VERSION ""

NS_ :

BS_:

BU_: Instrumentation Vehicle ESR
VAL_TABLE_ VOLVO_SHORT_TRACK_PLANT 1 "Gent" 0 "Torslanda" ;
VAL_TABLE_ Grating_Lobe 1 "Detected" 0 "Not_Detected" ;
VAL_TABLE_ GroupingChanged 1 "GroupingChanged" 0 "GroupingUnchanged" ;
VAL_TABLE_ Oncoming 1 "Oncoming" 0 "NotOncoming" ;
VAL_TABLE_ UPDATED 1 "Updated" 0 "Not_Updated" ;
VAL_TABLE_ FOUND_TARGET 1 "Found" 0 "Not_Found" ;
VAL_TABLE_ FACTORY_ALIGN_STATUS 5 "FAIL_VAR_TOO_LARGE" 4 "FAIL_DEV_TOO_LARGE" 3 "FAIL_NO_TARGET" 2 "SUCCESS" 1 "BUSY" 0 "OFF" ;
VAL_TABLE_ RECOMMEND 1 "Recommend" 0 "Not_Recommend" ;
VAL_TABLE_ SA_TYPE 1 "VOLVO_SHORT_TRACK" 0 "AUTO_OR_DEALER" ;
VAL_TABLE_ ENABLE 1 "Enabled" 0 "Disabled" ;
VAL_TABLE_ CONVERGED 1 "Converged" 0 "Not_Converged" ;
VAL_TABLE_ WHEEL_SLIP 3 "Invalid_3" 2 "Traction_Slip_Control" 1 "Brake_Slip_Control" 0 "No_Control" ;
VAL_TABLE_ TURN_SIGNAL_STATUS 3 "Invalid_3" 2 "Right" 1 "Left" 0 "Off" ;
VAL_TABLE_ DISABLE 1 "Disabled" 0 "Enabled" ;
VAL_TABLE_ SYSTEM_POWER_MODE 7 "7invalid" 6 "TEST" 5 "HOST_SHUTDOWN" 4 "DSP_OFF" 3 "DSP_SHUTDOWN" 2 "RADIATE_ON" 1 "RADIATE_OFF" 0 "DSP_INIT" ;
VAL_TABLE_ Water_Spray_Detected 1 "Spray" 0 "No_Spray" ;
VAL_TABLE_ Bridge 1 "Bridge" 0 "Not_Bridge" ;
VAL_TABLE_ MED_RANGE_MODE 3 "Both_MR_LR_Update" 2 "LR_Update_Only" 1 "MR_Update_Only" 0 "No_MR_LR_Update" ;
VAL_TABLE_ Interface_Version 15 "zInvalid0F" 14 "zInvalid0E" 13 "zInvalid0D" 12 "zInvalid0C" 11 "zInvalid0B" 10 "zInvalid0A" 9 "zInvalid09" 8 "zInvalid08" 7 "zInvalid07" 6 "zInvalid06" 5 "zInvalid05" 4 "zInvalid04" 3 "zInvalid03" 2 "zInvalid02" 1 "ADP_DV1" 0 "TDP" ;
VAL_TABLE_ SIM_STATUS 3 "Coasted" 2 "Updated" 1 "New" 0 "Invalid" ;
VAL_TABLE_ SIM_TRACK_ID 2 "Target_2" 1 "Target_1" 0 "No_Target" ;
VAL_TABLE_ SIM_FUNCTION 7 "All_Stat_RI_FCW_CMbB" 6 "All_Moving_ACC_FCW_CMbB" 5 "CMbB_Stat" 4 "CMbB_Move" 3 "FCW_Stat" 2 "FCW_Move" 1 "RI" 0 "ACC" ;
VAL_TABLE_ UPSIDE_DOWN 1 "Upside_Down" 0 "Right_Side_Up" ;
VAL_TABLE_ MR_LR_MODE 3 "Output MR and LR tracks" 2 "Output only LR-range tracks" 1 "Output only MR-range tracks" 0 "Reserved" ;
VAL_TABLE_ GROUP 3 "Group4" 2 "Group3" 1 "Group2" 0 "Group1" ;
VAL_TABLE_ NODETECT_DETECT 1 "Detect" 0 "No_Detect" ;
VAL_TABLE_ TRACK_STATUS 7 "New_Coasted_Target" 6 "Invalid_Coasted_Target" 5 "Merged_Target" 4 "Coasted_Target" 3 "Updated_Target" 2 "New_Updated_Target" 1 "New_Target" 0 "No_Target" ;
VAL_TABLE_ NOTCROSSING_CROSSING 1 "Crossing" 0 "Not_Crossing" ;
VAL_TABLE_ NOTMOVABLE_MOVABLE 1 "Movable" 0 "Not_Movable" ;
VAL_TABLE_ STATIONARY_MOVING 1 "Moving" 0 "Stationary" ;
VAL_TABLE_ NOTOVERTEMP_OVERTEMP 1 "OverTemp" 0 "Not OverTemp" ;
VAL_TABLE_ NOTBLOCKED_BLOCKED 1 "Blocked" 0 "Not Blocked" ;
VAL_TABLE_ NOTFAIL_FAIL 1 "Failed" 0 "Not Failed" ;
VAL_TABLE_ UNGROUPED_GROUPED 3 "Group_Moving_Stationary" 2 "Group_Stationary_Only" 1 "Group_Moving_Only" 0 "No_Grouping" ;
VAL_TABLE_ FILTERED_RAW 1 "Raw" 0 "Filtered" ;
VAL_TABLE_ OFF_ON 1 "On" 0 "Off" ;
VAL_TABLE_ SW_SIGN 1 "Clockwise" 0 "Counterclockwise" ;
VAL_TABLE_ VALIDITY 1 "Valid" 0 "Invalid" ;
VAL_TABLE_ VEHICLE_SPEED_DIRECTION 1 "Reverse" 0 "Forward" ;

BO_ 3221225472 VECTOR__INDEPENDENT_SIG_MSG: 0 Vector__XXX
 SG_ ITS_DAQ1_data : 0|64@0+ (1,0) [0|0] "" Vector__XXX
 SG_ CAN_RX_MR_LR_MODE : 0|2@0+ (1,0) [0|3] "" Vector__XXX
 SG_ CAN_TX_DELTA_TIME_STAMP : 0|7@0- (1,0) [-64|63] "ms" Vector__XXX
 SG_ CAN_RX_MASTER_CLOCK : 0|16@0+ (1,0) [0|65535] "ms" Vector__XXX
 SG_ CAN_TX_TRACK_LAT_RATE : 0|6@0- (0.25,0) [-8|7.75] "" Vector__XXX
 SG_ CAN_TX_TRACK_BRIDGE_OBJECT : 0|1@0+ (1,0) [0|0] "" Vector__XXX
 SG_ CAN_TX_TRACK_WIDTH : 0|4@0+ (0.5,0) [0|7.5] "m" Vector__XXX
 SG_ CAN_TX_TRACK_STATUS : 0|3@0+ (1,0) [0|7] "" Vector__XXX
 SG_ CAN_TX_TRACK_ROLLING_COUNT : 0|1@0+ (1,0) [0|1] "" Vector__XXX
 SG_ CAN_TX_TRACK_RANGE_RATE : 0|14@0- (0.01,0) [-81.92|81.91] "m/s" Vector__XXX
 SG_ CAN_TX_TRACK_RANGE_ACCEL : 0|10@0- (0.05,0) [-25.6|25.55] "m/s/s" Vector__XXX
 SG_ CAN_TX_TRACK_RANGE : 0|11@0+ (0.1,0) [0|204.7] "m" Vector__XXX
 SG_ CAN_TX_TRACK_MED_RANGE_MODE : 0|2@0+ (1,0) [0|3] "" Vector__XXX
 SG_ CAN_TX_TRACK_ANGLE : 0|10@0- (0.1,0) [-51.2|51.1] "deg" Vector__XXX
 SG_ CAN_TX_TRACK_LAT_RATE : 0|6@0- (0.25,0) [-8|7.75] "" Vector__XXX
 SG_ CAN_TX_TRACK_BRIDGE_OBJECT : 0|1@0+ (1,0) [0|0] "" Vector__XXX
 SG_ CAN_TX_TRACK_WIDTH : 0|4@0+ (0.5,0) [0|7.5] "m" Vector__XXX
 SG_ CAN_TX_TRACK_STATUS : 0|3@0+ (1,0) [0|7] "" Vector__XXX
 SG_ CAN_TX_TRACK_ROLLING_COUNT : 0|1@0+ (1,0) [0|1] "" Vector__XXX
 SG_ CAN_TX_TRACK_RANGE_RATE : 0|14@0- (0.01,0) [-81.92|81.91] "m/s" Vector__XXX
 SG_ CAN_TX_TRACK_RANGE_ACCEL : 0|10@0- (0.05,0) [-25.6|25.55] "m/s/s" Vector__XXX
 SG_ CAN_TX_TRACK_RANGE : 0|11@0+ (0.1,0) [0|204.7] "m" Vector__XXX
 SG_ CAN_TX_TRACK_MED_RANGE_MODE : 0|2@0+ (1,0) [0|3] "" Vector__XXX
 SG_ CAN_TX_TRACK_ANGLE : 0|10@0- (0.1,0) [-51.2|51.1] "deg" Vector__XXX
 SG_ CAN_TX_TRACK_LAT_RATE : 0|6@0- (0.25,0) [-8|7.75] "" Vector__XXX
 SG_ CAN_TX_TRACK_BRIDGE_OBJECT : 0|1@0+ (1,0) [0|0] "" Vector__XXX
 SG_ CAN_TX_TRACK_WIDTH : 0|4@0+ (0.5,0) [0|7.5] "m" Vector__XXX
 SG_ CAN_TX_TRACK_STATUS : 0|3@0+ (1,0) [0|7] "" Vector__XXX
 SG_ CAN_TX_TRACK_ROLLING_COUNT : 0|1@0+ (1,0) [0|1] "" Vector__XXX
 SG_ CAN_TX_TRACK_RANGE_RATE : 0|14@0- (0.01,0) [-81.92|81.91] "m/s" Vector__XXX
 SG_ CAN_TX_TRACK_RANGE_ACCEL : 0|10@0- (0.05,0) [-25.6|25.55] "m/s/s" Vector__XXX
 SG_ CAN_TX_TRACK_RANGE : 0|11@0+ (0.1,0) [0|204.7] "m" Vector__XXX
 SG_ CAN_TX_TRACK_MED_RANGE_MODE : 0|2@0+ (1,0) [0|3] "" Vector__XXX
 SG_ CAN_TX_TRACK_ANGLE : 0|10@0- (0.1,0) [-51.2|51.1] "deg" Vector__XXX
 SG_ CAN_TX_TRACK_LAT_RATE : 0|6@0- (0.25,0) [-8|7.75] "" Vector__XXX
 SG_ CAN_TX_TRACK_BRIDGE_OBJECT : 0|1@0+ (1,0) [0|0] "" Vector__XXX
 SG_ CAN_TX_TRACK_WIDTH : 0|4@0+ (0.5,0) [0|7.5] "m" Vector__XXX
 SG_ CAN_TX_TRACK_STATUS : 0|3@0+ (1,0) [0|7] "" Vector__XXX
 SG_ CAN_TX_TRACK_ROLLING_COUNT : 0|1@0+ (1,0) [0|1] "" Vector__XXX
 SG_ CAN_TX_TRACK_RANGE_RATE : 0|14@0- (0.01,0) [-81.92|81.91] "m/s" Vector__XXX
 SG_ CAN_TX_TRACK_RANGE_ACCEL : 0|10@0- (0.05,0) [-25.6|25.55] "m/s/s" Vector__XXX
 SG_ CAN_TX_TRACK_RANGE : 0|11@0+ (0.1,0) [0|204.7] "m" Vector__XXX
 SG_ CAN_TX_TRACK_MED_RANGE_MODE : 0|2@0+ (1,0) [0|3] "" Vector__XXX
 SG_ CAN_TX_TRACK_ANGLE : 0|10@0- (0.1,0) [-51.2|51.1] "deg" Vector__XXX
 SG_ CAN_TX_TRACK_LAT_RATE : 0|6@0- (0.25,0) [-8|7.75] "" Vector__XXX
 SG_ CAN_TX_TRACK_BRIDGE_OBJECT : 0|1@0+ (1,0) [0|0] "" Vector__XXX
 SG_ CAN_TX_TRACK_WIDTH : 0|4@0+ (0.5,0) [0|7.5] "m" Vector__XXX
 SG_ CAN_TX_TRACK_STATUS : 0|3@0+ (1,0) [0|7] "" Vector__XXX
 SG_ CAN_TX_TRACK_ROLLING_COUNT : 0|1@0+ (1,0) [0|1] "" Vector__XXX
 SG_ CAN_TX_TRACK_RANGE_RATE : 0|14@0- (0.01,0) [-81.92|81.91] "m/s" Vector__XXX
 SG_ CAN_TX_TRACK_RANGE_ACCEL : 0|10@0- (0.05,0) [-25.6|25.55] "m/s/s" Vector__XXX
 SG_ CAN_TX_TRACK_RANGE : 0|11@0+ (0.1,0) [0|204.7] "m" Vector__XXX
 SG_ CAN_TX_TRACK_MED_RANGE_MODE : 0|2@0+ (1,0) [0|3] "" Vector__XXX
 SG_ CAN_TX_TRACK_ANGLE : 0|10@0- (0.1,0) [-51.2|51.1] "deg" Vector__XXX
 SG_ CAN_TX_TRACK_LAT_RATE : 0|6@0- (0.25,0) [-8|7.75] "" Vector__XXX
 SG_ CAN_TX_TRACK_BRIDGE_OBJECT : 0|1@0+ (1,0) [0|0] "" Vector__XXX
 SG_ CAN_TX_TRACK_WIDTH : 0|4@0+ (0.5,0) [0|7.5] "m" Vector__XXX
 SG_ CAN_TX_TRACK_STATUS : 0|3@0+ (1,0) [0|7] "" Vector__XXX
 SG_ CAN_TX_TRACK_ROLLING_COUNT : 0|1@0+ (1,0) [0|1] "" Vector__XXX
 SG_ CAN_TX_TRACK_RANGE_RATE : 0|14@0- (0.01,0) [-81.92|81.91] "m/s" Vector__XXX
 SG_ CAN_TX_TRACK_RANGE_ACCEL : 0|10@0- (0.05,0) [-25.6|25.55] "m/s/s" Vector__XXX
 SG_ CAN_TX_TRACK_RANGE : 0|11@0+ (0.1,0) [0|204.7] "m" Vector__XXX
 SG_ CAN_TX_TRACK_MED_RANGE_MODE : 0|2@0+ (1,0) [0|3] "" Vector__XXX
 SG_ CAN_TX_TRACK_ANGLE : 0|10@0- (0.1,0) [-51.2|51.1] "deg" Vector__XXX
 SG_ CAN_TX_TRACK_LAT_RATE : 0|6@0- (0.25,0) [-8|7.75] "" Vector__XXX
 SG_ CAN_TX_TRACK_BRIDGE_OBJECT : 0|1@0+ (1,0) [0|0] "" Vector__XXX
 SG_ CAN_TX_TRACK_WIDTH : 0|4@0+ (0.5,0) [0|7.5] "m" Vector__XXX
 SG_ CAN_TX_TRACK_STATUS : 0|3@0+ (1,0) [0|7] "" Vector__XXX
 SG_ CAN_TX_TRACK_ROLLING_COUNT : 0|1@0+ (1,0) [0|1] "" Vector__XXX
 SG_ CAN_TX_TRACK_RANGE_RATE : 0|14@0- (0.01,0) [-81.92|81.91] "m/s" Vector__XXX
 SG_ CAN_TX_TRACK_RANGE_ACCEL : 0|10@0- (0.05,0) [-25.6|25.55] "m/s/s" Vector__XXX
 SG_ CAN_TX_TRACK_RANGE : 0|11@0+ (0.1,0) [0|204.7] "m" Vector__XXX
 SG_ CAN_TX_TRACK_MED_RANGE_MODE : 0|2@0+ (1,0) [0|3] "" Vector__XXX
 SG_ CAN_TX_TRACK_ANGLE : 0|10@0- (0.1,0) [-51.2|51.1] "deg" Vector__XXX
 SG_ CAN_TX_TRACK_LAT_RATE : 0|6@0- (0.25,0) [-8|7.75] "" Vector__XXX
 SG_ CAN_TX_TRACK_BRIDGE_OBJECT : 0|1@0+ (1,0) [0|0] "" Vector__XXX
 SG_ CAN_TX_TRACK_WIDTH : 0|4@0+ (0.5,0) [0|7.5] "m" Vector__XXX
 SG_ CAN_TX_TRACK_STATUS : 0|3@0+ (1,0) [0|7] "" Vector__XXX
 SG_ CAN_TX_TRACK_ROLLING_COUNT : 0|1@0+ (1,0) [0|1] "" Vector__XXX
 SG_ CAN_TX_TRACK_RANGE_RATE : 0|14@0- (0.01,0) [-81.92|81.91] "m/s" Vector__XXX
 SG_ CAN_TX_TRACK_RANGE_ACCEL : 0|10@0- (0.05,0) [-25.6|25.55] "m/s/s" Vector__XXX
 SG_ CAN_TX_TRACK_RANGE : 0|11@0+ (0.1,0) [0|204.7] "m" Vector__XXX
 SG_ CAN_TX_TRACK_MED_RANGE_MODE : 0|2@0+ (1,0) [0|3] "" Vector__XXX
 SG_ CAN_TX_TRACK_ANGLE : 0|10@0- (0.1,0) [-51.2|51.1] "deg" Vector__XXX
 SG_ CAN_TX_TRACK_LAT_RATE : 0|6@0- (0.25,0) [-8|7.75] "" Vector__XXX
 SG_ CAN_TX_TRACK_BRIDGE_OBJECT : 0|1@0+ (1,0) [0|0] "" Vector__XXX
 SG_ CAN_TX_TRACK_WIDTH : 0|4@0+ (0.5,0) [0|7.5] "m" Vector__XXX
 SG_ CAN_TX_TRACK_STATUS : 0|3@0+ (1,0) [0|7] "" Vector__XXX
 SG_ CAN_TX_TRACK_ROLLING_COUNT : 0|1@0+ (1,0) [0|1] "" Vector__XXX
 SG_ CAN_TX_TRACK_RANGE_RATE : 0|14@0- (0.01,0) [-81.92|81.91] "m/s" Vector__XXX
 SG_ CAN_TX_TRACK_RANGE_ACCEL : 0|10@0- (0.05,0) [-25.6|25.55] "m/s/s" Vector__XXX
 SG_ CAN_TX_TRACK_RANGE : 0|11@0+ (0.1,0) [0|204.7] "m" Vector__XXX
 SG_ CAN_TX_TRACK_MED_RANGE_MODE : 0|2@0+ (1,0) [0|3] "" Vector__XXX
 SG_ CAN_TX_TRACK_ANGLE : 0|10@0- (0.1,0) [-51.2|51.1] "deg" Vector__XXX
 SG_ CAN_TX_TRACK_LAT_RATE : 0|6@0- (0.25,0) [-8|7.75] "" Vector__XXX
 SG_ CAN_TX_TRACK_BRIDGE_OBJECT : 0|1@0+ (1,0) [0|0] "" Vector__XXX
 SG_ CAN_TX_TRACK_WIDTH : 0|4@0+ (0.5,0) [0|7.5] "m" Vector__XXX
 SG_ CAN_TX_TRACK_STATUS : 0|3@0+ (1,0) [0|7] "" Vector__XXX
 SG_ CAN_TX_TRACK_ROLLING_COUNT : 0|1@0+ (1,0) [0|1] "" Vector__XXX
 SG_ CAN_TX_TRACK_RANGE_RATE : 0|14@0- (0.01,0) [-81.92|81.91] "m/s" Vector__XXX
 SG_ CAN_TX_TRACK_RANGE_ACCEL : 0|10@0- (0.05,0) [-25.6|25.55] "m/s/s" Vector__XXX
 SG_ CAN_TX_TRACK_RANGE : 0|11@0+ (0.1,0) [0|204.7] "m" Vector__XXX
 SG_ CAN_TX_TRACK_MED_RANGE_MODE : 0|2@0+ (1,0) [0|3] "" Vector__XXX
 SG_ CAN_TX_TRACK_ANGLE : 0|10@0- (0.1,0) [-51.2|51.1] "deg" Vector__XXX
 SG_ CAN_TX_TRACK_LAT_RATE : 0|6@0- (0.25,0) [-8|7.75] "" Vector__XXX
 SG_ CAN_TX_TRACK_BRIDGE_OBJECT : 0|1@0+ (1,0) [0|0] "" Vector__XXX
 SG_ CAN_TX_TRACK_WIDTH : 0|4@0+ (0.5,0) [0|7.5] "m" Vector__XXX
 SG_ CAN_TX_TRACK_STATUS : 0|3@0+ (1,0) [0|7] "" Vector__XXX
 SG_ CAN_TX_TRACK_ROLLING_COUNT : 0|1@0+ (1,0) [0|1] "" Vector__XXX
 SG_ CAN_TX_TRACK_RANGE_RATE : 0|14@0- (0.01,0) [-81.92|81.91] "m/s" Vector__XXX
 SG_ CAN_TX_TRACK_RANGE_ACCEL : 0|10@0- (0.05,0) [-25.6|25.55] "m/s/s" Vector__XXX
 SG_ CAN_TX_TRACK_RANGE : 0|11@0+ (0.1,0) [0|204.7] "m" Vector__XXX
 SG_ CAN_TX_TRACK_MED_RANGE_MODE : 0|2@0+ (1,0) [0|3] "" Vector__XXX
 SG_ CAN_TX_TRACK_ANGLE : 0|10@0- (0.1,0) [-51.2|51.1] "deg" Vector__XXX
 SG_ CAN_TX_TRACK_LAT_RATE : 0|6@0- (0.25,0) [-8|7.75] "" Vector__XXX
 SG_ CAN_TX_TRACK_BRIDGE_OBJECT : 0|1@0+ (1,0) [0|0] "" Vector__XXX
 SG_ CAN_TX_TRACK_WIDTH : 0|4@0+ (0.5,0) [0|7.5] "m" Vector__XXX
 SG_ CAN_TX_TRACK_STATUS : 0|3@0+ (1,0) [0|7] "" Vector__XXX
 SG_ CAN_TX_TRACK_ROLLING_COUNT : 0|1@0+ (1,0) [0|1] "" Vector__XXX
 SG_ CAN_TX_TRACK_RANGE_RATE : 0|14@0- (0.01,0) [-81.92|81.91] "m/s" Vector__XXX
 SG_ CAN_TX_TRACK_RANGE_ACCEL : 0|10@0- (0.05,0) [-25.6|25.55] "m/s/s" Vector__XXX
 SG_ CAN_TX_TRACK_RANGE : 0|11@0+ (0.1,0) [0|204.7] "m" Vector__XXX
 SG_ CAN_TX_TRACK_MED_RANGE_MODE : 0|2@0+ (1,0) [0|3] "" Vector__XXX
 SG_ CAN_TX_TRACK_ANGLE : 0|10@0- (0.1,0) [-51.2|51.1] "deg" Vector__XXX
 SG_ CAN_TX_TRACK_LAT_RATE : 0|6@0- (0.25,0) [-8|7.75] "" Vector__XXX
 SG_ CAN_TX_TRACK_BRIDGE_OBJECT : 0|1@0+ (1,0) [0|0] "" Vector__XXX
 SG_ CAN_TX_TRACK_WIDTH : 0|4@0+ (0.5,0) [0|7.5] "m" Vector__XXX
 SG_ CAN_TX_TRACK_STATUS : 0|3@0+ (1,0) [0|7] "" Vector__XXX
 SG_ CAN_TX_TRACK_ROLLING_COUNT : 0|1@0+ (1,0) [0|1] "" Vector__XXX
 SG_ CAN_TX_TRACK_RANGE_RATE : 0|14@0- (0.01,0) [-81.92|81.91] "m/s" Vector__XXX
 SG_ CAN_TX_TRACK_RANGE_ACCEL : 0|10@0- (0.05,0) [-25.6|25.55] "m/s/s" Vector__XXX
 SG_ CAN_TX_TRACK_RANGE : 0|11@0+ (0.1,0) [0|204.7] "m" Vector__XXX
 SG_ CAN_TX_TRACK_MED_RANGE_MODE : 0|2@0+ (1,0) [0|3] "" Vector__XXX
 SG_ CAN_TX_TRACK_ANGLE : 0|10@0- (0.1,0) [-51.2|51.1] "deg" Vector__XXX
 SG_ CAN_TX_TRACK_LAT_RATE : 0|6@0- (0.25,0) [-8|7.75] "" Vector__XXX
 SG_ CAN_TX_TRACK_BRIDGE_OBJECT : 0|1@0+ (1,0) [0|0] "" Vector__XXX
 SG_ CAN_TX_TRACK_WIDTH : 0|4@0+ (0.5,0) [0|7.5] "m" Vector__XXX
 SG_ CAN_TX_TRACK_STATUS : 0|3@0+ (1,0) [0|7] "" Vector__XXX
 SG_ CAN_TX_TRACK_ROLLING_COUNT : 0|1@0+ (1,0) [0|1] "" Vector__XXX
 SG_ CAN_TX_TRACK_RANGE_RATE : 0|14@0- (0.01,0) [-81.92|81.91] "m/s" Vector__XXX
 SG_ CAN_TX_TRACK_RANGE_ACCEL : 0|10@0- (0.05,0) [-25.6|25.55] "m/s/s" Vector__XXX
 SG_ CAN_TX_TRACK_RANGE : 0|11@0+ (0.1,0) [0|204.7] "m" Vector__XXX
 SG_ CAN_TX_TRACK_MED_RANGE_MODE : 0|2@0+ (1,0) [0|3] "" Vector__XXX
 SG_ CAN_TX_TRACK_ANGLE : 0|10@0- (0.1,0) [-51.2|51.1] "deg" Vector__XXX
 SG_ CAN_TX_TRACK_LAT_RATE : 0|6@0- (0.25,0) [-8|7.75] "" Vector__XXX
 SG_ CAN_TX_TRACK_BRIDGE_OBJECT : 0|1@0+ (1,0) [0|0] "" Vector__XXX
 SG_ CAN_TX_TRACK_WIDTH : 0|4@0+ (0.5,0) [0|7.5] "m" Vector__XXX
 SG_ CAN_TX_TRACK_STATUS : 0|3@0+ (1,0) [0|7] "" Vector__XXX
 SG_ CAN_TX_TRACK_ROLLING_COUNT : 0|1@0+ (1,0) [0|1] "" Vector__XXX
 SG_ CAN_TX_TRACK_RANGE_RATE : 0|14@0- (0.01,0) [-81.92|81.91] "m/s" Vector__XXX
 SG_ CAN_TX_TRACK_RANGE_ACCEL : 0|10@0- (0.05,0) [-25.6|25.55] "m/s/s" Vector__XXX
 SG_ CAN_TX_TRACK_RANGE : 0|11@0+ (0.1,0) [0|204.7] "m" Vector__XXX
 SG_ CAN_TX_TRACK_MED_RANGE_MODE : 0|2@0+ (1,0) [0|3] "" Vector__XXX
 SG_ CAN_TX_TRACK_ANGLE : 0|10@0- (0.1,0) [-51.2|51.1] "deg" Vector__XXX
 SG_ CAN_TX_TRACK_LAT_RATE : 0|6@0- (0.25,0) [-8|7.75] "" Vector__XXX
 SG_ CAN_TX_TRACK_BRIDGE_OBJECT : 0|1@0+ (1,0) [0|0] "" Vector__XXX
 SG_ CAN_TX_TRACK_WIDTH : 0|4@0+ (0.5,0) [0|7.5] "m" Vector__XXX
 SG_ CAN_TX_TRACK_STATUS : 0|3@0+ (1,0) [0|7] "" Vector__XXX
 SG_ CAN_TX_TRACK_ROLLING_COUNT : 0|1@0+ (1,0) [0|1] "" Vector__XXX
 SG_ CAN_TX_TRACK_RANGE_RATE : 0|14@0- (0.01,0) [-81.92|81.91] "m/s" Vector__XXX
 SG_ CAN_TX_TRACK_RANGE_ACCEL : 0|10@0- (0.05,0) [-25.6|25.55] "m/s/s" Vector__XXX
 SG_ CAN_TX_TRACK_RANGE : 0|11@0+ (0.1,0) [0|204.7] "m" Vector__XXX
 SG_ CAN_TX_TRACK_MED_RANGE_MODE : 0|2@0+ (1,0) [0|3] "" Vector__XXX
 SG_ CAN_TX_TRACK_ANGLE : 0|10@0- (0.1,0) [-51.2|51.1] "deg" Vector__XXX
 SG_ CAN_TX_TRACK_LAT_RATE : 0|6@0- (0.25,0) [-8|7.75] "" Vector__XXX
 SG_ CAN_TX_TRACK_BRIDGE_OBJECT : 0|1@0+ (1,0) [0|0] "" Vector__XXX
 SG_ CAN_TX_TRACK_WIDTH : 0|4@0+ (0.5,0) [0|7.5] "m" Vector__XXX
 SG_ CAN_TX_TRACK_STATUS : 0|3@0+ (1,0) [0|7] "" Vector__XXX
 SG_ CAN_TX_TRACK_ROLLING_COUNT : 0|1@0+ (1,0) [0|1] "" Vector__XXX
 SG_ CAN_TX_TRACK_RANGE_RATE : 0|14@0- (0.01,0) [-81.92|81.91] "m/s" Vector__XXX
 SG_ CAN_TX_TRACK_RANGE_ACCEL : 0|10@0- (0.05,0) [-25.6|25.55] "m/s/s" Vector__XXX
 SG_ CAN_TX_TRACK_RANGE : 0|11@0+ (0.1,0) [0|204.7] "m" Vector__XXX
 SG_ CAN_TX_TRACK_MED_RANGE_MODE : 0|2@0+ (1,0) [0|3] "" Vector__XXX
 SG_ CAN_TX_TRACK_ANGLE : 0|10@0- (0.1,0) [-51.2|51.1] "deg" Vector__XXX
 SG_ CAN_TX_TRACK_LAT_RATE : 0|6@0- (0.25,0) [-8|7.75] "" Vector__XXX
 SG_ CAN_TX_TRACK_BRIDGE_OBJECT : 0|1@0+ (1,0) [0|0] "" Vector__XXX
 SG_ CAN_TX_TRACK_WIDTH : 0|4@0+ (0.5,0) [0|7.5] "m" Vector__XXX
 SG_ CAN_TX_TRACK_STATUS : 0|3@0+ (1,0) [0|7] "" Vector__XXX
 SG_ CAN_TX_TRACK_ROLLING_COUNT : 0|1@0+ (1,0) [0|1] "" Vector__XXX
 SG_ CAN_TX_TRACK_RANGE_RATE : 0|14@0- (0.01,0) [-81.92|81.91] "m/s" Vector__XXX
 SG_ CAN_TX_TRACK_RANGE_ACCEL : 0|10@0- (0.05,0) [-25.6|25.55] "m/s/s" Vector__XXX
 SG_ CAN_TX_TRACK_RANGE : 0|11@0+ (0.1,0) [0|204.7] "m" Vector__XXX
 SG_ CAN_TX_TRACK_MED_RANGE_MODE : 0|2@0+ (1,0) [0|3] "" Vector__XXX
 SG_ CAN_TX_TRACK_ANGLE : 0|10@0- (0.1,0) [-51.2|51.1] "deg" Vector__XXX
 SG_ CAN_TX_TRACK_LAT_RATE : 0|6@0- (0.25,0) [-8|7.75] "" Vector__XXX
 SG_ CAN_TX_TRACK_BRIDGE_OBJECT : 0|1@0+ (1,0) [0|0] "" Vector__XXX
 SG_ CAN_TX_TRACK_WIDTH : 0|4@0+ (0.5,0) [0|7.5] "m" Vector__XXX
 SG_ CAN_TX_TRACK_STATUS : 0|3@0+ (1,0) [0|7] "" Vector__XXX
 SG_ CAN_TX_TRACK_ROLLING_COUNT : 0|1@0+ (1,0) [0|1] "" Vector__XXX
 SG_ CAN_TX_TRACK_RANGE_RATE : 0|14@0- (0.01,0) [-81.92|81.91] "m/s" Vector__XXX
 SG_ CAN_TX_TRACK_RANGE_ACCEL : 0|10@0- (0.05,0) [-25.6|25.55] "m/s/s" Vector__XXX
 SG_ CAN_TX_TRACK_RANGE : 0|11@0+ (0.1,0) [0|204.7] "m" Vector__XXX
 SG_ CAN_TX_TRACK_MED_RANGE_MODE : 0|2@0+ (1,0) [0|3] "" Vector__XXX
 SG_ CAN_TX_TRACK_ANGLE : 0|10@0- (0.1,0) [-51.2|51.1] "deg" Vector__XXX
 SG_ CAN_TX_TRACK_LAT_RATE : 0|6@0- (0.25,0) [-8|7.75] "" Vector__XXX
 SG_ CAN_TX_TRACK_BRIDGE_OBJECT : 0|1@0+ (1,0) [0|0] "" Vector__XXX
 SG_ CAN_TX_TRACK_WIDTH : 0|4@0+ (0.5,0) [0|7.5] "m" Vector__XXX
 SG_ CAN_TX_TRACK_STATUS : 0|3@0+ (1,0) [0|7] "" Vector__XXX
 SG_ CAN_TX_TRACK_ROLLING_COUNT : 0|1@0+ (1,0) [0|1] "" Vector__XXX
 SG_ CAN_TX_TRACK_RANGE_RATE : 0|14@0- (0.01,0) [-81.92|81.91] "m/s" Vector__XXX
 SG_ CAN_TX_TRACK_RANGE_ACCEL : 0|10@0- (0.05,0) [-25.6|25.55] "m/s/s" Vector__XXX
 SG_ CAN_TX_TRACK_RANGE : 0|11@0+ (0.1,0) [0|204.7] "m" Vector__XXX
 SG_ CAN_TX_TRACK_MED_RANGE_MODE : 0|2@0+ (1,0) [0|3] "" Vector__XXX
 SG_ CAN_TX_TRACK_ANGLE : 0|10@0- (0.1,0) [-51.2|51.1] "deg" Vector__XXX
 SG_ CAN_TX_TRACK_LAT_RATE : 0|6@0- (0.25,0) [-8|7.75] "" Vector__XXX
 SG_ CAN_TX_TRACK_BRIDGE_OBJECT : 0|1@0+ (1,0) [0|0] "" Vector__XXX
 SG_ CAN_TX_TRACK_WIDTH : 0|4@0+ (0.5,0) [0|7.5] "m" Vector__XXX
 SG_ CAN_TX_TRACK_STATUS : 0|3@0+ (1,0) [0|7] "" Vector__XXX
 SG_ CAN_TX_TRACK_ROLLING_COUNT : 0|1@0+ (1,0) [0|1] "" Vector__XXX
 SG_ CAN_TX_TRACK_RANGE_RATE : 0|14@0- (0.01,0) [-81.92|81.91] "m/s" Vector__XXX
 SG_ CAN_TX_TRACK_RANGE_ACCEL : 0|10@0- (0.05,0) [-25.6|25.55] "m/s/s" Vector__XXX
 SG_ CAN_TX_TRACK_RANGE : 0|11@0+ (0.1,0) [0|204.7] "m" Vector__XXX
 SG_ CAN_TX_TRACK_MED_RANGE_MODE : 0|2@0+ (1,0) [0|3] "" Vector__XXX
 SG_ CAN_TX_TRACK_ANGLE : 0|10@0- (0.1,0) [-51.2|51.1] "deg" Vector__XXX
 SG_ CAN_TX_TRACK_LAT_RATE : 0|6@0- (0.25,0) [-8|7.75] "" Vector__XXX
 SG_ CAN_TX_TRACK_BRIDGE_OBJECT : 0|1@0+ (1,0) [0|0] "" Vector__XXX
 SG_ CAN_TX_TRACK_WIDTH : 0|4@0+ (0.5,0) [0|7.5] "m" Vector__XXX
 SG_ CAN_TX_TRACK_STATUS : 0|3@0+ (1,0) [0|7] "" Vector__XXX
 SG_ CAN_TX_TRACK_ROLLING_COUNT : 0|1@0+ (1,0) [0|1] "" Vector__XXX
 SG_ CAN_TX_TRACK_RANGE_RATE : 0|14@0- (0.01,0) [-81.92|81.91] "m/s" Vector__XXX
 SG_ CAN_TX_TRACK_RANGE_ACCEL : 0|10@0- (0.05,0) [-25.6|25.55] "m/s/s" Vector__XXX
 SG_ CAN_TX_TRACK_RANGE : 0|11@0+ (0.1,0) [0|204.7] "m" Vector__XXX
 SG_ CAN_TX_TRACK_MED_RANGE_MODE : 0|2@0+ (1,0) [0|3] "" Vector__XXX
 SG_ CAN_TX_TRACK_ANGLE : 0|10@0- (0.1,0) [-51.2|51.1] "deg" Vector__XXX
 SG_ CAN_TX_TRACK_LAT_RATE : 0|6@0- (0.25,0) [-8|7.75] "" Vector__XXX
 SG_ CAN_TX_TRACK_BRIDGE_OBJECT : 0|1@0+ (1,0) [0|0] "" Vector__XXX
 SG_ CAN_TX_TRACK_WIDTH : 0|4@0+ (0.5,0) [0|7.5] "m" Vector__XXX
 SG_ CAN_TX_TRACK_STATUS : 0|3@0+ (1,0) [0|7] "" Vector__XXX
 SG_ CAN_TX_TRACK_ROLLING_COUNT : 0|1@0+ (1,0) [0|1] "" Vector__XXX
 SG_ CAN_TX_TRACK_RANGE_RATE : 0|14@0- (0.01,0) [-81.92|81.91] "m/s" Vector__XXX
 SG_ CAN_TX_TRACK_RANGE_ACCEL : 0|10@0- (0.05,0) [-25.6|25.55] "m/s/s" Vector__XXX
 SG_ CAN_TX_TRACK_RANGE : 0|11@0+ (0.1,0) [0|204.7] "m" Vector__XXX
 SG_ CAN_TX_TRACK_MED_RANGE_MODE : 0|2@0+ (1,0) [0|3] "" Vector__XXX
 SG_ CAN_TX_TRACK_ANGLE : 0|10@0- (0.1,0) [-51.2|51.1] "deg" Vector__XXX
 SG_ CAN_TX_TRACK_LAT_RATE : 0|6@0- (0.25,0) [-8|7.75] "" Vector__XXX
 SG_ CAN_TX_TRACK_BRIDGE_OBJECT : 0|1@0+ (1,0) [0|0] "" Vector__XXX
 SG_ CAN_TX_TRACK_WIDTH : 0|4@0+ (0.5,0) [0|7.5] "m" Vector__XXX
 SG_ CAN_TX_TRACK_STATUS : 0|3@0+ (1,0) [0|7] "" Vector__XXX
 SG_ CAN_TX_TRACK_ROLLING_COUNT : 0|1@0+ (1,0) [0|1] "" Vector__XXX
 SG_ CAN_TX_TRACK_RANGE_RATE : 0|14@0- (0.01,0) [-81.92|81.91] "m/s" Vector__XXX
 SG_ CAN_TX_TRACK_RANGE_ACCEL : 0|10@0- (0.05,0) [-25.6|25.55] "m/s/s" Vector__XXX
 SG_ CAN_TX_TRACK_RANGE : 0|11@0+ (0.1,0) [0|204.7] "m" Vector__XXX
 SG_ CAN_TX_TRACK_MED_RANGE_MODE : 0|2@0+ (1,0) [0|3] "" Vector__XXX
 SG_ CAN_TX_TRACK_ANGLE : 0|10@0- (0.1,0) [-51.2|51.1] "deg" Vector__XXX
 SG_ CAN_TX_TRACK_LAT_RATE : 0|6@0- (0.25,0) [-8|7.75] "" Vector__XXX
 SG_ CAN_TX_TRACK_BRIDGE_OBJECT : 0|1@0+ (1,0) [0|0] "" Vector__XXX
 SG_ CAN_TX_TRACK_WIDTH : 0|4@0+ (0.5,0) [0|7.5] "m" Vector__XXX
 SG_ CAN_TX_TRACK_STATUS : 0|3@0+ (1,0) [0|7] "" Vector__XXX
 SG_ CAN_TX_TRACK_ROLLING_COUNT : 0|1@0+ (1,0) [0|1] "" Vector__XXX
 SG_ CAN_TX_TRACK_RANGE_RATE : 0|14@0- (0.01,0) [-81.92|81.91] "m/s" Vector__XXX
 SG_ CAN_TX_TRACK_RANGE_ACCEL : 0|10@0- (0.05,0) [-25.6|25.55] "m/s/s" Vector__XXX
 SG_ CAN_TX_TRACK_RANGE : 0|11@0+ (0.1,0) [0|204.7] "m" Vector__XXX
 SG_ CAN_TX_TRACK_MED_RANGE_MODE : 0|2@0+ (1,0) [0|3] "" Vector__XXX
 SG_ CAN_TX_TRACK_ANGLE : 0|10@0- (0.1,0) [-51.2|51.1] "deg" Vector__XXX
 SG_ CAN_TX_TRACK_LAT_RATE : 0|6@0- (0.25,0) [-8|7.75] "" Vector__XXX
 SG_ CAN_TX_TRACK_BRIDGE_OBJECT : 0|1@0+ (1,0) [0|0] "" Vector__XXX
 SG_ CAN_TX_TRACK_WIDTH : 0|4@0+ (0.5,0) [0|7.5] "m" Vector__XXX
 SG_ CAN_TX_TRACK_STATUS : 0|3@0+ (1,0) [0|7] "" Vector__XXX
 SG_ CAN_TX_TRACK_ROLLING_COUNT : 0|1@0+ (1,0) [0|1] "" Vector__XXX
 SG_ CAN_TX_TRACK_RANGE_RATE : 0|14@0- (0.01,0) [-81.92|81.91] "m/s" Vector__XXX
 SG_ CAN_TX_TRACK_RANGE_ACCEL : 0|10@0- (0.05,0) [-25.6|25.55] "m/s/s" Vector__XXX
 SG_ CAN_TX_TRACK_RANGE : 0|11@0+ (0.1,0) [0|204.7] "m" Vector__XXX
 SG_ CAN_TX_TRACK_MED_RANGE_MODE : 0|2@0+ (1,0) [0|3] "" Vector__XXX
 SG_ CAN_TX_TRACK_ANGLE : 0|10@0- (0.1,0) [-51.2|51.1] "deg" Vector__XXX
 SG_ CAN_TX_TRACK_LAT_RATE : 0|6@0- (0.25,0) [-8|7.75] "" Vector__XXX
 SG_ CAN_TX_TRACK_BRIDGE_OBJECT : 0|1@0+ (1,0) [0|0] "" Vector__XXX
 SG_ CAN_TX_TRACK_WIDTH : 0|4@0+ (0.5,0) [0|7.5] "m" Vector__XXX
 SG_ CAN_TX_TRACK_STATUS : 0|3@0+ (1,0) [0|7] "" Vector__XXX
 SG_ CAN_TX_TRACK_ROLLING_COUNT : 0|1@0+ (1,0) [0|1] "" Vector__XXX
 SG_ CAN_TX_TRACK_RANGE_RATE : 0|14@0- (0.01,0) [-81.92|81.91] "m/s" Vector__XXX
 SG_ CAN_TX_TRACK_RANGE_ACCEL : 0|10@0- (0.05,0) [-25.6|25.55] "m/s/s" Vector__XXX
 SG_ CAN_TX_TRACK_RANGE : 0|11@0+ (0.1,0) [0|204.7] "m" Vector__XXX
 SG_ CAN_TX_TRACK_MED_RANGE_MODE : 0|2@0+ (1,0) [0|3] "" Vector__XXX
 SG_ CAN_TX_TRACK_ANGLE : 0|10@0- (0.1,0) [-51.2|51.1] "deg" Vector__XXX
 SG_ CAN_TX_TRACK_LAT_RATE : 0|6@0- (0.25,0) [-8|7.75] "" Vector__XXX
 SG_ CAN_TX_TRACK_BRIDGE_OBJECT : 0|1@0+ (1,0) [0|0] "" Vector__XXX
 SG_ CAN_TX_TRACK_WIDTH : 0|4@0+ (0.5,0) [0|7.5] "m" Vector__XXX
 SG_ CAN_TX_TRACK_STATUS : 0|3@0+ (1,0) [0|7] "" Vector__XXX
 SG_ CAN_TX_TRACK_ROLLING_COUNT : 0|1@0+ (1,0) [0|1] "" Vector__XXX
 SG_ CAN_TX_TRACK_RANGE_RATE : 0|14@0- (0.01,0) [-81.92|81.91] "m/s" Vector__XXX
 SG_ CAN_TX_TRACK_RANGE_ACCEL : 0|10@0- (0.05,0) [-25.6|25.55] "m/s/s" Vector__XXX
 SG_ CAN_TX_TRACK_RANGE : 0|11@0+ (0.1,0) [0|204.7] "m" Vector__XXX
 SG_ CAN_TX_TRACK_MED_RANGE_MODE : 0|2@0+ (1,0) [0|3] "" Vector__XXX
 SG_ CAN_TX_TRACK_ANGLE : 0|10@0- (0.1,0) [-51.2|51.1] "deg" Vector__XXX
 SG_ CAN_TX_TRACK_LAT_RATE : 0|6@0- (0.25,0) [-8|7.75] "" Vector__XXX
 SG_ CAN_TX_TRACK_BRIDGE_OBJECT : 0|1@0+ (1,0) [0|0] "" Vector__XXX
 SG_ CAN_TX_TRACK_WIDTH : 0|4@0+ (0.5,0) [0|7.5] "m" Vector__XXX
 SG_ CAN_TX_TRACK_STATUS : 0|3@0+ (1,0) [0|7] "" Vector__XXX
 SG_ CAN_TX_TRACK_ROLLING_COUNT : 0|1@0+ (1,0) [0|1] "" Vector__XXX
 SG_ CAN_TX_TRACK_RANGE_RATE : 0|14@0- (0.01,0) [-81.92|81.91] "m/s" Vector__XXX
 SG_ CAN_TX_TRACK_RANGE_ACCEL : 0|10@0- (0.05,0) [-25.6|25.55] "m/s/s" Vector__XXX
 SG_ CAN_TX_TRACK_RANGE : 0|11@0+ (0.1,0) [0|204.7] "m" Vector__XXX
 SG_ CAN_TX_TRACK_MED_RANGE_MODE : 0|2@0+ (1,0) [0|3] "" Vector__XXX
 SG_ CAN_TX_TRACK_ANGLE : 0|10@0- (0.1,0) [-51.2|51.1] "deg" Vector__XXX
 SG_ CAN_TX_TRACK_LAT_RATE : 0|6@0- (0.25,0) [-8|7.75] "" Vector__XXX
 SG_ CAN_TX_TRACK_BRIDGE_OBJECT : 0|1@0+ (1,0) [0|0] "" Vector__XXX
 SG_ CAN_TX_TRACK_WIDTH : 0|4@0+ (0.5,0) [0|7.5] "m" Vector__XXX
 SG_ CAN_TX_TRACK_STATUS : 0|3@0+ (1,0) [0|7] "" Vector__XXX
 SG_ CAN_TX_TRACK_ROLLING_COUNT : 0|1@0+ (1,0) [0|1] "" Vector__XXX
 SG_ CAN_TX_TRACK_RANGE_RATE : 0|14@0- (0.01,0) [-81.92|81.91] "m/s" Vector__XXX
 SG_ CAN_TX_TRACK_RANGE_ACCEL : 0|10@0- (0.05,0) [-25.6|25.55] "m/s/s" Vector__XXX
 SG_ CAN_TX_TRACK_RANGE : 0|11@0+ (0.1,0) [0|204.7] "m" Vector__XXX
 SG_ CAN_TX_TRACK_MED_RANGE_MODE : 0|2@0+ (1,0) [0|3] "" Vector__XXX
 SG_ CAN_TX_TRACK_ANGLE : 0|10@0- (0.1,0) [-51.2|51.1] "deg" Vector__XXX
 SG_ CAN_TX_TRACK_LAT_RATE : 0|6@0- (0.25,0) [-8|7.75] "" Vector__XXX
 SG_ CAN_TX_TRACK_BRIDGE_OBJECT : 0|1@0+ (1,0) [0|0] "" Vector__XXX
 SG_ CAN_TX_TRACK_WIDTH : 0|4@0+ (0.5,0) [0|7.5] "m" Vector__XXX
 SG_ CAN_TX_TRACK_STATUS : 0|3@0+ (1,0) [0|7] "" Vector__XXX
 SG_ CAN_TX_TRACK_ROLLING_COUNT : 0|1@0+ (1,0) [0|1] "" Vector__XXX
 SG_ CAN_TX_TRACK_RANGE_RATE : 0|14@0- (0.01,0) [-81.92|81.91] "m/s" Vector__XXX
 SG_ CAN_TX_TRACK_RANGE_ACCEL : 0|10@0- (0.05,0) [-25.6|25.55] "m/s/s" Vector__XXX
 SG_ CAN_TX_TRACK_RANGE : 0|11@0+ (0.1,0) [0|204.7] "m" Vector__XXX
 SG_ CAN_TX_TRACK_MED_RANGE_MODE : 0|2@0+ (1,0) [0|3] "" Vector__XXX
 SG_ CAN_TX_TRACK_ANGLE : 0|10@0- (0.1,0) [-51.2|51.1] "deg" Vector__XXX
 SG_ CAN_TX_TRACK_LAT_RATE : 0|6@0- (0.25,0) [-8|7.75] "" Vector__XXX
 SG_ CAN_TX_TRACK_BRIDGE_OBJECT : 0|1@0+ (1,0) [0|0] "" Vector__XXX
 SG_ CAN_TX_TRACK_WIDTH : 0|4@0+ (0.5,0) [0|7.5] "m" Vector__XXX
 SG_ CAN_TX_TRACK_STATUS : 0|3@0+ (1,0) [0|7] "" Vector__XXX
 SG_ CAN_TX_TRACK_ROLLING_COUNT : 0|1@0+ (1,0) [0|1] "" Vector__XXX
 SG_ CAN_TX_TRACK_RANGE_RATE : 0|14@0- (0.01,0) [-81.92|81.91] "m/s" Vector__XXX
 SG_ CAN_TX_TRACK_RANGE_ACCEL : 0|10@0- (0.05,0) [-25.6|25.55] "m/s/s" Vector__XXX
 SG_ CAN_TX_TRACK_RANGE : 0|11@0+ (0.1,0) [0|204.7] "m" Vector__XXX
 SG_ CAN_TX_TRACK_MED_RANGE_MODE : 0|2@0+ (1,0) [0|3] "" Vector__XXX
 SG_ CAN_TX_TRACK_ANGLE : 0|10@0- (0.1,0) [-51.2|51.1] "deg" Vector__XXX
 SG_ CAN_TX_TRACK_LAT_RATE : 0|6@0- (0.25,0) [-8|7.75] "" Vector__XXX
 SG_ CAN_TX_TRACK_BRIDGE_OBJECT : 0|1@0+ (1,0) [0|0] "" Vector__XXX
 SG_ CAN_TX_TRACK_WIDTH : 0|4@0+ (0.5,0) [0|7.5] "m" Vector__XXX
 SG_ CAN_TX_TRACK_STATUS : 0|3@0+ (1,0) [0|7] "" Vector__XXX
 SG_ CAN_TX_TRACK_ROLLING_COUNT : 0|1@0+ (1,0) [0|1] "" Vector__XXX
 SG_ CAN_TX_TRACK_RANGE_RATE : 0|14@0- (0.01,0) [-81.92|81.91] "m/s" Vector__XXX
 SG_ CAN_TX_TRACK_RANGE_ACCEL : 0|10@0- (0.05,0) [-25.6|25.55] "m/s/s" Vector__XXX
 SG_ CAN_TX_TRACK_RANGE : 0|11@0+ (0.1,0) [0|204.7] "m" Vector__XXX
 SG_ CAN_TX_TRACK_MED_RANGE_MODE : 0|2@0+ (1,0) [0|3] "" Vector__XXX
 SG_ CAN_TX_TRACK_ANGLE : 0|10@0- (0.1,0) [-51.2|51.1] "deg" Vector__XXX
 SG_ CAN_TX_TRACK_LAT_RATE : 0|6@0- (0.25,0) [-8|7.75] "" Vector__XXX
 SG_ CAN_TX_TRACK_BRIDGE_OBJECT : 0|1@0+ (1,0) [0|0] "" Vector__XXX
 SG_ CAN_TX_TRACK_WIDTH : 0|4@0+ (0.5,0) [0|7.5] "m" Vector__XXX
 SG_ CAN_TX_TRACK_STATUS : 0|3@0+ (1,0) [0|7] "" Vector__XXX
 SG_ CAN_TX_TRACK_ROLLING_COUNT : 0|1@0+ (1,0) [0|1] "" Vector__XXX
 SG_ CAN_TX_TRACK_RANGE_RATE : 0|14@0- (0.01,0) [-81.92|81.91] "m/s" Vector__XXX
 SG_ CAN_TX_TRACK_RANGE_ACCEL : 0|10@0- (0.05,0) [-25.6|25.55] "m/s/s" Vector__XXX
 SG_ CAN_TX_TRACK_RANGE : 0|11@0+ (0.1,0) [0|204.7] "m" Vector__XXX
 SG_ CAN_TX_TRACK_MED_RANGE_MODE : 0|2@0+ (1,0) [0|3] "" Vector__XXX
 SG_ CAN_TX_TRACK_ANGLE : 0|10@0- (0.1,0) [-51.2|51.1] "deg" Vector__XXX
 SG_ CAN_TX_TRACK_LAT_RATE : 0|6@0- (0.25,0) [-8|7.75] "" Vector__XXX
 SG_ CAN_TX_TRACK_BRIDGE_OBJECT : 0|1@0+ (1,0) [0|0] "" Vector__XXX
 SG_ CAN_TX_TRACK_WIDTH : 0|4@0+ (0.5,0) [0|7.5] "m" Vector__XXX
 SG_ CAN_TX_TRACK_STATUS : 0|3@0+ (1,0) [0|7] "" Vector__XXX
 SG_ CAN_TX_TRACK_ROLLING_COUNT : 0|1@0+ (1,0) [0|1] "" Vector__XXX
 SG_ CAN_TX_TRACK_RANGE_RATE : 0|14@0- (0.01,0) [-81.92|81.91] "m/s" Vector__XXX
 SG_ CAN_TX_TRACK_RANGE_ACCEL : 0|10@0- (0.05,0) [-25.6|25.55] "m/s/s" Vector__XXX
 SG_ CAN_TX_TRACK_RANGE : 0|11@0+ (0.1,0) [0|204.7] "m" Vector__XXX
 SG_ CAN_TX_TRACK_MED_RANGE_MODE : 0|2@0+ (1,0) [0|3] "" Vector__XXX
 SG_ CAN_TX_TRACK_ANGLE : 0|10@0- (0.1,0) [-51.2|51.1] "deg" Vector__XXX
 SG_ CAN_TX_TRACK_LAT_RATE : 0|6@0- (0.25,0) [-8|7.75] "" Vector__XXX
 SG_ CAN_TX_TRACK_BRIDGE_OBJECT : 0|1@0+ (1,0) [0|0] "" Vector__XXX
 SG_ CAN_TX_TRACK_WIDTH : 0|4@0+ (0.5,0) [0|7.5] "m" Vector__XXX
 SG_ CAN_TX_TRACK_STATUS : 0|3@0+ (1,0) [0|7] "" Vector__XXX
 SG_ CAN_TX_TRACK_ROLLING_COUNT : 0|1@0+ (1,0) [0|1] "" Vector__XXX
 SG_ CAN_TX_TRACK_RANGE_RATE : 0|14@0- (0.01,0) [-81.92|81.91] "m/s" Vector__XXX
 SG_ CAN_TX_TRACK_RANGE_ACCEL : 0|10@0- (0.05,0) [-25.6|25.55] "m/s/s" Vector__XXX
 SG_ CAN_TX_TRACK_RANGE : 0|11@0+ (0.1,0) [0|204.7] "m" Vector__XXX
 SG_ CAN_TX_TRACK_MED_RANGE_MODE : 0|2@0+ (1,0) [0|3] "" Vector__XXX
 SG_ CAN_TX_TRACK_ANGLE : 0|10@0- (0.1,0) [-51.2|51.1] "deg" Vector__XXX
 SG_ CAN_TX_TRACK_LAT_RATE : 0|6@0- (0.25,0) [-8|7.75] "" Vector__XXX
 SG_ CAN_TX_TRACK_BRIDGE_OBJECT : 0|1@0+ (1,0) [0|0] "" Vector__XXX
 SG_ CAN_TX_TRACK_WIDTH : 0|4@0+ (0.5,0) [0|7.5] "m" Vector__XXX
 SG_ CAN_TX_TRACK_STATUS : 0|3@0+ (1,0) [0|7] "" Vector__XXX
 SG_ CAN_TX_TRACK_ROLLING_COUNT : 0|1@0+ (1,0) [0|1] "" Vector__XXX
 SG_ CAN_TX_TRACK_RANGE_RATE : 0|14@0- (0.01,0) [-81.92|81.91] "m/s" Vector__XXX
 SG_ CAN_TX_TRACK_RANGE_ACCEL : 0|10@0- (0.05,0) [-25.6|25.55] "m/s/s" Vector__XXX
 SG_ CAN_TX_TRACK_RANGE : 0|11@0+ (0.1,0) [0|204.7] "m" Vector__XXX
 SG_ CAN_TX_TRACK_MED_RANGE_MODE : 0|2@0+ (1,0) [0|3] "" Vector__XXX
 SG_ CAN_TX_TRACK_ANGLE : 0|10@0- (0.1,0) [-51.2|51.1] "deg" Vector__XXX
 SG_ CAN_TX_TRACK_LAT_RATE : 0|6@0- (0.25,0) [-8|7.75] "" Vector__XXX
 SG_ CAN_TX_TRACK_BRIDGE_OBJECT : 0|1@0+ (1,0) [0|0] "" Vector__XXX
 SG_ CAN_TX_TRACK_WIDTH : 0|4@0+ (0.5,0) [0|7.5] "m" Vector__XXX
 SG_ CAN_TX_TRACK_STATUS : 0|3@0+ (1,0) [0|7] "" Vector__XXX
 SG_ CAN_TX_TRACK_ROLLING_COUNT : 0|1@0+ (1,0) [0|1] "" Vector__XXX
 SG_ CAN_TX_TRACK_RANGE_RATE : 0|14@0- (0.01,0) [-81.92|81.91] "m/s" Vector__XXX
 SG_ CAN_TX_TRACK_RANGE_ACCEL : 0|10@0- (0.05,0) [-25.6|25.55] "m/s/s" Vector__XXX
 SG_ CAN_TX_TRACK_RANGE : 0|11@0+ (0.1,0) [0|204.7] "m" Vector__XXX
 SG_ CAN_TX_TRACK_MED_RANGE_MODE : 0|2@0+ (1,0) [0|3] "" Vector__XXX
 SG_ CAN_TX_TRACK_ANGLE : 0|10@0- (0.1,0) [-51.2|51.1] "deg" Vector__XXX
 SG_ CAN_TX_TRACK_LAT_RATE : 0|6@0- (0.25,0) [-8|7.75] "" Vector__XXX
 SG_ CAN_TX_TRACK_BRIDGE_OBJECT : 0|1@0+ (1,0) [0|0] "" Vector__XXX
 SG_ CAN_TX_TRACK_WIDTH : 0|4@0+ (0.5,0) [0|7.5] "m" Vector__XXX
 SG_ CAN_TX_TRACK_STATUS : 0|3@0+ (1,0) [0|7] "" Vector__XXX
 SG_ CAN_TX_TRACK_ROLLING_COUNT : 0|1@0+ (1,0) [0|1] "" Vector__XXX
 SG_ CAN_TX_TRACK_RANGE_RATE : 0|14@0- (0.01,0) [-81.92|81.91] "m/s" Vector__XXX
 SG_ CAN_TX_TRACK_RANGE_ACCEL : 0|10@0- (0.05,0) [-25.6|25.55] "m/s/s" Vector__XXX
 SG_ CAN_TX_TRACK_RANGE : 0|11@0+ (0.1,0) [0|204.7] "m" Vector__XXX
 SG_ CAN_TX_TRACK_MED_RANGE_MODE : 0|2@0+ (1,0) [0|3] "" Vector__XXX
 SG_ CAN_TX_TRACK_ANGLE : 0|10@0- (0.1,0) [-51.2|51.1] "deg" Vector__XXX
 SG_ CAN_TX_TRACK_LAT_RATE : 0|6@0- (0.25,0) [-8|7.75] "" Vector__XXX
 SG_ CAN_TX_TRACK_BRIDGE_OBJECT : 0|1@0+ (1,0) [0|0] "" Vector__XXX
 SG_ CAN_TX_TRACK_WIDTH : 0|4@0+ (0.5,0) [0|7.5] "m" Vector__XXX
 SG_ CAN_TX_TRACK_STATUS : 0|3@0+ (1,0) [0|7] "" Vector__XXX
 SG_ CAN_TX_TRACK_ROLLING_COUNT : 0|1@0+ (1,0) [0|1] "" Vector__XXX
 SG_ CAN_TX_TRACK_RANGE_RATE : 0|14@0- (0.01,0) [-81.92|81.91] "m/s" Vector__XXX
 SG_ CAN_TX_TRACK_RANGE_ACCEL : 0|10@0- (0.05,0) [-25.6|25.55] "m/s/s" Vector__XXX
 SG_ CAN_TX_TRACK_RANGE : 0|11@0+ (0.1,0) [0|204.7] "m" Vector__XXX
 SG_ CAN_TX_TRACK_MED_RANGE_MODE : 0|2@0+ (1,0) [0|3] "" Vector__XXX
 SG_ CAN_TX_TRACK_ANGLE : 0|10@0- (0.1,0) [-51.2|51.1] "deg" Vector__XXX
 SG_ CAN_TX_TRACK_LAT_RATE : 0|6@0- (0.25,0) [-8|7.75] "" Vector__XXX
 SG_ CAN_TX_TRACK_BRIDGE_OBJECT : 0|1@0+ (1,0) [0|0] "" Vector__XXX
 SG_ CAN_TX_TRACK_WIDTH : 0|4@0+ (0.5,0) [0|7.5] "m" Vector__XXX
 SG_ CAN_TX_TRACK_STATUS : 0|3@0+ (1,0) [0|7] "" Vector__XXX
 SG_ CAN_TX_TRACK_ROLLING_COUNT : 0|1@0+ (1,0) [0|1] "" Vector__XXX
 SG_ CAN_TX_TRACK_RANGE_RATE : 0|14@0- (0.01,0) [-81.92|81.91] "m/s" Vector__XXX
 SG_ CAN_TX_TRACK_RANGE_ACCEL : 0|10@0- (0.05,0) [-25.6|25.55] "m/s/s" Vector__XXX
 SG_ CAN_TX_TRACK_RANGE : 0|11@0+ (0.1,0) [0|204.7] "m" Vector__XXX
 SG_ CAN_TX_TRACK_MED_RANGE_MODE : 0|2@0+ (1,0) [0|3] "" Vector__XXX
 SG_ CAN_TX_TRACK_ANGLE : 0|10@0- (0.1,0) [-51.2|51.1] "deg" Vector__XXX
 SG_ CAN_TX_TRACK_LAT_RATE : 0|6@0- (0.25,0) [-8|7.75] "" Vector__XXX
 SG_ CAN_TX_TRACK_BRIDGE_OBJECT : 0|1@0+ (1,0) [0|0] "" Vector__XXX
 SG_ CAN_TX_TRACK_WIDTH : 0|4@0+ (0.5,0) [0|7.5] "m" Vector__XXX
 SG_ CAN_TX_TRACK_STATUS : 0|3@0+ (1,0) [0|7] "" Vector__XXX
 SG_ CAN_TX_TRACK_ROLLING_COUNT : 0|1@0+ (1,0) [0|1] "" Vector__XXX
 SG_ CAN_TX_TRACK_RANGE_RATE : 0|14@0- (0.01,0) [-81.92|81.91] "m/s" Vector__XXX
 SG_ CAN_TX_TRACK_RANGE_ACCEL : 0|10@0- (0.05,0) [-25.6|25.55] "m/s/s" Vector__XXX
 SG_ CAN_TX_TRACK_RANGE : 0|11@0+ (0.1,0) [0|204.7] "m" Vector__XXX
 SG_ CAN_TX_TRACK_MED_RANGE_MODE : 0|2@0+ (1,0) [0|3] "" Vector__XXX
 SG_ CAN_TX_TRACK_ANGLE : 0|10@0- (0.1,0) [-51.2|51.1] "deg" Vector__XXX
 SG_ CAN_TX_TRACK_LAT_RATE : 0|6@0- (0.25,0) [-8|7.75] "" Vector__XXX
 SG_ CAN_TX_TRACK_BRIDGE_OBJECT : 0|1@0+ (1,0) [0|0] "" Vector__XXX
 SG_ CAN_TX_TRACK_WIDTH : 0|4@0+ (0.5,0) [0|7.5] "m" Vector__XXX
 SG_ CAN_TX_TRACK_STATUS : 0|3@0+ (1,0) [0|7] "" Vector__XXX
 SG_ CAN_TX_TRACK_ROLLING_COUNT : 0|1@0+ (1,0) [0|1] "" Vector__XXX
 SG_ CAN_TX_TRACK_RANGE_RATE : 0|14@0- (0.01,0) [-81.92|81.91] "m/s" Vector__XXX
 SG_ CAN_TX_TRACK_RANGE_ACCEL : 0|10@0- (0.05,0) [-25.6|25.55] "m/s/s" Vector__XXX
 SG_ CAN_TX_TRACK_RANGE : 0|11@0+ (0.1,0) [0|204.7] "m" Vector__XXX
 SG_ CAN_TX_TRACK_MED_RANGE_MODE : 0|2@0+ (1,0) [0|3] "" Vector__XXX
 SG_ CAN_TX_TRACK_ANGLE : 0|10@0- (0.1,0) [-51.2|51.1] "deg" Vector__XXX
 SG_ CAN_TX_TRACK_LAT_RATE : 0|6@0- (0.25,0) [-8|7.75] "" Vector__XXX
 SG_ CAN_TX_TRACK_BRIDGE_OBJECT : 0|1@0+ (1,0) [0|0] "" Vector__XXX
 SG_ CAN_TX_TRACK_WIDTH : 0|4@0+ (0.5,0) [0|7.5] "m" Vector__XXX
 SG_ CAN_TX_TRACK_STATUS : 0|3@0+ (1,0) [0|7] "" Vector__XXX
 SG_ CAN_TX_TRACK_ROLLING_COUNT : 0|1@0+ (1,0) [0|1] "" Vector__XXX
 SG_ CAN_TX_TRACK_RANGE_RATE : 0|14@0- (0.01,0) [-81.92|81.91] "m/s" Vector__XXX
 SG_ CAN_TX_TRACK_RANGE_ACCEL : 0|10@0- (0.05,0) [-25.6|25.55] "m/s/s" Vector__XXX
 SG_ CAN_TX_TRACK_RANGE : 0|11@0+ (0.1,0) [0|204.7] "m" Vector__XXX
 SG_ CAN_TX_TRACK_MED_RANGE_MODE : 0|2@0+ (1,0) [0|3] "" Vector__XXX
 SG_ CAN_TX_TRACK_ANGLE : 0|10@0- (0.1,0) [-51.2|51.1] "deg" Vector__XXX
 SG_ CAN_TX_TRACK_LAT_RATE : 0|6@0- (0.25,0) [-8|7.75] "" Vector__XXX
 SG_ CAN_TX_TRACK_BRIDGE_OBJECT : 0|1@0+ (1,0) [0|0] "" Vector__XXX
 SG_ CAN_TX_TRACK_WIDTH : 0|4@0+ (0.5,0) [0|7.5] "m" Vector__XXX
 SG_ CAN_TX_TRACK_STATUS : 0|3@0+ (1,0) [0|7] "" Vector__XXX
 SG_ CAN_TX_TRACK_ROLLING_COUNT : 0|1@0+ (1,0) [0|1] "" Vector__XXX
 SG_ CAN_TX_TRACK_RANGE_RATE : 0|14@0- (0.01,0) [-81.92|81.91] "m/s" Vector__XXX
 SG_ CAN_TX_TRACK_RANGE_ACCEL : 0|10@0- (0.05,0) [-25.6|25.55] "m/s/s" Vector__XXX
 SG_ CAN_TX_TRACK_RANGE : 0|11@0+ (0.1,0) [0|204.7] "m" Vector__XXX
 SG_ CAN_TX_TRACK_MED_RANGE_MODE : 0|2@0+ (1,0) [0|3] "" Vector__XXX
 SG_ CAN_TX_TRACK_ANGLE : 0|10@0- (0.1,0) [-51.2|51.1] "deg" Vector__XXX
 SG_ CAN_TX_TRACK_LAT_RATE : 0|6@0- (0.25,0) [-8|7.75] "" Vector__XXX
 SG_ CAN_TX_TRACK_BRIDGE_OBJECT : 0|1@0+ (1,0) [0|0] "" Vector__XXX
 SG_ CAN_TX_TRACK_WIDTH : 0|4@0+ (0.5,0) [0|7.5] "m" Vector__XXX
 SG_ CAN_TX_TRACK_STATUS : 0|3@0+ (1,0) [0|7] "" Vector__XXX
 SG_ CAN_TX_TRACK_ROLLING_COUNT : 0|1@0+ (1,0) [0|1] "" Vector__XXX
 SG_ CAN_TX_TRACK_RANGE_RATE : 0|14@0- (0.01,0) [-81.92|81.91] "m/s" Vector__XXX
 SG_ CAN_TX_TRACK_RANGE_ACCEL : 0|10@0- (0.05,0) [-25.6|25.55] "m/s/s" Vector__XXX
 SG_ CAN_TX_TRACK_RANGE : 0|11@0+ (0.1,0) [0|204.7] "m" Vector__XXX
 SG_ CAN_TX_TRACK_MED_RANGE_MODE : 0|2@0+ (1,0) [0|3] "" Vector__XXX
 SG_ CAN_TX_TRACK_ANGLE : 0|10@0- (0.1,0) [-51.2|51.1] "deg" Vector__XXX
 SG_ CAN_TX_TRACK_LAT_RATE : 0|6@0- (0.25,0) [-8|7.75] "" Vector__XXX
 SG_ CAN_TX_TRACK_BRIDGE_OBJECT : 0|1@0+ (1,0) [0|0] "" Vector__XXX
 SG_ CAN_TX_TRACK_WIDTH : 0|4@0+ (0.5,0) [0|7.5] "m" Vector__XXX
 SG_ CAN_TX_TRACK_STATUS : 0|3@0+ (1,0) [0|7] "" Vector__XXX
 SG_ CAN_TX_TRACK_ROLLING_COUNT : 0|1@0+ (1,0) [0|1] "" Vector__XXX
 SG_ CAN_TX_TRACK_RANGE_RATE : 0|14@0- (0.01,0) [-81.92|81.91] "m/s" Vector__XXX
 SG_ CAN_TX_TRACK_RANGE_ACCEL : 0|10@0- (0.05,0) [-25.6|25.55] "m/s/s" Vector__XXX
 SG_ CAN_TX_TRACK_RANGE : 0|11@0+ (0.1,0) [0|204.7] "m" Vector__XXX
 SG_ CAN_TX_TRACK_MED_RANGE_MODE : 0|2@0+ (1,0) [0|3] "" Vector__XXX
 SG_ CAN_TX_TRACK_ANGLE : 0|10@0- (0.1,0) [-51.2|51.1] "deg" Vector__XXX
 SG_ CAN_TX_TRACK_LAT_RATE : 0|6@0- (0.25,0) [-8|7.75] "" Vector__XXX
 SG_ CAN_TX_TRACK_BRIDGE_OBJECT : 0|1@0+ (1,0) [0|0] "" Vector__XXX
 SG_ CAN_TX_TRACK_WIDTH : 0|4@0+ (0.5,0) [0|7.5] "m" Vector__XXX
 SG_ CAN_TX_TRACK_STATUS : 0|3@0+ (1,0) [0|7] "" Vector__XXX
 SG_ CAN_TX_TRACK_ROLLING_COUNT : 0|1@0+ (1,0) [0|1] "" Vector__XXX
 SG_ CAN_TX_TRACK_RANGE_RATE : 0|14@0- (0.01,0) [-81.92|81.91] "m/s" Vector__XXX
 SG_ CAN_TX_TRACK_RANGE_ACCEL : 0|10@0- (0.05,0) [-25.6|25.55] "m/s/s" Vector__XXX
 SG_ CAN_TX_TRACK_RANGE : 0|11@0+ (0.1,0) [0|204.7] "m" Vector__XXX
 SG_ CAN_TX_TRACK_MED_RANGE_MODE : 0|2@0+ (1,0) [0|3] "" Vector__XXX
 SG_ CAN_TX_TRACK_ANGLE : 0|10@0- (0.1,0) [-51.2|51.1] "deg" Vector__XXX
 SG_ CAN_TX_TRACK_LAT_RATE : 0|6@0- (0.25,0) [-8|7.75] "" Vector__XXX
 SG_ CAN_TX_TRACK_BRIDGE_OBJECT : 0|1@0+ (1,0) [0|0] "" Vector__XXX
 SG_ CAN_TX_TRACK_WIDTH : 0|4@0+ (0.5,0) [0|7.5] "m" Vector__XXX
 SG_ CAN_TX_TRACK_STATUS : 0|3@0+ (1,0) [0|7] "" Vector__XXX
 SG_ CAN_TX_TRACK_ROLLING_COUNT : 0|1@0+ (1,0) [0|1] "" Vector__XXX
 SG_ CAN_TX_TRACK_RANGE_RATE : 0|14@0- (0.01,0) [-81.92|81.91] "m/s" Vector__XXX
 SG_ CAN_TX_TRACK_RANGE_ACCEL : 0|10@0- (0.05,0) [-25.6|25.55] "m/s/s" Vector__XXX
 SG_ CAN_TX_TRACK_RANGE : 0|11@0+ (0.1,0) [0|204.7] "m" Vector__XXX
 SG_ CAN_TX_TRACK_MED_RANGE_MODE : 0|2@0+ (1,0) [0|3] "" Vector__XXX
 SG_ CAN_TX_TRACK_ANGLE : 0|10@0- (0.1,0) [-51.2|51.1] "deg" Vector__XXX
 SG_ CAN_TX_TRACK_LAT_RATE : 0|6@0- (0.25,0) [-8|7.75] "" Vector__XXX
 SG_ CAN_TX_TRACK_BRIDGE_OBJECT : 0|1@0+ (1,0) [0|0] "" Vector__XXX
 SG_ CAN_TX_TRACK_WIDTH : 0|4@0+ (0.5,0) [0|7.5] "m" Vector__XXX
 SG_ CAN_TX_TRACK_STATUS : 0|3@0+ (1,0) [0|7] "" Vector__XXX
 SG_ CAN_TX_TRACK_ROLLING_COUNT : 0|1@0+ (1,0) [0|1] "" Vector__XXX
 SG_ CAN_TX_TRACK_RANGE_RATE : 0|14@0- (0.01,0) [-81.92|81.91] "m/s" Vector__XXX
 SG_ CAN_TX_TRACK_RANGE_ACCEL : 0|10@0- (0.05,0) [-25.6|25.55] "m/s/s" Vector__XXX
 SG_ CAN_TX_TRACK_RANGE : 0|11@0+ (0.1,0) [0|204.7] "m" Vector__XXX
 SG_ CAN_TX_TRACK_MED_RANGE_MODE : 0|2@0+ (1,0) [0|3] "" Vector__XXX
 SG_ CAN_TX_TRACK_ANGLE : 0|10@0- (0.1,0) [-51.2|51.1] "deg" Vector__XXX
 SG_ CAN_TX_TRACK_LAT_RATE : 0|6@0- (0.25,0) [-8|7.75] "" Vector__XXX
 SG_ CAN_TX_TRACK_BRIDGE_OBJECT : 0|1@0+ (1,0) [0|0] "" Vector__XXX
 SG_ CAN_TX_TRACK_WIDTH : 0|4@0+ (0.5,0) [0|7.5] "m" Vector__XXX
 SG_ CAN_TX_TRACK_STATUS : 0|3@0+ (1,0) [0|7] "" Vector__XXX
 SG_ CAN_TX_TRACK_ROLLING_COUNT : 0|1@0+ (1,0) [0|1] "" Vector__XXX
 SG_ CAN_TX_TRACK_RANGE_RATE : 0|14@0- (0.01,0) [-81.92|81.91] "m/s" Vector__XXX
 SG_ CAN_TX_TRACK_RANGE_ACCEL : 0|10@0- (0.05,0) [-25.6|25.55] "m/s/s" Vector__XXX
 SG_ CAN_TX_TRACK_RANGE : 0|11@0+ (0.1,0) [0|204.7] "m" Vector__XXX
 SG_ CAN_TX_TRACK_MED_RANGE_MODE : 0|2@0+ (1,0) [0|3] "" Vector__XXX
 SG_ CAN_TX_TRACK_ANGLE : 0|10@0- (0.1,0) [-51.2|51.1] "deg" Vector__XXX
 SG_ CAN_TX_TRACK_LAT_RATE : 0|6@0- (0.25,0) [-8|7.75] "" Vector__XXX
 SG_ CAN_TX_TRACK_BRIDGE_OBJECT : 0|1@0+ (1,0) [0|0] "" Vector__XXX
 SG_ CAN_TX_TRACK_WIDTH : 0|4@0+ (0.5,0) [0|7.5] "m" Vector__XXX
 SG_ CAN_TX_TRACK_STATUS : 0|3@0+ (1,0) [0|7] "" Vector__XXX
 SG_ CAN_TX_TRACK_ROLLING_COUNT : 0|1@0+ (1,0) [0|1] "" Vector__XXX
 SG_ CAN_TX_TRACK_RANGE_RATE : 0|14@0- (0.01,0) [-81.92|81.91] "m/s" Vector__XXX
 SG_ CAN_TX_TRACK_RANGE_ACCEL : 0|10@0- (0.05,0) [-25.6|25.55] "m/s/s" Vector__XXX
 SG_ CAN_TX_TRACK_RANGE : 0|11@0+ (0.1,0) [0|204.7] "m" Vector__XXX
 SG_ CAN_TX_TRACK_MED_RANGE_MODE : 0|2@0+ (1,0) [0|3] "" Vector__XXX
 SG_ CAN_TX_TRACK_ANGLE : 0|10@0- (0.1,0) [-51.2|51.1] "deg" Vector__XXX
 SG_ CAN_TX_TRACK_LAT_RATE : 0|6@0- (0.25,0) [-8|7.75] "" Vector__XXX
 SG_ CAN_TX_TRACK_BRIDGE_OBJECT : 0|1@0+ (1,0) [0|0] "" Vector__XXX
 SG_ CAN_TX_TRACK_WIDTH : 0|4@0+ (0.5,0) [0|7.5] "m" Vector__XXX
 SG_ CAN_TX_TRACK_STATUS : 0|3@0+ (1,0) [0|7] "" Vector__XXX
 SG_ CAN_TX_TRACK_ROLLING_COUNT : 0|1@0+ (1,0) [0|1] "" Vector__XXX
 SG_ CAN_TX_TRACK_RANGE_RATE : 0|14@0- (0.01,0) [-81.92|81.91] "m/s" Vector__XXX
 SG_ CAN_TX_TRACK_RANGE_ACCEL : 0|10@0- (0.05,0) [-25.6|25.55] "m/s/s" Vector__XXX
 SG_ CAN_TX_TRACK_RANGE : 0|11@0+ (0.1,0) [0|204.7] "m" Vector__XXX
 SG_ CAN_TX_TRACK_MED_RANGE_MODE : 0|2@0+ (1,0) [0|3] "" Vector__XXX
 SG_ CAN_TX_TRACK_ANGLE : 0|10@0- (0.1,0) [-51.2|51.1] "deg" Vector__XXX
 SG_ CAN_TX_TRACK_LAT_RATE : 0|6@0- (0.25,0) [-8|7.75] "" Vector__XXX
 SG_ CAN_TX_TRACK_BRIDGE_OBJECT : 0|1@0+ (1,0) [0|0] "" Vector__XXX
 SG_ CAN_TX_TRACK_WIDTH : 0|4@0+ (0.5,0) [0|7.5] "m" Vector__XXX
 SG_ CAN_TX_TRACK_STATUS : 0|3@0+ (1,0) [0|7] "" Vector__XXX
 SG_ CAN_TX_TRACK_ROLLING_COUNT : 0|1@0+ (1,0) [0|1] "" Vector__XXX
 SG_ CAN_TX_TRACK_RANGE_RATE : 0|14@0- (0.01,0) [-81.92|81.91] "m/s" Vector__XXX
 SG_ CAN_TX_TRACK_RANGE_ACCEL : 0|10@0- (0.05,0) [-25.6|25.55] "m/s/s" Vector__XXX
 SG_ CAN_TX_TRACK_RANGE : 0|11@0+ (0.1,0) [0|204.7] "m" Vector__XXX
 SG_ CAN_TX_TRACK_MED_RANGE_MODE : 0|2@0+ (1,0) [0|3] "" Vector__XXX
 SG_ CAN_TX_TRACK_ANGLE : 0|10@0- (0.1,0) [-51.2|51.1] "deg" Vector__XXX
 SG_ CAN_TX_TRACK_LAT_RATE : 0|6@0- (0.25,0) [-8|7.75] "" Vector__XXX
 SG_ CAN_TX_TRACK_BRIDGE_OBJECT : 0|1@0+ (1,0) [0|0] "" Vector__XXX
 SG_ CAN_TX_TRACK_WIDTH : 0|4@0+ (0.5,0) [0|7.5] "m" Vector__XXX
 SG_ CAN_TX_TRACK_STATUS : 0|3@0+ (1,0) [0|7] "" Vector__XXX
 SG_ CAN_TX_TRACK_ROLLING_COUNT : 0|1@0+ (1,0) [0|1] "" Vector__XXX
 SG_ CAN_TX_TRACK_RANGE_RATE : 0|14@0- (0.01,0) [-81.92|81.91] "m/s" Vector__XXX
 SG_ CAN_TX_TRACK_RANGE_ACCEL : 0|10@0- (0.05,0) [-25.6|25.55] "m/s/s" Vector__XXX
 SG_ CAN_TX_TRACK_RANGE : 0|11@0+ (0.1,0) [0|204.7] "m" Vector__XXX
 SG_ CAN_TX_TRACK_MED_RANGE_MODE : 0|2@0+ (1,0) [0|3] "" Vector__XXX
 SG_ CAN_TX_TRACK_ANGLE : 0|10@0- (0.1,0) [-51.2|51.1] "deg" Vector__XXX
 SG_ CAN_TX_TRACK_LAT_RATE : 0|6@0- (0.25,0) [-8|7.75] "" Vector__XXX
 SG_ CAN_TX_TRACK_BRIDGE_OBJECT : 0|1@0+ (1,0) [0|0] "" Vector__XXX
 SG_ CAN_TX_TRACK_WIDTH : 0|4@0+ (0.5,0) [0|7.5] "m" Vector__XXX
 SG_ CAN_TX_TRACK_STATUS : 0|3@0+ (1,0) [0|7] "" Vector__XXX
 SG_ CAN_TX_TRACK_ROLLING_COUNT : 0|1@0+ (1,0) [0|1] "" Vector__XXX
 SG_ CAN_TX_TRACK_RANGE_RATE : 0|14@0- (0.01,0) [-81.92|81.91] "m/s" Vector__XXX
 SG_ CAN_TX_TRACK_RANGE_ACCEL : 0|10@0- (0.05,0) [-25.6|25.55] "m/s/s" Vector__XXX
 SG_ CAN_TX_TRACK_RANGE : 0|11@0+ (0.1,0) [0|204.7] "m" Vector__XXX
 SG_ CAN_TX_TRACK_MED_RANGE_MODE : 0|2@0+ (1,0) [0|3] "" Vector__XXX
 SG_ CAN_TX_TRACK_ANGLE : 0|10@0- (0.1,0) [-51.2|51.1] "deg" Vector__XXX
 SG_ CAN_TX_TRACK_LAT_RATE : 0|6@0- (0.25,0) [-8|7.75] "" Vector__XXX
 SG_ CAN_TX_TRACK_BRIDGE_OBJECT : 0|1@0+ (1,0) [0|0] "" Vector__XXX
 SG_ CAN_TX_TRACK_WIDTH : 0|4@0+ (0.5,0) [0|7.5] "m" Vector__XXX
 SG_ CAN_TX_TRACK_STATUS : 0|3@0+ (1,0) [0|7] "" Vector__XXX
 SG_ CAN_TX_TRACK_ROLLING_COUNT : 0|1@0+ (1,0) [0|1] "" Vector__XXX
 SG_ CAN_TX_TRACK_RANGE_RATE : 0|14@0- (0.01,0) [-81.92|81.91] "m/s" Vector__XXX
 SG_ CAN_TX_TRACK_RANGE_ACCEL : 0|10@0- (0.05,0) [-25.6|25.55] "m/s/s" Vector__XXX
 SG_ CAN_TX_TRACK_RANGE : 0|11@0+ (0.1,0) [0|204.7] "m" Vector__XXX
 SG_ CAN_TX_TRACK_MED_RANGE_MODE : 0|2@0+ (1,0) [0|3] "" Vector__XXX
 SG_ CAN_TX_TRACK_ANGLE : 0|10@0- (0.1,0) [-51.2|51.1] "deg" Vector__XXX
 SG_ CAN_TX_TRACK_LAT_RATE : 0|6@0- (0.25,0) [-8|7.75] "" Vector__XXX
 SG_ CAN_TX_TRACK_BRIDGE_OBJECT : 0|1@0+ (1,0) [0|0] "" Vector__XXX
 SG_ CAN_TX_TRACK_WIDTH : 0|4@0+ (0.5,0) [0|7.5] "m" Vector__XXX
 SG_ CAN_TX_TRACK_STATUS : 0|3@0+ (1,0) [0|7] "" Vector__XXX
 SG_ CAN_TX_TRACK_ROLLING_COUNT : 0|1@0+ (1,0) [0|1] "" Vector__XXX
 SG_ CAN_TX_TRACK_RANGE_RATE : 0|14@0- (0.01,0) [-81.92|81.91] "m/s" Vector__XXX
 SG_ CAN_TX_TRACK_RANGE_ACCEL : 0|10@0- (0.05,0) [-25.6|25.55] "m/s/s" Vector__XXX
 SG_ CAN_TX_TRACK_RANGE : 0|11@0+ (0.1,0) [0|204.7] "m" Vector__XXX
 SG_ CAN_TX_TRACK_MED_RANGE_MODE : 0|2@0+ (1,0) [0|3] "" Vector__XXX
 SG_ CAN_TX_TRACK_ANGLE : 0|10@0- (0.1,0) [-51.2|51.1] "deg" Vector__XXX
 SG_ CAN_TX_TRACK_LAT_RATE : 0|6@0- (0.25,0) [-8|7.75] "" Vector__XXX
 SG_ CAN_TX_TRACK_BRIDGE_OBJECT : 0|1@0+ (1,0) [0|0] "" Vector__XXX
 SG_ CAN_TX_TRACK_WIDTH : 0|4@0+ (0.5,0) [0|7.5] "m" Vector__XXX
 SG_ CAN_TX_TRACK_STATUS : 0|3@0+ (1,0) [0|7] "" Vector__XXX
 SG_ CAN_TX_TRACK_ROLLING_COUNT : 0|1@0+ (1,0) [0|1] "" Vector__XXX
 SG_ CAN_TX_TRACK_RANGE_RATE : 0|14@0- (0.01,0) [-81.92|81.91] "m/s" Vector__XXX
 SG_ CAN_TX_TRACK_RANGE_ACCEL : 0|10@0- (0.05,0) [-25.6|25.55] "m/s/s" Vector__XXX
 SG_ CAN_TX_TRACK_RANGE : 0|11@0+ (0.1,0) [0|204.7] "m" Vector__XXX
 SG_ CAN_TX_TRACK_MED_RANGE_MODE : 0|2@0+ (1,0) [0|3] "" Vector__XXX
 SG_ CAN_TX_TRACK_ANGLE : 0|10@0- (0.1,0) [-51.2|51.1] "deg" Vector__XXX
 SG_ CAN_TX_TRACK_LAT_RATE : 0|6@0- (0.25,0) [-8|7.75] "" Vector__XXX
 SG_ CAN_TX_TRACK_BRIDGE_OBJECT : 0|1@0+ (1,0) [0|0] "" Vector__XXX
 SG_ CAN_TX_TRACK_WIDTH : 0|4@0+ (0.5,0) [0|7.5] "m" Vector__XXX
 SG_ CAN_TX_TRACK_STATUS : 0|3@0+ (1,0) [0|7] "" Vector__XXX
 SG_ CAN_TX_TRACK_ROLLING_COUNT : 0|1@0+ (1,0) [0|1] "" Vector__XXX
 SG_ CAN_TX_TRACK_RANGE_RATE : 0|14@0- (0.01,0) [-81.92|81.91] "m/s" Vector__XXX
 SG_ CAN_TX_TRACK_RANGE_ACCEL : 0|10@0- (0.05,0) [-25.6|25.55] "m/s/s" Vector__XXX
 SG_ CAN_TX_TRACK_RANGE : 0|11@0+ (0.1,0) [0|204.7] "m" Vector__XXX
 SG_ CAN_TX_TRACK_MED_RANGE_MODE : 0|2@0+ (1,0) [0|3] "" Vector__XXX
 SG_ CAN_TX_TRACK_ANGLE : 0|10@0- (0.1,0) [-51.2|51.1] "deg" Vector__XXX
 SG_ CAN_TX_TRACK_LAT_RATE : 0|6@0- (0.25,0) [-8|7.75] "" Vector__XXX
 SG_ CAN_TX_TRACK_BRIDGE_OBJECT : 0|1@0+ (1,0) [0|0] "" Vector__XXX
 SG_ CAN_TX_TRACK_WIDTH : 0|4@0+ (0.5,0) [0|7.5] "m" Vector__XXX
 SG_ CAN_TX_TRACK_STATUS : 0|3@0+ (1,0) [0|7] "" Vector__XXX
 SG_ CAN_TX_TRACK_ROLLING_COUNT : 0|1@0+ (1,0) [0|1] "" Vector__XXX
 SG_ CAN_TX_TRACK_RANGE_RATE : 0|14@0- (0.01,0) [-81.92|81.91] "m/s" Vector__XXX
 SG_ CAN_TX_TRACK_RANGE_ACCEL : 0|10@0- (0.05,0) [-25.6|25.55] "m/s/s" Vector__XXX
 SG_ CAN_TX_TRACK_RANGE : 0|11@0+ (0.1,0) [0|204.7] "m" Vector__XXX
 SG_ CAN_TX_TRACK_MED_RANGE_MODE : 0|2@0+ (1,0) [0|3] "" Vector__XXX
 SG_ CAN_TX_TRACK_ANGLE : 0|10@0- (0.1,0) [-51.2|51.1] "deg" Vector__XXX
 SG_ CAN_TX_TRACK_LAT_RATE : 0|6@0- (0.25,0) [-8|7.75] "" Vector__XXX
 SG_ CAN_TX_TRACK_BRIDGE_OBJECT : 0|1@0+ (1,0) [0|0] "" Vector__XXX
 SG_ CAN_TX_TRACK_WIDTH : 0|4@0+ (0.5,0) [0|7.5] "m" Vector__XXX
 SG_ CAN_TX_TRACK_STATUS : 0|3@0+ (1,0) [0|7] "" Vector__XXX
 SG_ CAN_TX_TRACK_ROLLING_COUNT : 0|1@0+ (1,0) [0|1] "" Vector__XXX
 SG_ CAN_TX_TRACK_RANGE_RATE : 0|14@0- (0.01,0) [-81.92|81.91] "m/s" Vector__XXX
 SG_ CAN_TX_TRACK_RANGE_ACCEL : 0|10@0- (0.05,0) [-25.6|25.55] "m/s/s" Vector__XXX
 SG_ CAN_TX_TRACK_RANGE : 0|11@0+ (0.1,0) [0|204.7] "m" Vector__XXX
 SG_ CAN_TX_TRACK_MED_RANGE_MODE : 0|2@0+ (1,0) [0|3] "" Vector__XXX
 SG_ CAN_TX_TRACK_ANGLE : 0|10@0- (0.1,0) [-51.2|51.1] "deg" Vector__XXX
 SG_ CAN_TX_TRACK_LAT_RATE : 0|6@0- (0.25,0) [-8|7.75] "" Vector__XXX
 SG_ CAN_TX_TRACK_BRIDGE_OBJECT : 0|1@0+ (1,0) [0|0] "" Vector__XXX
 SG_ CAN_TX_TRACK_WIDTH : 0|4@0+ (0.5,0) [0|7.5] "m" Vector__XXX
 SG_ CAN_TX_TRACK_STATUS : 0|3@0+ (1,0) [0|7] "" Vector__XXX
 SG_ CAN_TX_TRACK_ROLLING_COUNT : 0|1@0+ (1,0) [0|1] "" Vector__XXX
 SG_ CAN_TX_TRACK_RANGE_RATE : 0|14@0- (0.01,0) [-81.92|81.91] "m/s" Vector__XXX
 SG_ CAN_TX_TRACK_RANGE_ACCEL : 0|10@0- (0.05,0) [-25.6|25.55] "m/s/s" Vector__XXX
 SG_ CAN_TX_TRACK_RANGE : 0|11@0+ (0.1,0) [0|204.7] "m" Vector__XXX
 SG_ CAN_TX_TRACK_MED_RANGE_MODE : 0|2@0+ (1,0) [0|3] "" Vector__XXX
 SG_ CAN_TX_TRACK_ANGLE : 0|10@0- (0.1,0) [-51.2|51.1] "deg" Vector__XXX

BO_ 1525 Vehicle6: 8 Vector__XXX
 SG_ CAN_RX_INNER_FUNNEL_OFFSET_RIGHT : 39|8@0- (0.1,0) [-2|10] "m" Vector__XXX
 SG_ CAN_RX_INNER_FUNNEL_OFFSET_LEFT : 31|8@0- (0.1,0) [-2|10] "m" Vector__XXX
 SG_ CAN_VOLVO_FA_RANGE_MAX_SHORT : 23|8@0+ (1,0) [0|255] "m" Vector__XXX
 SG_ CAN_VOLVO_FA_MIN_VSPEED_SHORT : 7|8@0+ (0.125,0) [0|20] "m/s" Vector__XXX
 SG_ CAN_VOLVO_FA_AALIGN_ESTIMATE : 15|8@0+ (0.0625,0) [0|10] "deg" Vector__XXX

BO_ 1512 ESR_Status9: 8 ESR
 SG_ CAN_TX_PATH_ID_ACC_3 : 63|8@0+ (1,0) [0|64] "" Vector__XXX
 SG_ CAN_TX_PATH_ID_ACC_2 : 55|8@0+ (1,0) [0|64] "" Vector__XXX
 SG_ CAN_TX_FILTERED_XOHP_ACC_CIPV : 32|9@0- (0.03125,0) [-8|7.96875] "m" Vector__XXX
 SG_ CAN_TX_WATER_SPRAY_TARGET_ID : 39|7@0+ (1,0) [0|64] "" Vector__XXX
 SG_ CAN_TX_SERIAL_NUM_3RD_BYTE : 31|8@0+ (1,0) [0|0] "" Vector__XXX
 SG_ CAN_TX_SIDESLIP_ANGLE : 9|10@0- (0.125,0) [-64|63.875] "deg" Vector__XXX
 SG_ CAN_TX_AVG_PWR_CWBLKG : 7|12@0+ (1,0) [0|0] "" Vector__XXX

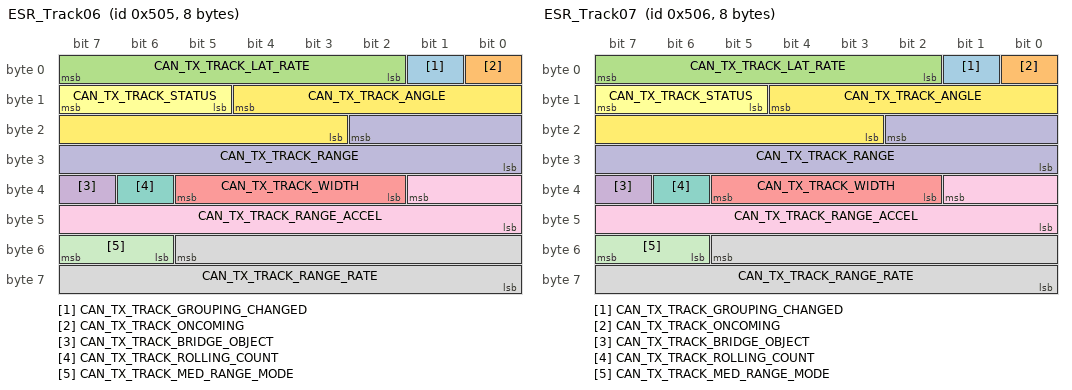
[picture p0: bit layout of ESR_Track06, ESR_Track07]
BO_ 1285 ESR_Track06: 8 ESR
 SG_ CAN_TX_TRACK_GROUPING_CHANGED : 1|1@0+ (1,0) [0|0] "" Vector__XXX
 SG_ CAN_TX_TRACK_ONCOMING : 0|1@0+ (1,0) [0|0] "" Vector__XXX
 SG_ CAN_TX_TRACK_LAT_RATE : 7|6@0- (0.25,0) [-8|7.75] "" Vector__XXX
 SG_ CAN_TX_TRACK_BRIDGE_OBJECT : 39|1@0+ (1,0) [0|0] "" Vector__XXX
 SG_ CAN_TX_TRACK_WIDTH : 37|4@0+ (0.5,0) [0|7.5] "m" Vector__XXX
 SG_ CAN_TX_TRACK_STATUS : 15|3@0+ (1,0) [0|7] "" Vector__XXX
 SG_ CAN_TX_TRACK_ROLLING_COUNT : 38|1@0+ (1,0) [0|1] "" Vector__XXX
 SG_ CAN_TX_TRACK_RANGE_RATE : 53|14@0- (0.01,0) [-81.92|81.91] "m/s" Vector__XXX
 SG_ CAN_TX_TRACK_RANGE_ACCEL : 33|10@0- (0.05,0) [-25.6|25.55] "m/s/s" Vector__XXX
 SG_ CAN_TX_TRACK_RANGE : 18|11@0+ (0.1,0) [0|204.7] "m" Vector__XXX
 SG_ CAN_TX_TRACK_MED_RANGE_MODE : 55|2@0+ (1,0) [0|3] "" Vector__XXX
 SG_ CAN_TX_TRACK_ANGLE : 12|10@0- (0.1,0) [-51.2|51.1] "deg" Vector__XXX

BO_ 1286 ESR_Track07: 8 ESR
 SG_ CAN_TX_TRACK_GROUPING_CHANGED : 1|1@0+ (1,0) [0|0] "" Vector__XXX
 SG_ CAN_TX_TRACK_ONCOMING : 0|1@0+ (1,0) [0|0] "" Vector__XXX
 SG_ CAN_TX_TRACK_LAT_RATE : 7|6@0- (0.25,0) [-8|7.75] "" Vector__XXX
 SG_ CAN_TX_TRACK_BRIDGE_OBJECT : 39|1@0+ (1,0) [0|0] "" Vector__XXX
 SG_ CAN_TX_TRACK_WIDTH : 37|4@0+ (0.5,0) [0|7.5] "m" Vector__XXX
 SG_ CAN_TX_TRACK_STATUS : 15|3@0+ (1,0) [0|7] "" Vector__XXX
 SG_ CAN_TX_TRACK_ROLLING_COUNT : 38|1@0+ (1,0) [0|1] "" Vector__XXX
 SG_ CAN_TX_TRACK_RANGE_RATE : 53|14@0- (0.01,0) [-81.92|81.91] "m/s" Vector__XXX
 SG_ CAN_TX_TRACK_RANGE_ACCEL : 33|10@0- (0.05,0) [-25.6|25.55] "m/s/s" Vector__XXX
 SG_ CAN_TX_TRACK_RANGE : 18|11@0+ (0.1,0) [0|204.7] "m" Vector__XXX
 SG_ CAN_TX_TRACK_MED_RANGE_MODE : 55|2@0+ (1,0) [0|3] "" Vector__XXX
 SG_ CAN_TX_TRACK_ANGLE : 12|10@0- (0.1,0) [-51.2|51.1] "deg" Vector__XXX

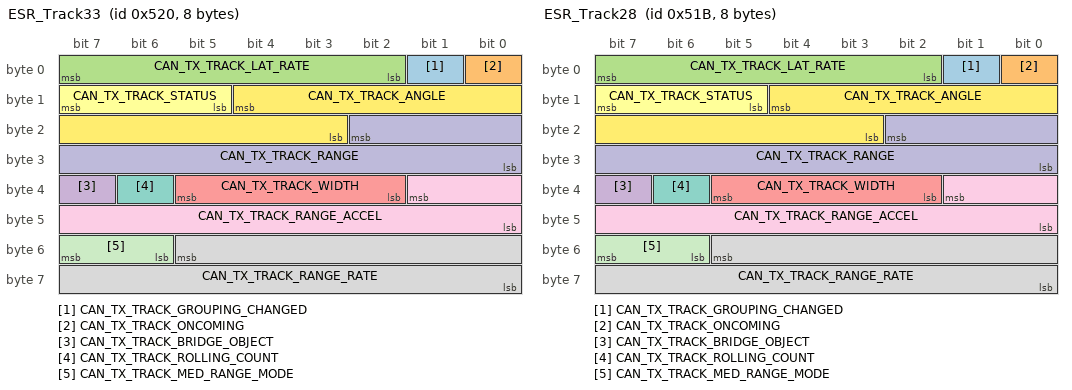
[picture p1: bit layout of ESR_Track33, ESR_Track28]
BO_ 1312 ESR_Track33: 8 ESR
 SG_ CAN_TX_TRACK_GROUPING_CHANGED : 1|1@0+ (1,0) [0|0] "" Vector__XXX
 SG_ CAN_TX_TRACK_ONCOMING : 0|1@0+ (1,0) [0|0] "" Vector__XXX
 SG_ CAN_TX_TRACK_LAT_RATE : 7|6@0- (0.25,0) [-8|7.75] "" Vector__XXX
 SG_ CAN_TX_TRACK_BRIDGE_OBJECT : 39|1@0+ (1,0) [0|0] "" Vector__XXX
 SG_ CAN_TX_TRACK_WIDTH : 37|4@0+ (0.5,0) [0|7.5] "m" Vector__XXX
 SG_ CAN_TX_TRACK_STATUS : 15|3@0+ (1,0) [0|7] "" Vector__XXX
 SG_ CAN_TX_TRACK_ROLLING_COUNT : 38|1@0+ (1,0) [0|1] "" Vector__XXX
 SG_ CAN_TX_TRACK_RANGE_RATE : 53|14@0- (0.01,0) [-81.92|81.91] "m/s" Vector__XXX
 SG_ CAN_TX_TRACK_RANGE_ACCEL : 33|10@0- (0.05,0) [-25.6|25.55] "m/s/s" Vector__XXX
 SG_ CAN_TX_TRACK_RANGE : 18|11@0+ (0.1,0) [0|204.7] "m" Vector__XXX
 SG_ CAN_TX_TRACK_MED_RANGE_MODE : 55|2@0+ (1,0) [0|3] "" Vector__XXX
 SG_ CAN_TX_TRACK_ANGLE : 12|10@0- (0.1,0) [-51.2|51.1] "deg" Vector__XXX

BO_ 1307 ESR_Track28: 8 ESR
 SG_ CAN_TX_TRACK_GROUPING_CHANGED : 1|1@0+ (1,0) [0|0] "" Vector__XXX
 SG_ CAN_TX_TRACK_ONCOMING : 0|1@0+ (1,0) [0|0] "" Vector__XXX
 SG_ CAN_TX_TRACK_LAT_RATE : 7|6@0- (0.25,0) [-8|7.75] "" Vector__XXX
 SG_ CAN_TX_TRACK_BRIDGE_OBJECT : 39|1@0+ (1,0) [0|0] "" Vector__XXX
 SG_ CAN_TX_TRACK_WIDTH : 37|4@0+ (0.5,0) [0|7.5] "m" Vector__XXX
 SG_ CAN_TX_TRACK_STATUS : 15|3@0+ (1,0) [0|7] "" Vector__XXX
 SG_ CAN_TX_TRACK_ROLLING_COUNT : 38|1@0+ (1,0) [0|1] "" Vector__XXX
 SG_ CAN_TX_TRACK_RANGE_RATE : 53|14@0- (0.01,0) [-81.92|81.91] "m/s" Vector__XXX
 SG_ CAN_TX_TRACK_RANGE_ACCEL : 33|10@0- (0.05,0) [-25.6|25.55] "m/s/s" Vector__XXX
 SG_ CAN_TX_TRACK_RANGE : 18|11@0+ (0.1,0) [0|204.7] "m" Vector__XXX
 SG_ CAN_TX_TRACK_MED_RANGE_MODE : 55|2@0+ (1,0) [0|3] "" Vector__XXX
 SG_ CAN_TX_TRACK_ANGLE : 12|10@0- (0.1,0) [-51.2|51.1] "deg" Vector__XXX

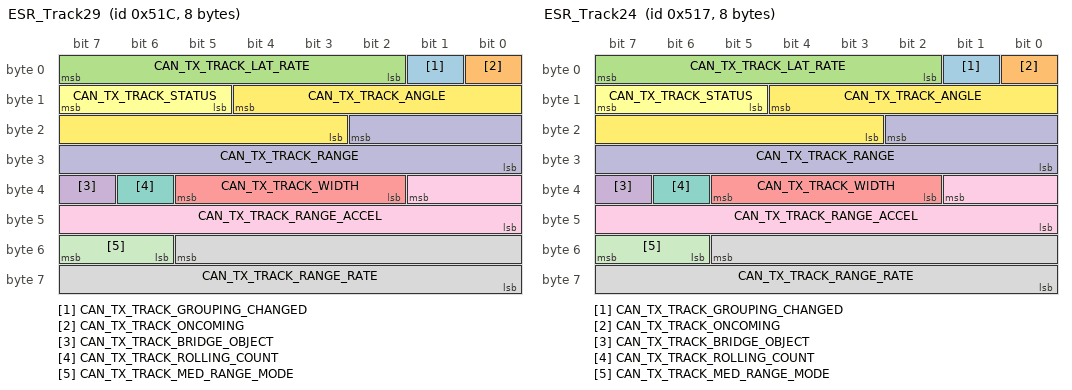
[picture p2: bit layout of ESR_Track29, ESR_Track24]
BO_ 1308 ESR_Track29: 8 ESR
 SG_ CAN_TX_TRACK_GROUPING_CHANGED : 1|1@0+ (1,0) [0|0] "" Vector__XXX
 SG_ CAN_TX_TRACK_ONCOMING : 0|1@0+ (1,0) [0|0] "" Vector__XXX
 SG_ CAN_TX_TRACK_LAT_RATE : 7|6@0- (0.25,0) [-8|7.75] "" Vector__XXX
 SG_ CAN_TX_TRACK_BRIDGE_OBJECT : 39|1@0+ (1,0) [0|0] "" Vector__XXX
 SG_ CAN_TX_TRACK_WIDTH : 37|4@0+ (0.5,0) [0|7.5] "m" Vector__XXX
 SG_ CAN_TX_TRACK_STATUS : 15|3@0+ (1,0) [0|7] "" Vector__XXX
 SG_ CAN_TX_TRACK_ROLLING_COUNT : 38|1@0+ (1,0) [0|1] "" Vector__XXX
 SG_ CAN_TX_TRACK_RANGE_RATE : 53|14@0- (0.01,0) [-81.92|81.91] "m/s" Vector__XXX
 SG_ CAN_TX_TRACK_RANGE_ACCEL : 33|10@0- (0.05,0) [-25.6|25.55] "m/s/s" Vector__XXX
 SG_ CAN_TX_TRACK_RANGE : 18|11@0+ (0.1,0) [0|204.7] "m" Vector__XXX
 SG_ CAN_TX_TRACK_MED_RANGE_MODE : 55|2@0+ (1,0) [0|3] "" Vector__XXX
 SG_ CAN_TX_TRACK_ANGLE : 12|10@0- (0.1,0) [-51.2|51.1] "deg" Vector__XXX

BO_ 1303 ESR_Track24: 8 ESR
 SG_ CAN_TX_TRACK_GROUPING_CHANGED : 1|1@0+ (1,0) [0|0] "" Vector__XXX
 SG_ CAN_TX_TRACK_ONCOMING : 0|1@0+ (1,0) [0|0] "" Vector__XXX
 SG_ CAN_TX_TRACK_LAT_RATE : 7|6@0- (0.25,0) [-8|7.75] "" Vector__XXX
 SG_ CAN_TX_TRACK_BRIDGE_OBJECT : 39|1@0+ (1,0) [0|0] "" Vector__XXX
 SG_ CAN_TX_TRACK_WIDTH : 37|4@0+ (0.5,0) [0|7.5] "m" Vector__XXX
 SG_ CAN_TX_TRACK_STATUS : 15|3@0+ (1,0) [0|7] "" Vector__XXX
 SG_ CAN_TX_TRACK_ROLLING_COUNT : 38|1@0+ (1,0) [0|1] "" Vector__XXX
 SG_ CAN_TX_TRACK_RANGE_RATE : 53|14@0- (0.01,0) [-81.92|81.91] "m/s" Vector__XXX
 SG_ CAN_TX_TRACK_RANGE_ACCEL : 33|10@0- (0.05,0) [-25.6|25.55] "m/s/s" Vector__XXX
 SG_ CAN_TX_TRACK_RANGE : 18|11@0+ (0.1,0) [0|204.7] "m" Vector__XXX
 SG_ CAN_TX_TRACK_MED_RANGE_MODE : 55|2@0+ (1,0) [0|3] "" Vector__XXX
 SG_ CAN_TX_TRACK_ANGLE : 12|10@0- (0.1,0) [-51.2|51.1] "deg" Vector__XXX

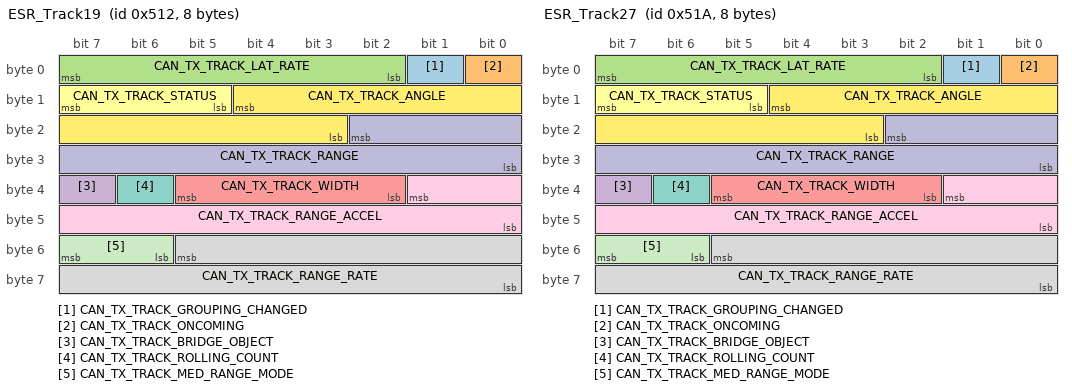
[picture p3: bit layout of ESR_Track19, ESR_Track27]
BO_ 1298 ESR_Track19: 8 ESR
 SG_ CAN_TX_TRACK_GROUPING_CHANGED : 1|1@0+ (1,0) [0|0] "" Vector__XXX
 SG_ CAN_TX_TRACK_ONCOMING : 0|1@0+ (1,0) [0|0] "" Vector__XXX
 SG_ CAN_TX_TRACK_LAT_RATE : 7|6@0- (0.25,0) [-8|7.75] "" Vector__XXX
 SG_ CAN_TX_TRACK_BRIDGE_OBJECT : 39|1@0+ (1,0) [0|0] "" Vector__XXX
 SG_ CAN_TX_TRACK_WIDTH : 37|4@0+ (0.5,0) [0|7.5] "m" Vector__XXX
 SG_ CAN_TX_TRACK_STATUS : 15|3@0+ (1,0) [0|7] "" Vector__XXX
 SG_ CAN_TX_TRACK_ROLLING_COUNT : 38|1@0+ (1,0) [0|1] "" Vector__XXX
 SG_ CAN_TX_TRACK_RANGE_RATE : 53|14@0- (0.01,0) [-81.92|81.91] "m/s" Vector__XXX
 SG_ CAN_TX_TRACK_RANGE_ACCEL : 33|10@0- (0.05,0) [-25.6|25.55] "m/s/s" Vector__XXX
 SG_ CAN_TX_TRACK_RANGE : 18|11@0+ (0.1,0) [0|204.7] "m" Vector__XXX
 SG_ CAN_TX_TRACK_MED_RANGE_MODE : 55|2@0+ (1,0) [0|3] "" Vector__XXX
 SG_ CAN_TX_TRACK_ANGLE : 12|10@0- (0.1,0) [-51.2|51.1] "deg" Vector__XXX

BO_ 1306 ESR_Track27: 8 ESR
 SG_ CAN_TX_TRACK_GROUPING_CHANGED : 1|1@0+ (1,0) [0|0] "" Vector__XXX
 SG_ CAN_TX_TRACK_ONCOMING : 0|1@0+ (1,0) [0|0] "" Vector__XXX
 SG_ CAN_TX_TRACK_LAT_RATE : 7|6@0- (0.25,0) [-8|7.75] "" Vector__XXX
 SG_ CAN_TX_TRACK_BRIDGE_OBJECT : 39|1@0+ (1,0) [0|0] "" Vector__XXX
 SG_ CAN_TX_TRACK_WIDTH : 37|4@0+ (0.5,0) [0|7.5] "m" Vector__XXX
 SG_ CAN_TX_TRACK_STATUS : 15|3@0+ (1,0) [0|7] "" Vector__XXX
 SG_ CAN_TX_TRACK_ROLLING_COUNT : 38|1@0+ (1,0) [0|1] "" Vector__XXX
 SG_ CAN_TX_TRACK_RANGE_RATE : 53|14@0- (0.01,0) [-81.92|81.91] "m/s" Vector__XXX
 SG_ CAN_TX_TRACK_RANGE_ACCEL : 33|10@0- (0.05,0) [-25.6|25.55] "m/s/s" Vector__XXX
 SG_ CAN_TX_TRACK_RANGE : 18|11@0+ (0.1,0) [0|204.7] "m" Vector__XXX
 SG_ CAN_TX_TRACK_MED_RANGE_MODE : 55|2@0+ (1,0) [0|3] "" Vector__XXX
 SG_ CAN_TX_TRACK_ANGLE : 12|10@0- (0.1,0) [-51.2|51.1] "deg" Vector__XXX

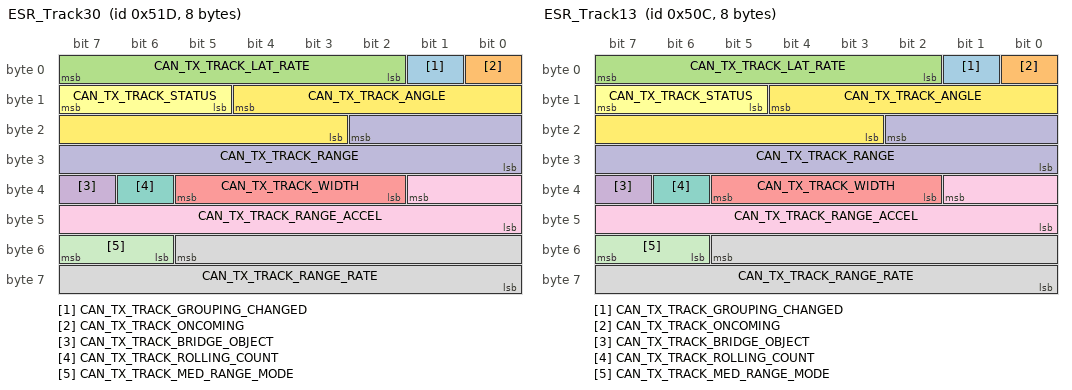
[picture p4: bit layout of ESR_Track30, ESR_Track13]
BO_ 1309 ESR_Track30: 8 ESR
 SG_ CAN_TX_TRACK_GROUPING_CHANGED : 1|1@0+ (1,0) [0|0] "" Vector__XXX
 SG_ CAN_TX_TRACK_ONCOMING : 0|1@0+ (1,0) [0|0] "" Vector__XXX
 SG_ CAN_TX_TRACK_LAT_RATE : 7|6@0- (0.25,0) [-8|7.75] "" Vector__XXX
 SG_ CAN_TX_TRACK_BRIDGE_OBJECT : 39|1@0+ (1,0) [0|0] "" Vector__XXX
 SG_ CAN_TX_TRACK_WIDTH : 37|4@0+ (0.5,0) [0|7.5] "m" Vector__XXX
 SG_ CAN_TX_TRACK_STATUS : 15|3@0+ (1,0) [0|7] "" Vector__XXX
 SG_ CAN_TX_TRACK_ROLLING_COUNT : 38|1@0+ (1,0) [0|1] "" Vector__XXX
 SG_ CAN_TX_TRACK_RANGE_RATE : 53|14@0- (0.01,0) [-81.92|81.91] "m/s" Vector__XXX
 SG_ CAN_TX_TRACK_RANGE_ACCEL : 33|10@0- (0.05,0) [-25.6|25.55] "m/s/s" Vector__XXX
 SG_ CAN_TX_TRACK_RANGE : 18|11@0+ (0.1,0) [0|204.7] "m" Vector__XXX
 SG_ CAN_TX_TRACK_MED_RANGE_MODE : 55|2@0+ (1,0) [0|3] "" Vector__XXX
 SG_ CAN_TX_TRACK_ANGLE : 12|10@0- (0.1,0) [-51.2|51.1] "deg" Vector__XXX

BO_ 1292 ESR_Track13: 8 ESR
 SG_ CAN_TX_TRACK_GROUPING_CHANGED : 1|1@0+ (1,0) [0|0] "" Vector__XXX
 SG_ CAN_TX_TRACK_ONCOMING : 0|1@0+ (1,0) [0|0] "" Vector__XXX
 SG_ CAN_TX_TRACK_LAT_RATE : 7|6@0- (0.25,0) [-8|7.75] "" Vector__XXX
 SG_ CAN_TX_TRACK_BRIDGE_OBJECT : 39|1@0+ (1,0) [0|0] "" Vector__XXX
 SG_ CAN_TX_TRACK_WIDTH : 37|4@0+ (0.5,0) [0|7.5] "m" Vector__XXX
 SG_ CAN_TX_TRACK_STATUS : 15|3@0+ (1,0) [0|7] "" Vector__XXX
 SG_ CAN_TX_TRACK_ROLLING_COUNT : 38|1@0+ (1,0) [0|1] "" Vector__XXX
 SG_ CAN_TX_TRACK_RANGE_RATE : 53|14@0- (0.01,0) [-81.92|81.91] "m/s" Vector__XXX
 SG_ CAN_TX_TRACK_RANGE_ACCEL : 33|10@0- (0.05,0) [-25.6|25.55] "m/s/s" Vector__XXX
 SG_ CAN_TX_TRACK_RANGE : 18|11@0+ (0.1,0) [0|204.7] "m" Vector__XXX
 SG_ CAN_TX_TRACK_MED_RANGE_MODE : 55|2@0+ (1,0) [0|3] "" Vector__XXX
 SG_ CAN_TX_TRACK_ANGLE : 12|10@0- (0.1,0) [-51.2|51.1] "deg" Vector__XXX

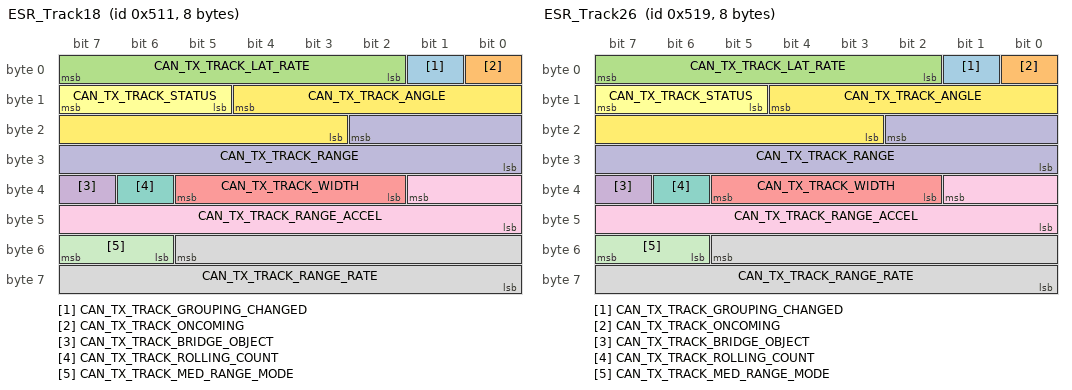
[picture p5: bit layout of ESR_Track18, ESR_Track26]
BO_ 1297 ESR_Track18: 8 ESR
 SG_ CAN_TX_TRACK_GROUPING_CHANGED : 1|1@0+ (1,0) [0|0] "" Vector__XXX
 SG_ CAN_TX_TRACK_ONCOMING : 0|1@0+ (1,0) [0|0] "" Vector__XXX
 SG_ CAN_TX_TRACK_LAT_RATE : 7|6@0- (0.25,0) [-8|7.75] "" Vector__XXX
 SG_ CAN_TX_TRACK_BRIDGE_OBJECT : 39|1@0+ (1,0) [0|0] "" Vector__XXX
 SG_ CAN_TX_TRACK_WIDTH : 37|4@0+ (0.5,0) [0|7.5] "m" Vector__XXX
 SG_ CAN_TX_TRACK_STATUS : 15|3@0+ (1,0) [0|7] "" Vector__XXX
 SG_ CAN_TX_TRACK_ROLLING_COUNT : 38|1@0+ (1,0) [0|1] "" Vector__XXX
 SG_ CAN_TX_TRACK_RANGE_RATE : 53|14@0- (0.01,0) [-81.92|81.91] "m/s" Vector__XXX
 SG_ CAN_TX_TRACK_RANGE_ACCEL : 33|10@0- (0.05,0) [-25.6|25.55] "m/s/s" Vector__XXX
 SG_ CAN_TX_TRACK_RANGE : 18|11@0+ (0.1,0) [0|204.7] "m" Vector__XXX
 SG_ CAN_TX_TRACK_MED_RANGE_MODE : 55|2@0+ (1,0) [0|3] "" Vector__XXX
 SG_ CAN_TX_TRACK_ANGLE : 12|10@0- (0.1,0) [-51.2|51.1] "deg" Vector__XXX

BO_ 1305 ESR_Track26: 8 ESR
 SG_ CAN_TX_TRACK_GROUPING_CHANGED : 1|1@0+ (1,0) [0|0] "" Vector__XXX
 SG_ CAN_TX_TRACK_ONCOMING : 0|1@0+ (1,0) [0|0] "" Vector__XXX
 SG_ CAN_TX_TRACK_LAT_RATE : 7|6@0- (0.25,0) [-8|7.75] "" Vector__XXX
 SG_ CAN_TX_TRACK_BRIDGE_OBJECT : 39|1@0+ (1,0) [0|0] "" Vector__XXX
 SG_ CAN_TX_TRACK_WIDTH : 37|4@0+ (0.5,0) [0|7.5] "m" Vector__XXX
 SG_ CAN_TX_TRACK_STATUS : 15|3@0+ (1,0) [0|7] "" Vector__XXX
 SG_ CAN_TX_TRACK_ROLLING_COUNT : 38|1@0+ (1,0) [0|1] "" Vector__XXX
 SG_ CAN_TX_TRACK_RANGE_RATE : 53|14@0- (0.01,0) [-81.92|81.91] "m/s" Vector__XXX
 SG_ CAN_TX_TRACK_RANGE_ACCEL : 33|10@0- (0.05,0) [-25.6|25.55] "m/s/s" Vector__XXX
 SG_ CAN_TX_TRACK_RANGE : 18|11@0+ (0.1,0) [0|204.7] "m" Vector__XXX
 SG_ CAN_TX_TRACK_MED_RANGE_MODE : 55|2@0+ (1,0) [0|3] "" Vector__XXX
 SG_ CAN_TX_TRACK_ANGLE : 12|10@0- (0.1,0) [-51.2|51.1] "deg" Vector__XXX

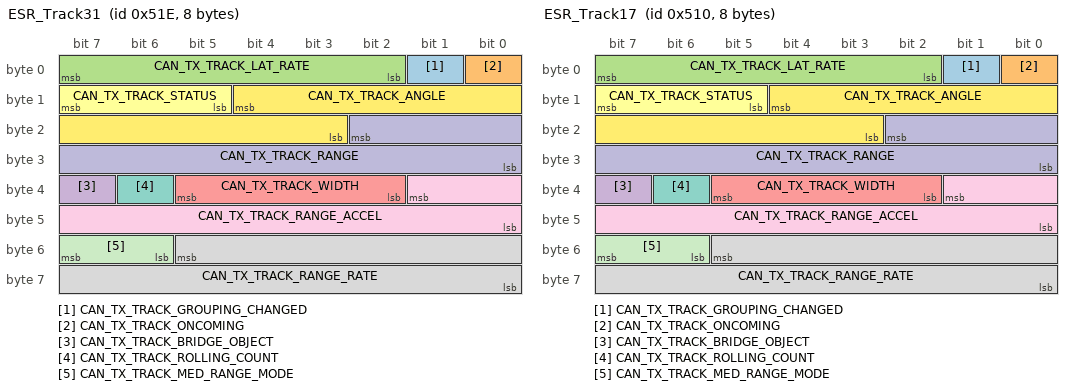
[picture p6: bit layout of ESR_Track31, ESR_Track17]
BO_ 1310 ESR_Track31: 8 ESR
 SG_ CAN_TX_TRACK_GROUPING_CHANGED : 1|1@0+ (1,0) [0|0] "" Vector__XXX
 SG_ CAN_TX_TRACK_ONCOMING : 0|1@0+ (1,0) [0|0] "" Vector__XXX
 SG_ CAN_TX_TRACK_LAT_RATE : 7|6@0- (0.25,0) [-8|7.75] "" Vector__XXX
 SG_ CAN_TX_TRACK_BRIDGE_OBJECT : 39|1@0+ (1,0) [0|0] "" Vector__XXX
 SG_ CAN_TX_TRACK_WIDTH : 37|4@0+ (0.5,0) [0|7.5] "m" Vector__XXX
 SG_ CAN_TX_TRACK_STATUS : 15|3@0+ (1,0) [0|7] "" Vector__XXX
 SG_ CAN_TX_TRACK_ROLLING_COUNT : 38|1@0+ (1,0) [0|1] "" Vector__XXX
 SG_ CAN_TX_TRACK_RANGE_RATE : 53|14@0- (0.01,0) [-81.92|81.91] "m/s" Vector__XXX
 SG_ CAN_TX_TRACK_RANGE_ACCEL : 33|10@0- (0.05,0) [-25.6|25.55] "m/s/s" Vector__XXX
 SG_ CAN_TX_TRACK_RANGE : 18|11@0+ (0.1,0) [0|204.7] "m" Vector__XXX
 SG_ CAN_TX_TRACK_MED_RANGE_MODE : 55|2@0+ (1,0) [0|3] "" Vector__XXX
 SG_ CAN_TX_TRACK_ANGLE : 12|10@0- (0.1,0) [-51.2|51.1] "deg" Vector__XXX

BO_ 1296 ESR_Track17: 8 ESR
 SG_ CAN_TX_TRACK_GROUPING_CHANGED : 1|1@0+ (1,0) [0|0] "" Vector__XXX
 SG_ CAN_TX_TRACK_ONCOMING : 0|1@0+ (1,0) [0|0] "" Vector__XXX
 SG_ CAN_TX_TRACK_LAT_RATE : 7|6@0- (0.25,0) [-8|7.75] "" Vector__XXX
 SG_ CAN_TX_TRACK_BRIDGE_OBJECT : 39|1@0+ (1,0) [0|0] "" Vector__XXX
 SG_ CAN_TX_TRACK_WIDTH : 37|4@0+ (0.5,0) [0|7.5] "m" Vector__XXX
 SG_ CAN_TX_TRACK_STATUS : 15|3@0+ (1,0) [0|7] "" Vector__XXX
 SG_ CAN_TX_TRACK_ROLLING_COUNT : 38|1@0+ (1,0) [0|1] "" Vector__XXX
 SG_ CAN_TX_TRACK_RANGE_RATE : 53|14@0- (0.01,0) [-81.92|81.91] "m/s" Vector__XXX
 SG_ CAN_TX_TRACK_RANGE_ACCEL : 33|10@0- (0.05,0) [-25.6|25.55] "m/s/s" Vector__XXX
 SG_ CAN_TX_TRACK_RANGE : 18|11@0+ (0.1,0) [0|204.7] "m" Vector__XXX
 SG_ CAN_TX_TRACK_MED_RANGE_MODE : 55|2@0+ (1,0) [0|3] "" Vector__XXX
 SG_ CAN_TX_TRACK_ANGLE : 12|10@0- (0.1,0) [-51.2|51.1] "deg" Vector__XXX

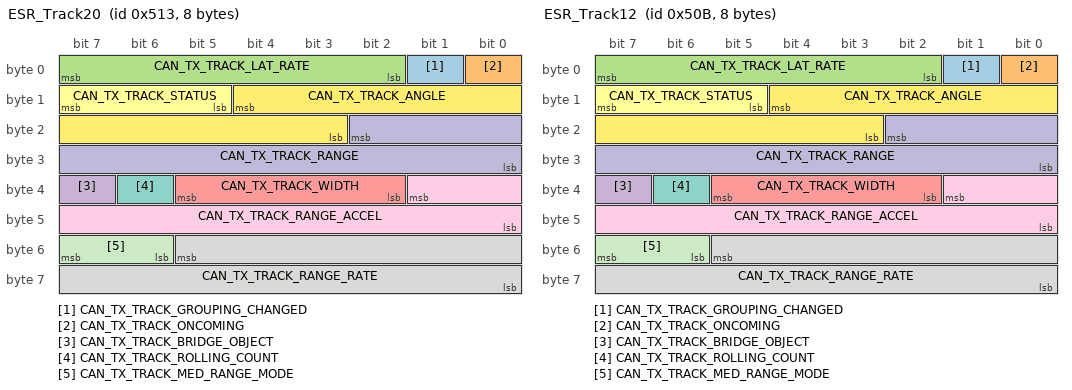
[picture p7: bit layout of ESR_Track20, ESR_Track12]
BO_ 1299 ESR_Track20: 8 ESR
 SG_ CAN_TX_TRACK_GROUPING_CHANGED : 1|1@0+ (1,0) [0|0] "" Vector__XXX
 SG_ CAN_TX_TRACK_ONCOMING : 0|1@0+ (1,0) [0|0] "" Vector__XXX
 SG_ CAN_TX_TRACK_LAT_RATE : 7|6@0- (0.25,0) [-8|7.75] "" Vector__XXX
 SG_ CAN_TX_TRACK_BRIDGE_OBJECT : 39|1@0+ (1,0) [0|0] "" Vector__XXX
 SG_ CAN_TX_TRACK_WIDTH : 37|4@0+ (0.5,0) [0|7.5] "m" Vector__XXX
 SG_ CAN_TX_TRACK_STATUS : 15|3@0+ (1,0) [0|7] "" Vector__XXX
 SG_ CAN_TX_TRACK_ROLLING_COUNT : 38|1@0+ (1,0) [0|1] "" Vector__XXX
 SG_ CAN_TX_TRACK_RANGE_RATE : 53|14@0- (0.01,0) [-81.92|81.91] "m/s" Vector__XXX
 SG_ CAN_TX_TRACK_RANGE_ACCEL : 33|10@0- (0.05,0) [-25.6|25.55] "m/s/s" Vector__XXX
 SG_ CAN_TX_TRACK_RANGE : 18|11@0+ (0.1,0) [0|204.7] "m" Vector__XXX
 SG_ CAN_TX_TRACK_MED_RANGE_MODE : 55|2@0+ (1,0) [0|3] "" Vector__XXX
 SG_ CAN_TX_TRACK_ANGLE : 12|10@0- (0.1,0) [-51.2|51.1] "deg" Vector__XXX

BO_ 1291 ESR_Track12: 8 ESR
 SG_ CAN_TX_TRACK_GROUPING_CHANGED : 1|1@0+ (1,0) [0|0] "" Vector__XXX
 SG_ CAN_TX_TRACK_ONCOMING : 0|1@0+ (1,0) [0|0] "" Vector__XXX
 SG_ CAN_TX_TRACK_LAT_RATE : 7|6@0- (0.25,0) [-8|7.75] "" Vector__XXX
 SG_ CAN_TX_TRACK_BRIDGE_OBJECT : 39|1@0+ (1,0) [0|0] "" Vector__XXX
 SG_ CAN_TX_TRACK_WIDTH : 37|4@0+ (0.5,0) [0|7.5] "m" Vector__XXX
 SG_ CAN_TX_TRACK_STATUS : 15|3@0+ (1,0) [0|7] "" Vector__XXX
 SG_ CAN_TX_TRACK_ROLLING_COUNT : 38|1@0+ (1,0) [0|1] "" Vector__XXX
 SG_ CAN_TX_TRACK_RANGE_RATE : 53|14@0- (0.01,0) [-81.92|81.91] "m/s" Vector__XXX
 SG_ CAN_TX_TRACK_RANGE_ACCEL : 33|10@0- (0.05,0) [-25.6|25.55] "m/s/s" Vector__XXX
 SG_ CAN_TX_TRACK_RANGE : 18|11@0+ (0.1,0) [0|204.7] "m" Vector__XXX
 SG_ CAN_TX_TRACK_MED_RANGE_MODE : 55|2@0+ (1,0) [0|3] "" Vector__XXX
 SG_ CAN_TX_TRACK_ANGLE : 12|10@0- (0.1,0) [-51.2|51.1] "deg" Vector__XXX

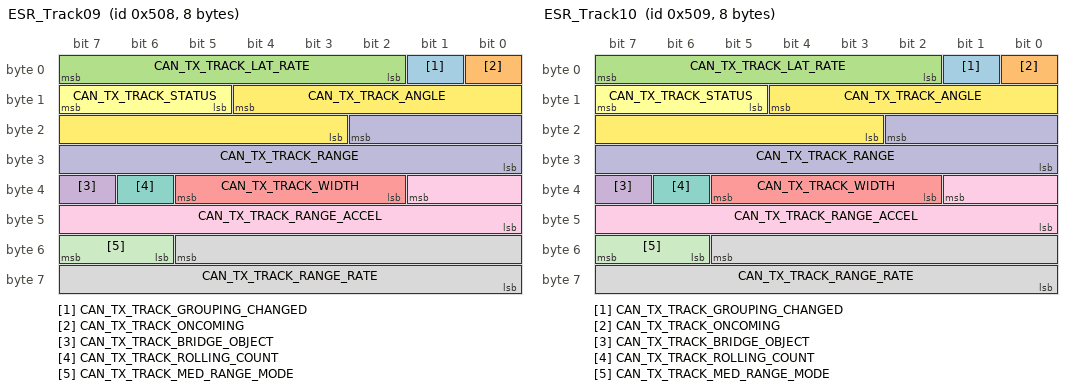
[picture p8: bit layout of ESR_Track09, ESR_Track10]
BO_ 1288 ESR_Track09: 8 ESR
 SG_ CAN_TX_TRACK_GROUPING_CHANGED : 1|1@0+ (1,0) [0|0] "" Vector__XXX
 SG_ CAN_TX_TRACK_ONCOMING : 0|1@0+ (1,0) [0|0] "" Vector__XXX
 SG_ CAN_TX_TRACK_LAT_RATE : 7|6@0- (0.25,0) [-8|7.75] "" Vector__XXX
 SG_ CAN_TX_TRACK_BRIDGE_OBJECT : 39|1@0+ (1,0) [0|0] "" Vector__XXX
 SG_ CAN_TX_TRACK_WIDTH : 37|4@0+ (0.5,0) [0|7.5] "m" Vector__XXX
 SG_ CAN_TX_TRACK_STATUS : 15|3@0+ (1,0) [0|7] "" Vector__XXX
 SG_ CAN_TX_TRACK_ROLLING_COUNT : 38|1@0+ (1,0) [0|1] "" Vector__XXX
 SG_ CAN_TX_TRACK_RANGE_RATE : 53|14@0- (0.01,0) [-81.92|81.91] "m/s" Vector__XXX
 SG_ CAN_TX_TRACK_RANGE_ACCEL : 33|10@0- (0.05,0) [-25.6|25.55] "m/s/s" Vector__XXX
 SG_ CAN_TX_TRACK_RANGE : 18|11@0+ (0.1,0) [0|204.7] "m" Vector__XXX
 SG_ CAN_TX_TRACK_MED_RANGE_MODE : 55|2@0+ (1,0) [0|3] "" Vector__XXX
 SG_ CAN_TX_TRACK_ANGLE : 12|10@0- (0.1,0) [-51.2|51.1] "deg" Vector__XXX

BO_ 1289 ESR_Track10: 8 ESR
 SG_ CAN_TX_TRACK_GROUPING_CHANGED : 1|1@0+ (1,0) [0|0] "" Vector__XXX
 SG_ CAN_TX_TRACK_ONCOMING : 0|1@0+ (1,0) [0|0] "" Vector__XXX
 SG_ CAN_TX_TRACK_LAT_RATE : 7|6@0- (0.25,0) [-8|7.75] "" Vector__XXX
 SG_ CAN_TX_TRACK_BRIDGE_OBJECT : 39|1@0+ (1,0) [0|0] "" Vector__XXX
 SG_ CAN_TX_TRACK_WIDTH : 37|4@0+ (0.5,0) [0|7.5] "m" Vector__XXX
 SG_ CAN_TX_TRACK_STATUS : 15|3@0+ (1,0) [0|7] "" Vector__XXX
 SG_ CAN_TX_TRACK_ROLLING_COUNT : 38|1@0+ (1,0) [0|1] "" Vector__XXX
 SG_ CAN_TX_TRACK_RANGE_RATE : 53|14@0- (0.01,0) [-81.92|81.91] "m/s" Vector__XXX
 SG_ CAN_TX_TRACK_RANGE_ACCEL : 33|10@0- (0.05,0) [-25.6|25.55] "m/s/s" Vector__XXX
 SG_ CAN_TX_TRACK_RANGE : 18|11@0+ (0.1,0) [0|204.7] "m" Vector__XXX
 SG_ CAN_TX_TRACK_MED_RANGE_MODE : 55|2@0+ (1,0) [0|3] "" Vector__XXX
 SG_ CAN_TX_TRACK_ANGLE : 12|10@0- (0.1,0) [-51.2|51.1] "deg" Vector__XXX

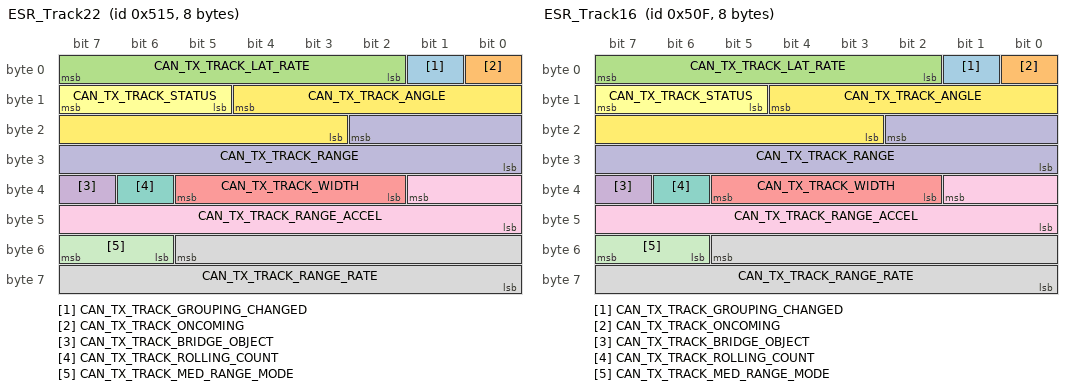
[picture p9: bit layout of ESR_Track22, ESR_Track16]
BO_ 1301 ESR_Track22: 8 ESR
 SG_ CAN_TX_TRACK_GROUPING_CHANGED : 1|1@0+ (1,0) [0|0] "" Vector__XXX
 SG_ CAN_TX_TRACK_ONCOMING : 0|1@0+ (1,0) [0|0] "" Vector__XXX
 SG_ CAN_TX_TRACK_LAT_RATE : 7|6@0- (0.25,0) [-8|7.75] "" Vector__XXX
 SG_ CAN_TX_TRACK_BRIDGE_OBJECT : 39|1@0+ (1,0) [0|0] "" Vector__XXX
 SG_ CAN_TX_TRACK_WIDTH : 37|4@0+ (0.5,0) [0|7.5] "m" Vector__XXX
 SG_ CAN_TX_TRACK_STATUS : 15|3@0+ (1,0) [0|7] "" Vector__XXX
 SG_ CAN_TX_TRACK_ROLLING_COUNT : 38|1@0+ (1,0) [0|1] "" Vector__XXX
 SG_ CAN_TX_TRACK_RANGE_RATE : 53|14@0- (0.01,0) [-81.92|81.91] "m/s" Vector__XXX
 SG_ CAN_TX_TRACK_RANGE_ACCEL : 33|10@0- (0.05,0) [-25.6|25.55] "m/s/s" Vector__XXX
 SG_ CAN_TX_TRACK_RANGE : 18|11@0+ (0.1,0) [0|204.7] "m" Vector__XXX
 SG_ CAN_TX_TRACK_MED_RANGE_MODE : 55|2@0+ (1,0) [0|3] "" Vector__XXX
 SG_ CAN_TX_TRACK_ANGLE : 12|10@0- (0.1,0) [-51.2|51.1] "deg" Vector__XXX

BO_ 1295 ESR_Track16: 8 ESR
 SG_ CAN_TX_TRACK_GROUPING_CHANGED : 1|1@0+ (1,0) [0|0] "" Vector__XXX
 SG_ CAN_TX_TRACK_ONCOMING : 0|1@0+ (1,0) [0|0] "" Vector__XXX
 SG_ CAN_TX_TRACK_LAT_RATE : 7|6@0- (0.25,0) [-8|7.75] "" Vector__XXX
 SG_ CAN_TX_TRACK_BRIDGE_OBJECT : 39|1@0+ (1,0) [0|0] "" Vector__XXX
 SG_ CAN_TX_TRACK_WIDTH : 37|4@0+ (0.5,0) [0|7.5] "m" Vector__XXX
 SG_ CAN_TX_TRACK_STATUS : 15|3@0+ (1,0) [0|7] "" Vector__XXX
 SG_ CAN_TX_TRACK_ROLLING_COUNT : 38|1@0+ (1,0) [0|1] "" Vector__XXX
 SG_ CAN_TX_TRACK_RANGE_RATE : 53|14@0- (0.01,0) [-81.92|81.91] "m/s" Vector__XXX
 SG_ CAN_TX_TRACK_RANGE_ACCEL : 33|10@0- (0.05,0) [-25.6|25.55] "m/s/s" Vector__XXX
 SG_ CAN_TX_TRACK_RANGE : 18|11@0+ (0.1,0) [0|204.7] "m" Vector__XXX
 SG_ CAN_TX_TRACK_MED_RANGE_MODE : 55|2@0+ (1,0) [0|3] "" Vector__XXX
 SG_ CAN_TX_TRACK_ANGLE : 12|10@0- (0.1,0) [-51.2|51.1] "deg" Vector__XXX

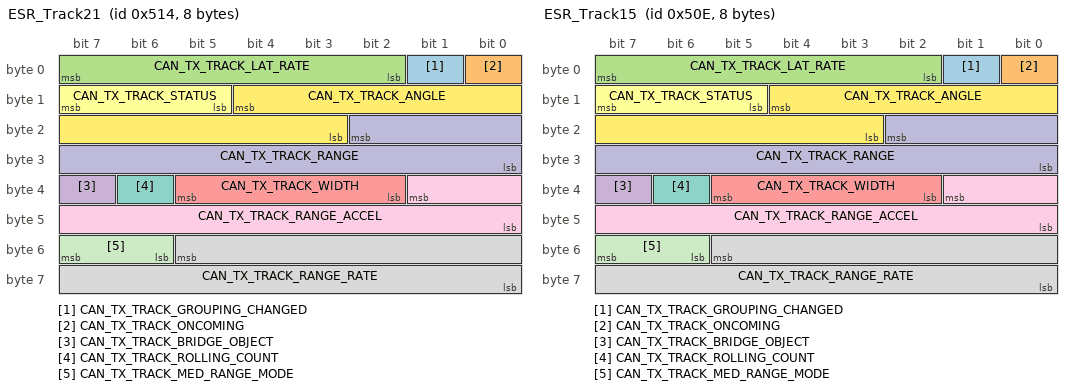
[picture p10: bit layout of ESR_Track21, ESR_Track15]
BO_ 1300 ESR_Track21: 8 ESR
 SG_ CAN_TX_TRACK_GROUPING_CHANGED : 1|1@0+ (1,0) [0|0] "" Vector__XXX
 SG_ CAN_TX_TRACK_ONCOMING : 0|1@0+ (1,0) [0|0] "" Vector__XXX
 SG_ CAN_TX_TRACK_LAT_RATE : 7|6@0- (0.25,0) [-8|7.75] "" Vector__XXX
 SG_ CAN_TX_TRACK_BRIDGE_OBJECT : 39|1@0+ (1,0) [0|0] "" Vector__XXX
 SG_ CAN_TX_TRACK_WIDTH : 37|4@0+ (0.5,0) [0|7.5] "m" Vector__XXX
 SG_ CAN_TX_TRACK_STATUS : 15|3@0+ (1,0) [0|7] "" Vector__XXX
 SG_ CAN_TX_TRACK_ROLLING_COUNT : 38|1@0+ (1,0) [0|1] "" Vector__XXX
 SG_ CAN_TX_TRACK_RANGE_RATE : 53|14@0- (0.01,0) [-81.92|81.91] "m/s" Vector__XXX
 SG_ CAN_TX_TRACK_RANGE_ACCEL : 33|10@0- (0.05,0) [-25.6|25.55] "m/s/s" Vector__XXX
 SG_ CAN_TX_TRACK_RANGE : 18|11@0+ (0.1,0) [0|204.7] "m" Vector__XXX
 SG_ CAN_TX_TRACK_MED_RANGE_MODE : 55|2@0+ (1,0) [0|3] "" Vector__XXX
 SG_ CAN_TX_TRACK_ANGLE : 12|10@0- (0.1,0) [-51.2|51.1] "deg" Vector__XXX

BO_ 1294 ESR_Track15: 8 ESR
 SG_ CAN_TX_TRACK_GROUPING_CHANGED : 1|1@0+ (1,0) [0|0] "" Vector__XXX
 SG_ CAN_TX_TRACK_ONCOMING : 0|1@0+ (1,0) [0|0] "" Vector__XXX
 SG_ CAN_TX_TRACK_LAT_RATE : 7|6@0- (0.25,0) [-8|7.75] "" Vector__XXX
 SG_ CAN_TX_TRACK_BRIDGE_OBJECT : 39|1@0+ (1,0) [0|0] "" Vector__XXX
 SG_ CAN_TX_TRACK_WIDTH : 37|4@0+ (0.5,0) [0|7.5] "m" Vector__XXX
 SG_ CAN_TX_TRACK_STATUS : 15|3@0+ (1,0) [0|7] "" Vector__XXX
 SG_ CAN_TX_TRACK_ROLLING_COUNT : 38|1@0+ (1,0) [0|1] "" Vector__XXX
 SG_ CAN_TX_TRACK_RANGE_RATE : 53|14@0- (0.01,0) [-81.92|81.91] "m/s" Vector__XXX
 SG_ CAN_TX_TRACK_RANGE_ACCEL : 33|10@0- (0.05,0) [-25.6|25.55] "m/s/s" Vector__XXX
 SG_ CAN_TX_TRACK_RANGE : 18|11@0+ (0.1,0) [0|204.7] "m" Vector__XXX
 SG_ CAN_TX_TRACK_MED_RANGE_MODE : 55|2@0+ (1,0) [0|3] "" Vector__XXX
 SG_ CAN_TX_TRACK_ANGLE : 12|10@0- (0.1,0) [-51.2|51.1] "deg" Vector__XXX

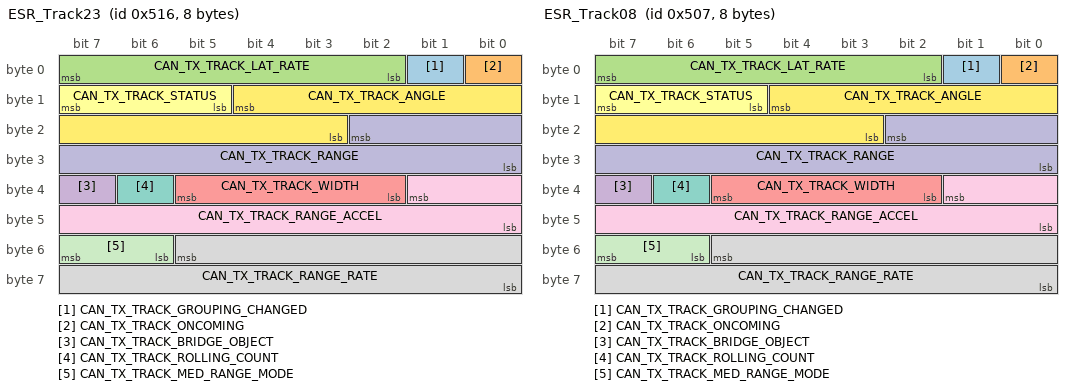
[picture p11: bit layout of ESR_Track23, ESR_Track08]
BO_ 1302 ESR_Track23: 8 ESR
 SG_ CAN_TX_TRACK_GROUPING_CHANGED : 1|1@0+ (1,0) [0|0] "" Vector__XXX
 SG_ CAN_TX_TRACK_ONCOMING : 0|1@0+ (1,0) [0|0] "" Vector__XXX
 SG_ CAN_TX_TRACK_LAT_RATE : 7|6@0- (0.25,0) [-8|7.75] "" Vector__XXX
 SG_ CAN_TX_TRACK_BRIDGE_OBJECT : 39|1@0+ (1,0) [0|0] "" Vector__XXX
 SG_ CAN_TX_TRACK_WIDTH : 37|4@0+ (0.5,0) [0|7.5] "m" Vector__XXX
 SG_ CAN_TX_TRACK_STATUS : 15|3@0+ (1,0) [0|7] "" Vector__XXX
 SG_ CAN_TX_TRACK_ROLLING_COUNT : 38|1@0+ (1,0) [0|1] "" Vector__XXX
 SG_ CAN_TX_TRACK_RANGE_RATE : 53|14@0- (0.01,0) [-81.92|81.91] "m/s" Vector__XXX
 SG_ CAN_TX_TRACK_RANGE_ACCEL : 33|10@0- (0.05,0) [-25.6|25.55] "m/s/s" Vector__XXX
 SG_ CAN_TX_TRACK_RANGE : 18|11@0+ (0.1,0) [0|204.7] "m" Vector__XXX
 SG_ CAN_TX_TRACK_MED_RANGE_MODE : 55|2@0+ (1,0) [0|3] "" Vector__XXX
 SG_ CAN_TX_TRACK_ANGLE : 12|10@0- (0.1,0) [-51.2|51.1] "deg" Vector__XXX

BO_ 1287 ESR_Track08: 8 ESR
 SG_ CAN_TX_TRACK_GROUPING_CHANGED : 1|1@0+ (1,0) [0|0] "" Vector__XXX
 SG_ CAN_TX_TRACK_ONCOMING : 0|1@0+ (1,0) [0|0] "" Vector__XXX
 SG_ CAN_TX_TRACK_LAT_RATE : 7|6@0- (0.25,0) [-8|7.75] "" Vector__XXX
 SG_ CAN_TX_TRACK_BRIDGE_OBJECT : 39|1@0+ (1,0) [0|0] "" Vector__XXX
 SG_ CAN_TX_TRACK_WIDTH : 37|4@0+ (0.5,0) [0|7.5] "m" Vector__XXX
 SG_ CAN_TX_TRACK_STATUS : 15|3@0+ (1,0) [0|7] "" Vector__XXX
 SG_ CAN_TX_TRACK_ROLLING_COUNT : 38|1@0+ (1,0) [0|1] "" Vector__XXX
 SG_ CAN_TX_TRACK_RANGE_RATE : 53|14@0- (0.01,0) [-81.92|81.91] "m/s" Vector__XXX
 SG_ CAN_TX_TRACK_RANGE_ACCEL : 33|10@0- (0.05,0) [-25.6|25.55] "m/s/s" Vector__XXX
 SG_ CAN_TX_TRACK_RANGE : 18|11@0+ (0.1,0) [0|204.7] "m" Vector__XXX
 SG_ CAN_TX_TRACK_MED_RANGE_MODE : 55|2@0+ (1,0) [0|3] "" Vector__XXX
 SG_ CAN_TX_TRACK_ANGLE : 12|10@0- (0.1,0) [-51.2|51.1] "deg" Vector__XXX

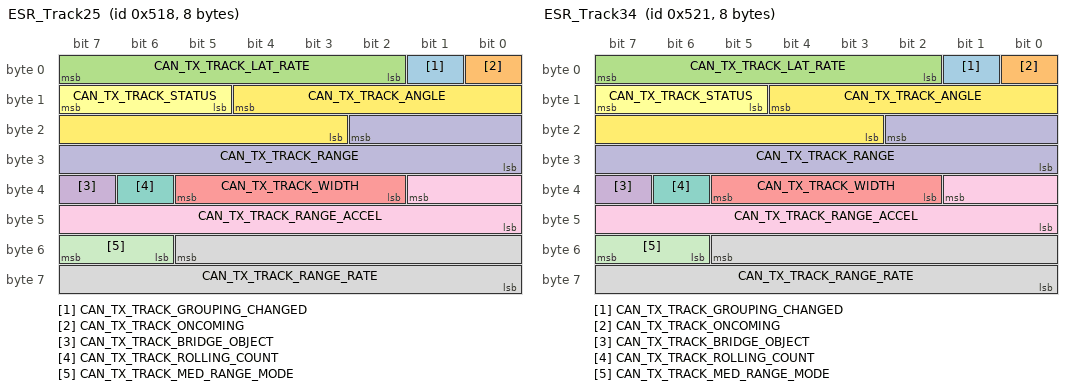
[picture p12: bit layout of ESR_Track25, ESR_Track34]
BO_ 1304 ESR_Track25: 8 ESR
 SG_ CAN_TX_TRACK_GROUPING_CHANGED : 1|1@0+ (1,0) [0|0] "" Vector__XXX
 SG_ CAN_TX_TRACK_ONCOMING : 0|1@0+ (1,0) [0|0] "" Vector__XXX
 SG_ CAN_TX_TRACK_LAT_RATE : 7|6@0- (0.25,0) [-8|7.75] "" Vector__XXX
 SG_ CAN_TX_TRACK_BRIDGE_OBJECT : 39|1@0+ (1,0) [0|0] "" Vector__XXX
 SG_ CAN_TX_TRACK_WIDTH : 37|4@0+ (0.5,0) [0|7.5] "m" Vector__XXX
 SG_ CAN_TX_TRACK_STATUS : 15|3@0+ (1,0) [0|7] "" Vector__XXX
 SG_ CAN_TX_TRACK_ROLLING_COUNT : 38|1@0+ (1,0) [0|1] "" Vector__XXX
 SG_ CAN_TX_TRACK_RANGE_RATE : 53|14@0- (0.01,0) [-81.92|81.91] "m/s" Vector__XXX
 SG_ CAN_TX_TRACK_RANGE_ACCEL : 33|10@0- (0.05,0) [-25.6|25.55] "m/s/s" Vector__XXX
 SG_ CAN_TX_TRACK_RANGE : 18|11@0+ (0.1,0) [0|204.7] "m" Vector__XXX
 SG_ CAN_TX_TRACK_MED_RANGE_MODE : 55|2@0+ (1,0) [0|3] "" Vector__XXX
 SG_ CAN_TX_TRACK_ANGLE : 12|10@0- (0.1,0) [-51.2|51.1] "deg" Vector__XXX

BO_ 1313 ESR_Track34: 8 ESR
 SG_ CAN_TX_TRACK_GROUPING_CHANGED : 1|1@0+ (1,0) [0|0] "" Vector__XXX
 SG_ CAN_TX_TRACK_ONCOMING : 0|1@0+ (1,0) [0|0] "" Vector__XXX
 SG_ CAN_TX_TRACK_LAT_RATE : 7|6@0- (0.25,0) [-8|7.75] "" Vector__XXX
 SG_ CAN_TX_TRACK_BRIDGE_OBJECT : 39|1@0+ (1,0) [0|0] "" Vector__XXX
 SG_ CAN_TX_TRACK_WIDTH : 37|4@0+ (0.5,0) [0|7.5] "m" Vector__XXX
 SG_ CAN_TX_TRACK_STATUS : 15|3@0+ (1,0) [0|7] "" Vector__XXX
 SG_ CAN_TX_TRACK_ROLLING_COUNT : 38|1@0+ (1,0) [0|1] "" Vector__XXX
 SG_ CAN_TX_TRACK_RANGE_RATE : 53|14@0- (0.01,0) [-81.92|81.91] "m/s" Vector__XXX
 SG_ CAN_TX_TRACK_RANGE_ACCEL : 33|10@0- (0.05,0) [-25.6|25.55] "m/s/s" Vector__XXX
 SG_ CAN_TX_TRACK_RANGE : 18|11@0+ (0.1,0) [0|204.7] "m" Vector__XXX
 SG_ CAN_TX_TRACK_MED_RANGE_MODE : 55|2@0+ (1,0) [0|3] "" Vector__XXX
 SG_ CAN_TX_TRACK_ANGLE : 12|10@0- (0.1,0) [-51.2|51.1] "deg" Vector__XXX

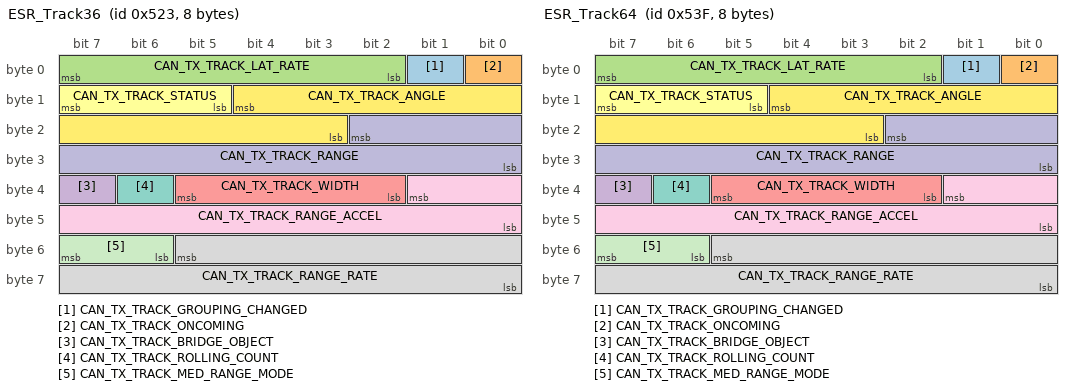
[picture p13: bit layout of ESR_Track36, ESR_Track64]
BO_ 1315 ESR_Track36: 8 ESR
 SG_ CAN_TX_TRACK_GROUPING_CHANGED : 1|1@0+ (1,0) [0|0] "" Vector__XXX
 SG_ CAN_TX_TRACK_ONCOMING : 0|1@0+ (1,0) [0|0] "" Vector__XXX
 SG_ CAN_TX_TRACK_LAT_RATE : 7|6@0- (0.25,0) [-8|7.75] "" Vector__XXX
 SG_ CAN_TX_TRACK_BRIDGE_OBJECT : 39|1@0+ (1,0) [0|0] "" Vector__XXX
 SG_ CAN_TX_TRACK_WIDTH : 37|4@0+ (0.5,0) [0|7.5] "m" Vector__XXX
 SG_ CAN_TX_TRACK_STATUS : 15|3@0+ (1,0) [0|7] "" Vector__XXX
 SG_ CAN_TX_TRACK_ROLLING_COUNT : 38|1@0+ (1,0) [0|1] "" Vector__XXX
 SG_ CAN_TX_TRACK_RANGE_RATE : 53|14@0- (0.01,0) [-81.92|81.91] "m/s" Vector__XXX
 SG_ CAN_TX_TRACK_RANGE_ACCEL : 33|10@0- (0.05,0) [-25.6|25.55] "m/s/s" Vector__XXX
 SG_ CAN_TX_TRACK_RANGE : 18|11@0+ (0.1,0) [0|204.7] "m" Vector__XXX
 SG_ CAN_TX_TRACK_MED_RANGE_MODE : 55|2@0+ (1,0) [0|3] "" Vector__XXX
 SG_ CAN_TX_TRACK_ANGLE : 12|10@0- (0.1,0) [-51.2|51.1] "deg" Vector__XXX

BO_ 1343 ESR_Track64: 8 ESR
 SG_ CAN_TX_TRACK_GROUPING_CHANGED : 1|1@0+ (1,0) [0|0] "" Vector__XXX
 SG_ CAN_TX_TRACK_ONCOMING : 0|1@0+ (1,0) [0|0] "" Vector__XXX
 SG_ CAN_TX_TRACK_LAT_RATE : 7|6@0- (0.25,0) [-8|7.75] "" Vector__XXX
 SG_ CAN_TX_TRACK_BRIDGE_OBJECT : 39|1@0+ (1,0) [0|0] "" Vector__XXX
 SG_ CAN_TX_TRACK_WIDTH : 37|4@0+ (0.5,0) [0|7.5] "m" Vector__XXX
 SG_ CAN_TX_TRACK_STATUS : 15|3@0+ (1,0) [0|7] "" Vector__XXX
 SG_ CAN_TX_TRACK_ROLLING_COUNT : 38|1@0+ (1,0) [0|1] "" Vector__XXX
 SG_ CAN_TX_TRACK_RANGE_RATE : 53|14@0- (0.01,0) [-81.92|81.91] "m/s" Vector__XXX
 SG_ CAN_TX_TRACK_RANGE_ACCEL : 33|10@0- (0.05,0) [-25.6|25.55] "m/s/s" Vector__XXX
 SG_ CAN_TX_TRACK_RANGE : 18|11@0+ (0.1,0) [0|204.7] "m" Vector__XXX
 SG_ CAN_TX_TRACK_MED_RANGE_MODE : 55|2@0+ (1,0) [0|3] "" Vector__XXX
 SG_ CAN_TX_TRACK_ANGLE : 12|10@0- (0.1,0) [-51.2|51.1] "deg" Vector__XXX

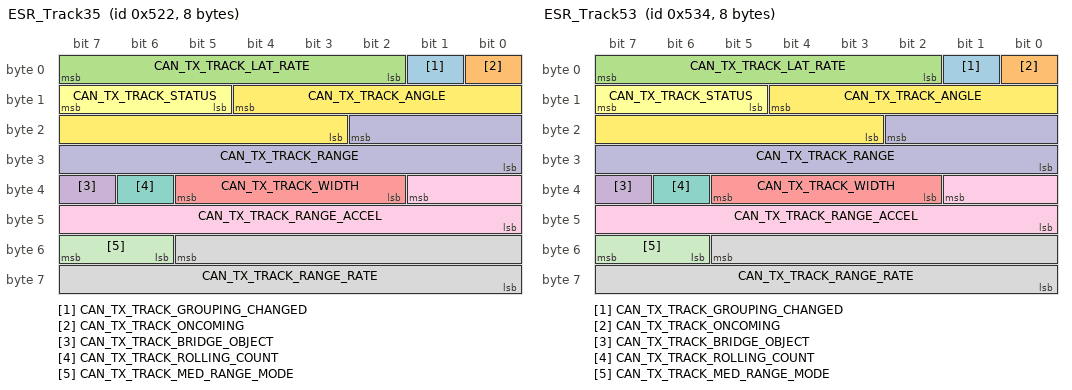
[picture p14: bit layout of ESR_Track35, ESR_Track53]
BO_ 1314 ESR_Track35: 8 ESR
 SG_ CAN_TX_TRACK_GROUPING_CHANGED : 1|1@0+ (1,0) [0|0] "" Vector__XXX
 SG_ CAN_TX_TRACK_ONCOMING : 0|1@0+ (1,0) [0|0] "" Vector__XXX
 SG_ CAN_TX_TRACK_LAT_RATE : 7|6@0- (0.25,0) [-8|7.75] "" Vector__XXX
 SG_ CAN_TX_TRACK_BRIDGE_OBJECT : 39|1@0+ (1,0) [0|0] "" Vector__XXX
 SG_ CAN_TX_TRACK_WIDTH : 37|4@0+ (0.5,0) [0|7.5] "m" Vector__XXX
 SG_ CAN_TX_TRACK_STATUS : 15|3@0+ (1,0) [0|7] "" Vector__XXX
 SG_ CAN_TX_TRACK_ROLLING_COUNT : 38|1@0+ (1,0) [0|1] "" Vector__XXX
 SG_ CAN_TX_TRACK_RANGE_RATE : 53|14@0- (0.01,0) [-81.92|81.91] "m/s" Vector__XXX
 SG_ CAN_TX_TRACK_RANGE_ACCEL : 33|10@0- (0.05,0) [-25.6|25.55] "m/s/s" Vector__XXX
 SG_ CAN_TX_TRACK_RANGE : 18|11@0+ (0.1,0) [0|204.7] "m" Vector__XXX
 SG_ CAN_TX_TRACK_MED_RANGE_MODE : 55|2@0+ (1,0) [0|3] "" Vector__XXX
 SG_ CAN_TX_TRACK_ANGLE : 12|10@0- (0.1,0) [-51.2|51.1] "deg" Vector__XXX

BO_ 1332 ESR_Track53: 8 ESR
 SG_ CAN_TX_TRACK_GROUPING_CHANGED : 1|1@0+ (1,0) [0|0] "" Vector__XXX
 SG_ CAN_TX_TRACK_ONCOMING : 0|1@0+ (1,0) [0|0] "" Vector__XXX
 SG_ CAN_TX_TRACK_LAT_RATE : 7|6@0- (0.25,0) [-8|7.75] "" Vector__XXX
 SG_ CAN_TX_TRACK_BRIDGE_OBJECT : 39|1@0+ (1,0) [0|0] "" Vector__XXX
 SG_ CAN_TX_TRACK_WIDTH : 37|4@0+ (0.5,0) [0|7.5] "m" Vector__XXX
 SG_ CAN_TX_TRACK_STATUS : 15|3@0+ (1,0) [0|7] "" Vector__XXX
 SG_ CAN_TX_TRACK_ROLLING_COUNT : 38|1@0+ (1,0) [0|1] "" Vector__XXX
 SG_ CAN_TX_TRACK_RANGE_RATE : 53|14@0- (0.01,0) [-81.92|81.91] "m/s" Vector__XXX
 SG_ CAN_TX_TRACK_RANGE_ACCEL : 33|10@0- (0.05,0) [-25.6|25.55] "m/s/s" Vector__XXX
 SG_ CAN_TX_TRACK_RANGE : 18|11@0+ (0.1,0) [0|204.7] "m" Vector__XXX
 SG_ CAN_TX_TRACK_MED_RANGE_MODE : 55|2@0+ (1,0) [0|3] "" Vector__XXX
 SG_ CAN_TX_TRACK_ANGLE : 12|10@0- (0.1,0) [-51.2|51.1] "deg" Vector__XXX

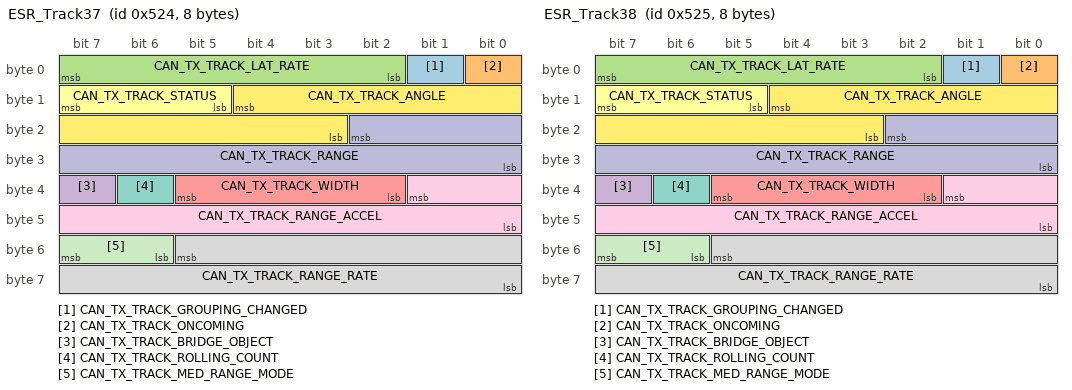
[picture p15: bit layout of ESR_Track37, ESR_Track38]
BO_ 1316 ESR_Track37: 8 ESR
 SG_ CAN_TX_TRACK_GROUPING_CHANGED : 1|1@0+ (1,0) [0|0] "" Vector__XXX
 SG_ CAN_TX_TRACK_ONCOMING : 0|1@0+ (1,0) [0|0] "" Vector__XXX
 SG_ CAN_TX_TRACK_LAT_RATE : 7|6@0- (0.25,0) [-8|7.75] "" Vector__XXX
 SG_ CAN_TX_TRACK_BRIDGE_OBJECT : 39|1@0+ (1,0) [0|0] "" Vector__XXX
 SG_ CAN_TX_TRACK_WIDTH : 37|4@0+ (0.5,0) [0|7.5] "m" Vector__XXX
 SG_ CAN_TX_TRACK_STATUS : 15|3@0+ (1,0) [0|7] "" Vector__XXX
 SG_ CAN_TX_TRACK_ROLLING_COUNT : 38|1@0+ (1,0) [0|1] "" Vector__XXX
 SG_ CAN_TX_TRACK_RANGE_RATE : 53|14@0- (0.01,0) [-81.92|81.91] "m/s" Vector__XXX
 SG_ CAN_TX_TRACK_RANGE_ACCEL : 33|10@0- (0.05,0) [-25.6|25.55] "m/s/s" Vector__XXX
 SG_ CAN_TX_TRACK_RANGE : 18|11@0+ (0.1,0) [0|204.7] "m" Vector__XXX
 SG_ CAN_TX_TRACK_MED_RANGE_MODE : 55|2@0+ (1,0) [0|3] "" Vector__XXX
 SG_ CAN_TX_TRACK_ANGLE : 12|10@0- (0.1,0) [-51.2|51.1] "deg" Vector__XXX

BO_ 1317 ESR_Track38: 8 ESR
 SG_ CAN_TX_TRACK_GROUPING_CHANGED : 1|1@0+ (1,0) [0|0] "" Vector__XXX
 SG_ CAN_TX_TRACK_ONCOMING : 0|1@0+ (1,0) [0|0] "" Vector__XXX
 SG_ CAN_TX_TRACK_LAT_RATE : 7|6@0- (0.25,0) [-8|7.75] "" Vector__XXX
 SG_ CAN_TX_TRACK_BRIDGE_OBJECT : 39|1@0+ (1,0) [0|0] "" Vector__XXX
 SG_ CAN_TX_TRACK_WIDTH : 37|4@0+ (0.5,0) [0|7.5] "m" Vector__XXX
 SG_ CAN_TX_TRACK_STATUS : 15|3@0+ (1,0) [0|7] "" Vector__XXX
 SG_ CAN_TX_TRACK_ROLLING_COUNT : 38|1@0+ (1,0) [0|1] "" Vector__XXX
 SG_ CAN_TX_TRACK_RANGE_RATE : 53|14@0- (0.01,0) [-81.92|81.91] "m/s" Vector__XXX
 SG_ CAN_TX_TRACK_RANGE_ACCEL : 33|10@0- (0.05,0) [-25.6|25.55] "m/s/s" Vector__XXX
 SG_ CAN_TX_TRACK_RANGE : 18|11@0+ (0.1,0) [0|204.7] "m" Vector__XXX
 SG_ CAN_TX_TRACK_MED_RANGE_MODE : 55|2@0+ (1,0) [0|3] "" Vector__XXX
 SG_ CAN_TX_TRACK_ANGLE : 12|10@0- (0.1,0) [-51.2|51.1] "deg" Vector__XXX

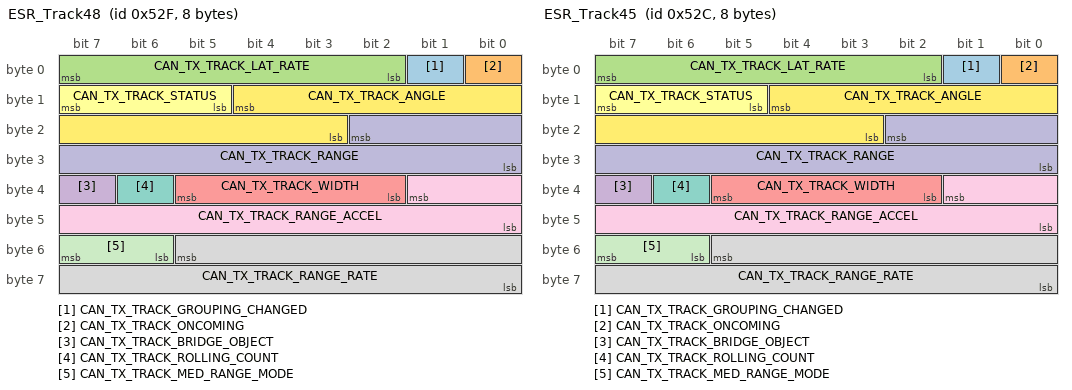
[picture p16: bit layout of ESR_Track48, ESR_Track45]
BO_ 1327 ESR_Track48: 8 ESR
 SG_ CAN_TX_TRACK_GROUPING_CHANGED : 1|1@0+ (1,0) [0|0] "" Vector__XXX
 SG_ CAN_TX_TRACK_ONCOMING : 0|1@0+ (1,0) [0|0] "" Vector__XXX
 SG_ CAN_TX_TRACK_LAT_RATE : 7|6@0- (0.25,0) [-8|7.75] "" Vector__XXX
 SG_ CAN_TX_TRACK_BRIDGE_OBJECT : 39|1@0+ (1,0) [0|0] "" Vector__XXX
 SG_ CAN_TX_TRACK_WIDTH : 37|4@0+ (0.5,0) [0|7.5] "m" Vector__XXX
 SG_ CAN_TX_TRACK_STATUS : 15|3@0+ (1,0) [0|7] "" Vector__XXX
 SG_ CAN_TX_TRACK_ROLLING_COUNT : 38|1@0+ (1,0) [0|1] "" Vector__XXX
 SG_ CAN_TX_TRACK_RANGE_RATE : 53|14@0- (0.01,0) [-81.92|81.91] "m/s" Vector__XXX
 SG_ CAN_TX_TRACK_RANGE_ACCEL : 33|10@0- (0.05,0) [-25.6|25.55] "m/s/s" Vector__XXX
 SG_ CAN_TX_TRACK_RANGE : 18|11@0+ (0.1,0) [0|204.7] "m" Vector__XXX
 SG_ CAN_TX_TRACK_MED_RANGE_MODE : 55|2@0+ (1,0) [0|3] "" Vector__XXX
 SG_ CAN_TX_TRACK_ANGLE : 12|10@0- (0.1,0) [-51.2|51.1] "deg" Vector__XXX

BO_ 1324 ESR_Track45: 8 ESR
 SG_ CAN_TX_TRACK_GROUPING_CHANGED : 1|1@0+ (1,0) [0|0] "" Vector__XXX
 SG_ CAN_TX_TRACK_ONCOMING : 0|1@0+ (1,0) [0|0] "" Vector__XXX
 SG_ CAN_TX_TRACK_LAT_RATE : 7|6@0- (0.25,0) [-8|7.75] "" Vector__XXX
 SG_ CAN_TX_TRACK_BRIDGE_OBJECT : 39|1@0+ (1,0) [0|0] "" Vector__XXX
 SG_ CAN_TX_TRACK_WIDTH : 37|4@0+ (0.5,0) [0|7.5] "m" Vector__XXX
 SG_ CAN_TX_TRACK_STATUS : 15|3@0+ (1,0) [0|7] "" Vector__XXX
 SG_ CAN_TX_TRACK_ROLLING_COUNT : 38|1@0+ (1,0) [0|1] "" Vector__XXX
 SG_ CAN_TX_TRACK_RANGE_RATE : 53|14@0- (0.01,0) [-81.92|81.91] "m/s" Vector__XXX
 SG_ CAN_TX_TRACK_RANGE_ACCEL : 33|10@0- (0.05,0) [-25.6|25.55] "m/s/s" Vector__XXX
 SG_ CAN_TX_TRACK_RANGE : 18|11@0+ (0.1,0) [0|204.7] "m" Vector__XXX
 SG_ CAN_TX_TRACK_MED_RANGE_MODE : 55|2@0+ (1,0) [0|3] "" Vector__XXX
 SG_ CAN_TX_TRACK_ANGLE : 12|10@0- (0.1,0) [-51.2|51.1] "deg" Vector__XXX

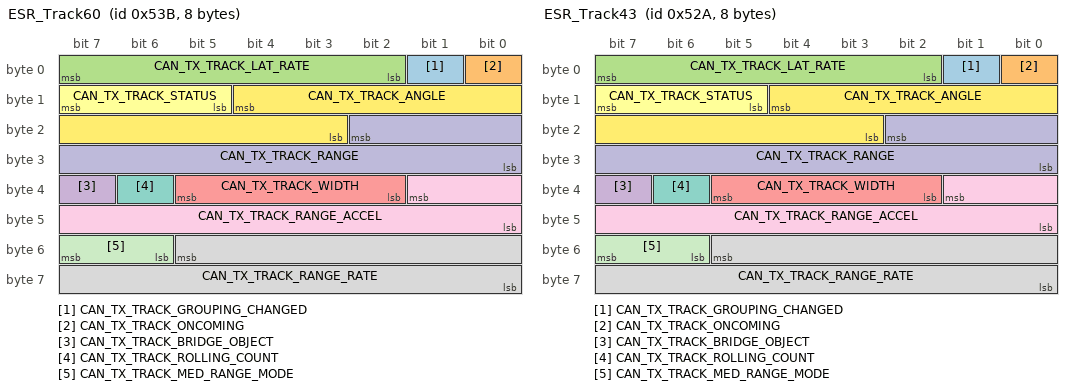
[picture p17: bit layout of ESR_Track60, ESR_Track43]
BO_ 1339 ESR_Track60: 8 ESR
 SG_ CAN_TX_TRACK_GROUPING_CHANGED : 1|1@0+ (1,0) [0|0] "" Vector__XXX
 SG_ CAN_TX_TRACK_ONCOMING : 0|1@0+ (1,0) [0|0] "" Vector__XXX
 SG_ CAN_TX_TRACK_LAT_RATE : 7|6@0- (0.25,0) [-8|7.75] "" Vector__XXX
 SG_ CAN_TX_TRACK_BRIDGE_OBJECT : 39|1@0+ (1,0) [0|0] "" Vector__XXX
 SG_ CAN_TX_TRACK_WIDTH : 37|4@0+ (0.5,0) [0|7.5] "m" Vector__XXX
 SG_ CAN_TX_TRACK_STATUS : 15|3@0+ (1,0) [0|7] "" Vector__XXX
 SG_ CAN_TX_TRACK_ROLLING_COUNT : 38|1@0+ (1,0) [0|1] "" Vector__XXX
 SG_ CAN_TX_TRACK_RANGE_RATE : 53|14@0- (0.01,0) [-81.92|81.91] "m/s" Vector__XXX
 SG_ CAN_TX_TRACK_RANGE_ACCEL : 33|10@0- (0.05,0) [-25.6|25.55] "m/s/s" Vector__XXX
 SG_ CAN_TX_TRACK_RANGE : 18|11@0+ (0.1,0) [0|204.7] "m" Vector__XXX
 SG_ CAN_TX_TRACK_MED_RANGE_MODE : 55|2@0+ (1,0) [0|3] "" Vector__XXX
 SG_ CAN_TX_TRACK_ANGLE : 12|10@0- (0.1,0) [-51.2|51.1] "deg" Vector__XXX

BO_ 1322 ESR_Track43: 8 ESR
 SG_ CAN_TX_TRACK_GROUPING_CHANGED : 1|1@0+ (1,0) [0|0] "" Vector__XXX
 SG_ CAN_TX_TRACK_ONCOMING : 0|1@0+ (1,0) [0|0] "" Vector__XXX
 SG_ CAN_TX_TRACK_LAT_RATE : 7|6@0- (0.25,0) [-8|7.75] "" Vector__XXX
 SG_ CAN_TX_TRACK_BRIDGE_OBJECT : 39|1@0+ (1,0) [0|0] "" Vector__XXX
 SG_ CAN_TX_TRACK_WIDTH : 37|4@0+ (0.5,0) [0|7.5] "m" Vector__XXX
 SG_ CAN_TX_TRACK_STATUS : 15|3@0+ (1,0) [0|7] "" Vector__XXX
 SG_ CAN_TX_TRACK_ROLLING_COUNT : 38|1@0+ (1,0) [0|1] "" Vector__XXX
 SG_ CAN_TX_TRACK_RANGE_RATE : 53|14@0- (0.01,0) [-81.92|81.91] "m/s" Vector__XXX
 SG_ CAN_TX_TRACK_RANGE_ACCEL : 33|10@0- (0.05,0) [-25.6|25.55] "m/s/s" Vector__XXX
 SG_ CAN_TX_TRACK_RANGE : 18|11@0+ (0.1,0) [0|204.7] "m" Vector__XXX
 SG_ CAN_TX_TRACK_MED_RANGE_MODE : 55|2@0+ (1,0) [0|3] "" Vector__XXX
 SG_ CAN_TX_TRACK_ANGLE : 12|10@0- (0.1,0) [-51.2|51.1] "deg" Vector__XXX

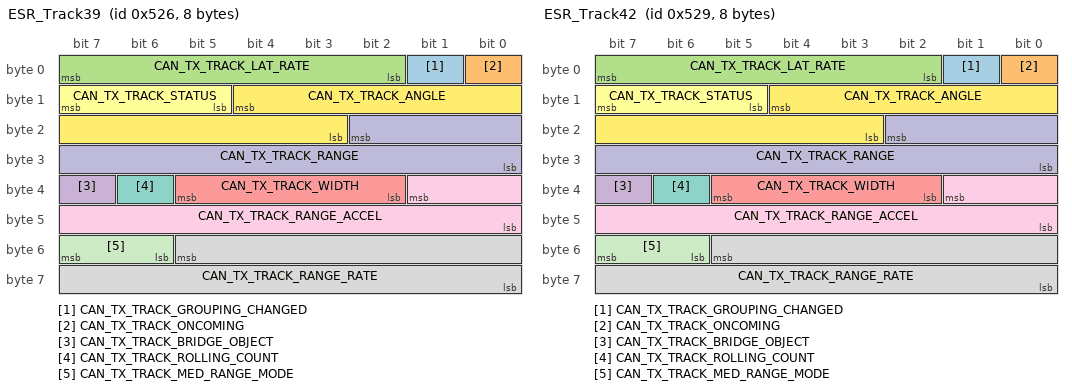
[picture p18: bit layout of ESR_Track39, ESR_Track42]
BO_ 1318 ESR_Track39: 8 ESR
 SG_ CAN_TX_TRACK_GROUPING_CHANGED : 1|1@0+ (1,0) [0|0] "" Vector__XXX
 SG_ CAN_TX_TRACK_ONCOMING : 0|1@0+ (1,0) [0|0] "" Vector__XXX
 SG_ CAN_TX_TRACK_LAT_RATE : 7|6@0- (0.25,0) [-8|7.75] "" Vector__XXX
 SG_ CAN_TX_TRACK_BRIDGE_OBJECT : 39|1@0+ (1,0) [0|0] "" Vector__XXX
 SG_ CAN_TX_TRACK_WIDTH : 37|4@0+ (0.5,0) [0|7.5] "m" Vector__XXX
 SG_ CAN_TX_TRACK_STATUS : 15|3@0+ (1,0) [0|7] "" Vector__XXX
 SG_ CAN_TX_TRACK_ROLLING_COUNT : 38|1@0+ (1,0) [0|1] "" Vector__XXX
 SG_ CAN_TX_TRACK_RANGE_RATE : 53|14@0- (0.01,0) [-81.92|81.91] "m/s" Vector__XXX
 SG_ CAN_TX_TRACK_RANGE_ACCEL : 33|10@0- (0.05,0) [-25.6|25.55] "m/s/s" Vector__XXX
 SG_ CAN_TX_TRACK_RANGE : 18|11@0+ (0.1,0) [0|204.7] "m" Vector__XXX
 SG_ CAN_TX_TRACK_MED_RANGE_MODE : 55|2@0+ (1,0) [0|3] "" Vector__XXX
 SG_ CAN_TX_TRACK_ANGLE : 12|10@0- (0.1,0) [-51.2|51.1] "deg" Vector__XXX

BO_ 1321 ESR_Track42: 8 ESR
 SG_ CAN_TX_TRACK_GROUPING_CHANGED : 1|1@0+ (1,0) [0|0] "" Vector__XXX
 SG_ CAN_TX_TRACK_ONCOMING : 0|1@0+ (1,0) [0|0] "" Vector__XXX
 SG_ CAN_TX_TRACK_LAT_RATE : 7|6@0- (0.25,0) [-8|7.75] "" Vector__XXX
 SG_ CAN_TX_TRACK_BRIDGE_OBJECT : 39|1@0+ (1,0) [0|0] "" Vector__XXX
 SG_ CAN_TX_TRACK_WIDTH : 37|4@0+ (0.5,0) [0|7.5] "m" Vector__XXX
 SG_ CAN_TX_TRACK_STATUS : 15|3@0+ (1,0) [0|7] "" Vector__XXX
 SG_ CAN_TX_TRACK_ROLLING_COUNT : 38|1@0+ (1,0) [0|1] "" Vector__XXX
 SG_ CAN_TX_TRACK_RANGE_RATE : 53|14@0- (0.01,0) [-81.92|81.91] "m/s" Vector__XXX
 SG_ CAN_TX_TRACK_RANGE_ACCEL : 33|10@0- (0.05,0) [-25.6|25.55] "m/s/s" Vector__XXX
 SG_ CAN_TX_TRACK_RANGE : 18|11@0+ (0.1,0) [0|204.7] "m" Vector__XXX
 SG_ CAN_TX_TRACK_MED_RANGE_MODE : 55|2@0+ (1,0) [0|3] "" Vector__XXX
 SG_ CAN_TX_TRACK_ANGLE : 12|10@0- (0.1,0) [-51.2|51.1] "deg" Vector__XXX

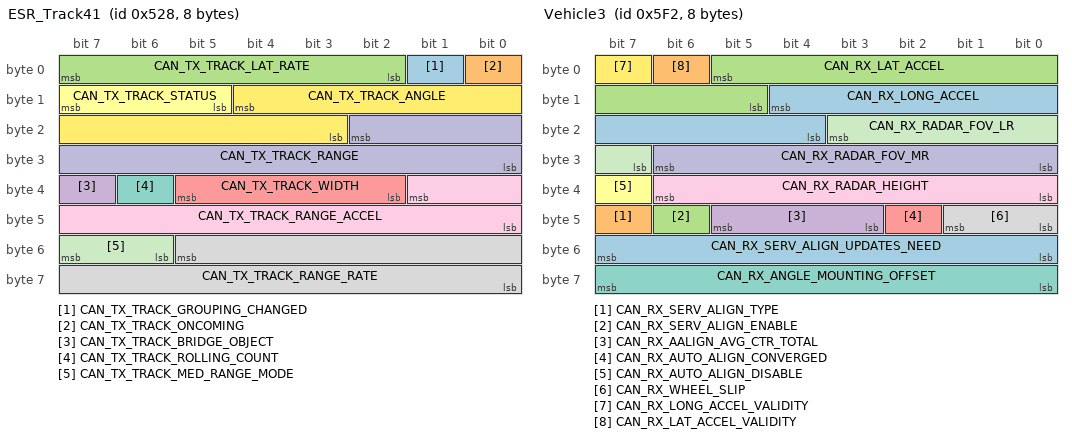
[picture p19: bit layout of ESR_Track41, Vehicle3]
BO_ 1320 ESR_Track41: 8 ESR
 SG_ CAN_TX_TRACK_GROUPING_CHANGED : 1|1@0+ (1,0) [0|0] "" Vector__XXX
 SG_ CAN_TX_TRACK_ONCOMING : 0|1@0+ (1,0) [0|0] "" Vector__XXX
 SG_ CAN_TX_TRACK_LAT_RATE : 7|6@0- (0.25,0) [-8|7.75] "" Vector__XXX
 SG_ CAN_TX_TRACK_BRIDGE_OBJECT : 39|1@0+ (1,0) [0|0] "" Vector__XXX
 SG_ CAN_TX_TRACK_WIDTH : 37|4@0+ (0.5,0) [0|7.5] "m" Vector__XXX
 SG_ CAN_TX_TRACK_STATUS : 15|3@0+ (1,0) [0|7] "" Vector__XXX
 SG_ CAN_TX_TRACK_ROLLING_COUNT : 38|1@0+ (1,0) [0|1] "" Vector__XXX
 SG_ CAN_TX_TRACK_RANGE_RATE : 53|14@0- (0.01,0) [-81.92|81.91] "m/s" Vector__XXX
 SG_ CAN_TX_TRACK_RANGE_ACCEL : 33|10@0- (0.05,0) [-25.6|25.55] "m/s/s" Vector__XXX
 SG_ CAN_TX_TRACK_RANGE : 18|11@0+ (0.1,0) [0|204.7] "m" Vector__XXX
 SG_ CAN_TX_TRACK_MED_RANGE_MODE : 55|2@0+ (1,0) [0|3] "" Vector__XXX
 SG_ CAN_TX_TRACK_ANGLE : 12|10@0- (0.1,0) [-51.2|51.1] "deg" Vector__XXX

BO_ 1319 ESR_Track40: 8 ESR
 SG_ CAN_TX_TRACK_GROUPING_CHANGED : 1|1@0+ (1,0) [0|0] "" Vector__XXX
 SG_ CAN_TX_TRACK_ONCOMING : 0|1@0+ (1,0) [0|0] "" Vector__XXX
 SG_ CAN_TX_TRACK_LAT_RATE : 7|6@0- (0.25,0) [-8|7.75] "" Vector__XXX
 SG_ CAN_TX_TRACK_BRIDGE_OBJECT : 39|1@0+ (1,0) [0|0] "" Vector__XXX
 SG_ CAN_TX_TRACK_WIDTH : 37|4@0+ (0.5,0) [0|7.5] "m" Vector__XXX
 SG_ CAN_TX_TRACK_STATUS : 15|3@0+ (1,0) [0|7] "" Vector__XXX
 SG_ CAN_TX_TRACK_ROLLING_COUNT : 38|1@0+ (1,0) [0|1] "" Vector__XXX
 SG_ CAN_TX_TRACK_RANGE_RATE : 53|14@0- (0.01,0) [-81.92|81.91] "m/s" Vector__XXX
 SG_ CAN_TX_TRACK_RANGE_ACCEL : 33|10@0- (0.05,0) [-25.6|25.55] "m/s/s" Vector__XXX
 SG_ CAN_TX_TRACK_RANGE : 18|11@0+ (0.1,0) [0|204.7] "m" Vector__XXX
 SG_ CAN_TX_TRACK_MED_RANGE_MODE : 55|2@0+ (1,0) [0|3] "" Vector__XXX
 SG_ CAN_TX_TRACK_ANGLE : 12|10@0- (0.1,0) [-51.2|51.1] "deg" Vector__XXX

BO_ 1323 ESR_Track44: 8 ESR
 SG_ CAN_TX_TRACK_GROUPING_CHANGED : 1|1@0+ (1,0) [0|0] "" Vector__XXX
 SG_ CAN_TX_TRACK_ONCOMING : 0|1@0+ (1,0) [0|0] "" Vector__XXX
 SG_ CAN_TX_TRACK_LAT_RATE : 7|6@0- (0.25,0) [-8|7.75] "" Vector__XXX
 SG_ CAN_TX_TRACK_BRIDGE_OBJECT : 39|1@0+ (1,0) [0|0] "" Vector__XXX
 SG_ CAN_TX_TRACK_WIDTH : 37|4@0+ (0.5,0) [0|7.5] "m" Vector__XXX
 SG_ CAN_TX_TRACK_STATUS : 15|3@0+ (1,0) [0|7] "" Vector__XXX
 SG_ CAN_TX_TRACK_ROLLING_COUNT : 38|1@0+ (1,0) [0|1] "" Vector__XXX
 SG_ CAN_TX_TRACK_RANGE_RATE : 53|14@0- (0.01,0) [-81.92|81.91] "m/s" Vector__XXX
 SG_ CAN_TX_TRACK_RANGE_ACCEL : 33|10@0- (0.05,0) [-25.6|25.55] "m/s/s" Vector__XXX
 SG_ CAN_TX_TRACK_RANGE : 18|11@0+ (0.1,0) [0|204.7] "m" Vector__XXX
 SG_ CAN_TX_TRACK_MED_RANGE_MODE : 55|2@0+ (1,0) [0|3] "" Vector__XXX
 SG_ CAN_TX_TRACK_ANGLE : 12|10@0- (0.1,0) [-51.2|51.1] "deg" Vector__XXX

BO_ 1329 ESR_Track50: 8 ESR
 SG_ CAN_TX_TRACK_GROUPING_CHANGED : 1|1@0+ (1,0) [0|0] "" Vector__XXX
 SG_ CAN_TX_TRACK_ONCOMING : 0|1@0+ (1,0) [0|0] "" Vector__XXX
 SG_ CAN_TX_TRACK_LAT_RATE : 7|6@0- (0.25,0) [-8|7.75] "" Vector__XXX
 SG_ CAN_TX_TRACK_BRIDGE_OBJECT : 39|1@0+ (1,0) [0|0] "" Vector__XXX
 SG_ CAN_TX_TRACK_WIDTH : 37|4@0+ (0.5,0) [0|7.5] "m" Vector__XXX
 SG_ CAN_TX_TRACK_STATUS : 15|3@0+ (1,0) [0|7] "" Vector__XXX
 SG_ CAN_TX_TRACK_ROLLING_COUNT : 38|1@0+ (1,0) [0|1] "" Vector__XXX
 SG_ CAN_TX_TRACK_RANGE_RATE : 53|14@0- (0.01,0) [-81.92|81.91] "m/s" Vector__XXX
 SG_ CAN_TX_TRACK_RANGE_ACCEL : 33|10@0- (0.05,0) [-25.6|25.55] "m/s/s" Vector__XXX
 SG_ CAN_TX_TRACK_RANGE : 18|11@0+ (0.1,0) [0|204.7] "m" Vector__XXX
 SG_ CAN_TX_TRACK_MED_RANGE_MODE : 55|2@0+ (1,0) [0|3] "" Vector__XXX
 SG_ CAN_TX_TRACK_ANGLE : 12|10@0- (0.1,0) [-51.2|51.1] "deg" Vector__XXX

BO_ 1326 ESR_Track47: 8 ESR
 SG_ CAN_TX_TRACK_GROUPING_CHANGED : 1|1@0+ (1,0) [0|0] "" Vector__XXX
 SG_ CAN_TX_TRACK_ONCOMING : 0|1@0+ (1,0) [0|0] "" Vector__XXX
 SG_ CAN_TX_TRACK_LAT_RATE : 7|6@0- (0.25,0) [-8|7.75] "" Vector__XXX
 SG_ CAN_TX_TRACK_BRIDGE_OBJECT : 39|1@0+ (1,0) [0|0] "" Vector__XXX
 SG_ CAN_TX_TRACK_WIDTH : 37|4@0+ (0.5,0) [0|7.5] "m" Vector__XXX
 SG_ CAN_TX_TRACK_STATUS : 15|3@0+ (1,0) [0|7] "" Vector__XXX
 SG_ CAN_TX_TRACK_ROLLING_COUNT : 38|1@0+ (1,0) [0|1] "" Vector__XXX
 SG_ CAN_TX_TRACK_RANGE_RATE : 53|14@0- (0.01,0) [-81.92|81.91] "m/s" Vector__XXX
 SG_ CAN_TX_TRACK_RANGE_ACCEL : 33|10@0- (0.05,0) [-25.6|25.55] "m/s/s" Vector__XXX
 SG_ CAN_TX_TRACK_RANGE : 18|11@0+ (0.1,0) [0|204.7] "m" Vector__XXX
 SG_ CAN_TX_TRACK_MED_RANGE_MODE : 55|2@0+ (1,0) [0|3] "" Vector__XXX
 SG_ CAN_TX_TRACK_ANGLE : 12|10@0- (0.1,0) [-51.2|51.1] "deg" Vector__XXX

BO_ 1342 ESR_Track63: 8 ESR
 SG_ CAN_TX_TRACK_GROUPING_CHANGED : 1|1@0+ (1,0) [0|0] "" Vector__XXX
 SG_ CAN_TX_TRACK_ONCOMING : 0|1@0+ (1,0) [0|0] "" Vector__XXX
 SG_ CAN_TX_TRACK_LAT_RATE : 7|6@0- (0.25,0) [-8|7.75] "" Vector__XXX
 SG_ CAN_TX_TRACK_BRIDGE_OBJECT : 39|1@0+ (1,0) [0|0] "" Vector__XXX
 SG_ CAN_TX_TRACK_WIDTH : 37|4@0+ (0.5,0) [0|7.5] "m" Vector__XXX
 SG_ CAN_TX_TRACK_STATUS : 15|3@0+ (1,0) [0|7] "" Vector__XXX
 SG_ CAN_TX_TRACK_ROLLING_COUNT : 38|1@0+ (1,0) [0|1] "" Vector__XXX
 SG_ CAN_TX_TRACK_RANGE_RATE : 53|14@0- (0.01,0) [-81.92|81.91] "m/s" Vector__XXX
 SG_ CAN_TX_TRACK_RANGE_ACCEL : 33|10@0- (0.05,0) [-25.6|25.55] "m/s/s" Vector__XXX
 SG_ CAN_TX_TRACK_RANGE : 18|11@0+ (0.1,0) [0|204.7] "m" Vector__XXX
 SG_ CAN_TX_TRACK_MED_RANGE_MODE : 55|2@0+ (1,0) [0|3] "" Vector__XXX
 SG_ CAN_TX_TRACK_ANGLE : 12|10@0- (0.1,0) [-51.2|51.1] "deg" Vector__XXX

BO_ 1340 ESR_Track61: 8 ESR
 SG_ CAN_TX_TRACK_GROUPING_CHANGED : 1|1@0+ (1,0) [0|0] "" Vector__XXX
 SG_ CAN_TX_TRACK_ONCOMING : 0|1@0+ (1,0) [0|0] "" Vector__XXX
 SG_ CAN_TX_TRACK_LAT_RATE : 7|6@0- (0.25,0) [-8|7.75] "" Vector__XXX
 SG_ CAN_TX_TRACK_BRIDGE_OBJECT : 39|1@0+ (1,0) [0|0] "" Vector__XXX
 SG_ CAN_TX_TRACK_WIDTH : 37|4@0+ (0.5,0) [0|7.5] "m" Vector__XXX
 SG_ CAN_TX_TRACK_STATUS : 15|3@0+ (1,0) [0|7] "" Vector__XXX
 SG_ CAN_TX_TRACK_ROLLING_COUNT : 38|1@0+ (1,0) [0|1] "" Vector__XXX
 SG_ CAN_TX_TRACK_RANGE_RATE : 53|14@0- (0.01,0) [-81.92|81.91] "m/s" Vector__XXX
 SG_ CAN_TX_TRACK_RANGE_ACCEL : 33|10@0- (0.05,0) [-25.6|25.55] "m/s/s" Vector__XXX
 SG_ CAN_TX_TRACK_RANGE : 18|11@0+ (0.1,0) [0|204.7] "m" Vector__XXX
 SG_ CAN_TX_TRACK_MED_RANGE_MODE : 55|2@0+ (1,0) [0|3] "" Vector__XXX
 SG_ CAN_TX_TRACK_ANGLE : 12|10@0- (0.1,0) [-51.2|51.1] "deg" Vector__XXX

BO_ 1333 ESR_Track54: 8 ESR
 SG_ CAN_TX_TRACK_GROUPING_CHANGED : 1|1@0+ (1,0) [0|0] "" Vector__XXX
 SG_ CAN_TX_TRACK_ONCOMING : 0|1@0+ (1,0) [0|0] "" Vector__XXX
 SG_ CAN_TX_TRACK_LAT_RATE : 7|6@0- (0.25,0) [-8|7.75] "" Vector__XXX
 SG_ CAN_TX_TRACK_BRIDGE_OBJECT : 39|1@0+ (1,0) [0|0] "" Vector__XXX
 SG_ CAN_TX_TRACK_WIDTH : 37|4@0+ (0.5,0) [0|7.5] "m" Vector__XXX
 SG_ CAN_TX_TRACK_STATUS : 15|3@0+ (1,0) [0|7] "" Vector__XXX
 SG_ CAN_TX_TRACK_ROLLING_COUNT : 38|1@0+ (1,0) [0|1] "" Vector__XXX
 SG_ CAN_TX_TRACK_RANGE_RATE : 53|14@0- (0.01,0) [-81.92|81.91] "m/s" Vector__XXX
 SG_ CAN_TX_TRACK_RANGE_ACCEL : 33|10@0- (0.05,0) [-25.6|25.55] "m/s/s" Vector__XXX
 SG_ CAN_TX_TRACK_RANGE : 18|11@0+ (0.1,0) [0|204.7] "m" Vector__XXX
 SG_ CAN_TX_TRACK_MED_RANGE_MODE : 55|2@0+ (1,0) [0|3] "" Vector__XXX
 SG_ CAN_TX_TRACK_ANGLE : 12|10@0- (0.1,0) [-51.2|51.1] "deg" Vector__XXX

BO_ 1335 ESR_Track56: 8 ESR
 SG_ CAN_TX_TRACK_GROUPING_CHANGED : 1|1@0+ (1,0) [0|0] "" Vector__XXX
 SG_ CAN_TX_TRACK_ONCOMING : 0|1@0+ (1,0) [0|0] "" Vector__XXX
 SG_ CAN_TX_TRACK_LAT_RATE : 7|6@0- (0.25,0) [-8|7.75] "" Vector__XXX
 SG_ CAN_TX_TRACK_BRIDGE_OBJECT : 39|1@0+ (1,0) [0|0] "" Vector__XXX
 SG_ CAN_TX_TRACK_WIDTH : 37|4@0+ (0.5,0) [0|7.5] "m" Vector__XXX
 SG_ CAN_TX_TRACK_STATUS : 15|3@0+ (1,0) [0|7] "" Vector__XXX
 SG_ CAN_TX_TRACK_ROLLING_COUNT : 38|1@0+ (1,0) [0|1] "" Vector__XXX
 SG_ CAN_TX_TRACK_RANGE_RATE : 53|14@0- (0.01,0) [-81.92|81.91] "m/s" Vector__XXX
 SG_ CAN_TX_TRACK_RANGE_ACCEL : 33|10@0- (0.05,0) [-25.6|25.55] "m/s/s" Vector__XXX
 SG_ CAN_TX_TRACK_RANGE : 18|11@0+ (0.1,0) [0|204.7] "m" Vector__XXX
 SG_ CAN_TX_TRACK_MED_RANGE_MODE : 55|2@0+ (1,0) [0|3] "" Vector__XXX
 SG_ CAN_TX_TRACK_ANGLE : 12|10@0- (0.1,0) [-51.2|51.1] "deg" Vector__XXX

BO_ 1337 ESR_Track58: 8 ESR
 SG_ CAN_TX_TRACK_GROUPING_CHANGED : 1|1@0+ (1,0) [0|0] "" Vector__XXX
 SG_ CAN_TX_TRACK_ONCOMING : 0|1@0+ (1,0) [0|0] "" Vector__XXX
 SG_ CAN_TX_TRACK_LAT_RATE : 7|6@0- (0.25,0) [-8|7.75] "" Vector__XXX
 SG_ CAN_TX_TRACK_BRIDGE_OBJECT : 39|1@0+ (1,0) [0|0] "" Vector__XXX
 SG_ CAN_TX_TRACK_WIDTH : 37|4@0+ (0.5,0) [0|7.5] "m" Vector__XXX
 SG_ CAN_TX_TRACK_STATUS : 15|3@0+ (1,0) [0|7] "" Vector__XXX
 SG_ CAN_TX_TRACK_ROLLING_COUNT : 38|1@0+ (1,0) [0|1] "" Vector__XXX
 SG_ CAN_TX_TRACK_RANGE_RATE : 53|14@0- (0.01,0) [-81.92|81.91] "m/s" Vector__XXX
 SG_ CAN_TX_TRACK_RANGE_ACCEL : 33|10@0- (0.05,0) [-25.6|25.55] "m/s/s" Vector__XXX
 SG_ CAN_TX_TRACK_RANGE : 18|11@0+ (0.1,0) [0|204.7] "m" Vector__XXX
 SG_ CAN_TX_TRACK_MED_RANGE_MODE : 55|2@0+ (1,0) [0|3] "" Vector__XXX
 SG_ CAN_TX_TRACK_ANGLE : 12|10@0- (0.1,0) [-51.2|51.1] "deg" Vector__XXX

BO_ 1331 ESR_Track52: 8 ESR
 SG_ CAN_TX_TRACK_GROUPING_CHANGED : 1|1@0+ (1,0) [0|0] "" Vector__XXX
 SG_ CAN_TX_TRACK_ONCOMING : 0|1@0+ (1,0) [0|0] "" Vector__XXX
 SG_ CAN_TX_TRACK_LAT_RATE : 7|6@0- (0.25,0) [-8|7.75] "" Vector__XXX
 SG_ CAN_TX_TRACK_BRIDGE_OBJECT : 39|1@0+ (1,0) [0|0] "" Vector__XXX
 SG_ CAN_TX_TRACK_WIDTH : 37|4@0+ (0.5,0) [0|7.5] "m" Vector__XXX
 SG_ CAN_TX_TRACK_STATUS : 15|3@0+ (1,0) [0|7] "" Vector__XXX
 SG_ CAN_TX_TRACK_ROLLING_COUNT : 38|1@0+ (1,0) [0|1] "" Vector__XXX
 SG_ CAN_TX_TRACK_RANGE_RATE : 53|14@0- (0.01,0) [-81.92|81.91] "m/s" Vector__XXX
 SG_ CAN_TX_TRACK_RANGE_ACCEL : 33|10@0- (0.05,0) [-25.6|25.55] "m/s/s" Vector__XXX
 SG_ CAN_TX_TRACK_RANGE : 18|11@0+ (0.1,0) [0|204.7] "m" Vector__XXX
 SG_ CAN_TX_TRACK_MED_RANGE_MODE : 55|2@0+ (1,0) [0|3] "" Vector__XXX
 SG_ CAN_TX_TRACK_ANGLE : 12|10@0- (0.1,0) [-51.2|51.1] "deg" Vector__XXX

BO_ 1338 ESR_Track59: 8 ESR
 SG_ CAN_TX_TRACK_GROUPING_CHANGED : 1|1@0+ (1,0) [0|0] "" Vector__XXX
 SG_ CAN_TX_TRACK_ONCOMING : 0|1@0+ (1,0) [0|0] "" Vector__XXX
 SG_ CAN_TX_TRACK_LAT_RATE : 7|6@0- (0.25,0) [-8|7.75] "" Vector__XXX
 SG_ CAN_TX_TRACK_BRIDGE_OBJECT : 39|1@0+ (1,0) [0|0] "" Vector__XXX
 SG_ CAN_TX_TRACK_WIDTH : 37|4@0+ (0.5,0) [0|7.5] "m" Vector__XXX
 SG_ CAN_TX_TRACK_STATUS : 15|3@0+ (1,0) [0|7] "" Vector__XXX
 SG_ CAN_TX_TRACK_ROLLING_COUNT : 38|1@0+ (1,0) [0|1] "" Vector__XXX
 SG_ CAN_TX_TRACK_RANGE_RATE : 53|14@0- (0.01,0) [-81.92|81.91] "m/s" Vector__XXX
 SG_ CAN_TX_TRACK_RANGE_ACCEL : 33|10@0- (0.05,0) [-25.6|25.55] "m/s/s" Vector__XXX
 SG_ CAN_TX_TRACK_RANGE : 18|11@0+ (0.1,0) [0|204.7] "m" Vector__XXX
 SG_ CAN_TX_TRACK_MED_RANGE_MODE : 55|2@0+ (1,0) [0|3] "" Vector__XXX
 SG_ CAN_TX_TRACK_ANGLE : 12|10@0- (0.1,0) [-51.2|51.1] "deg" Vector__XXX

BO_ 1336 ESR_Track57: 8 ESR
 SG_ CAN_TX_TRACK_GROUPING_CHANGED : 1|1@0+ (1,0) [0|0] "" Vector__XXX
 SG_ CAN_TX_TRACK_ONCOMING : 0|1@0+ (1,0) [0|0] "" Vector__XXX
 SG_ CAN_TX_TRACK_LAT_RATE : 7|6@0- (0.25,0) [-8|7.75] "" Vector__XXX
 SG_ CAN_TX_TRACK_BRIDGE_OBJECT : 39|1@0+ (1,0) [0|0] "" Vector__XXX
 SG_ CAN_TX_TRACK_WIDTH : 37|4@0+ (0.5,0) [0|7.5] "m" Vector__XXX
 SG_ CAN_TX_TRACK_STATUS : 15|3@0+ (1,0) [0|7] "" Vector__XXX
 SG_ CAN_TX_TRACK_ROLLING_COUNT : 38|1@0+ (1,0) [0|1] "" Vector__XXX
 SG_ CAN_TX_TRACK_RANGE_RATE : 53|14@0- (0.01,0) [-81.92|81.91] "m/s" Vector__XXX
 SG_ CAN_TX_TRACK_RANGE_ACCEL : 33|10@0- (0.05,0) [-25.6|25.55] "m/s/s" Vector__XXX
 SG_ CAN_TX_TRACK_RANGE : 18|11@0+ (0.1,0) [0|204.7] "m" Vector__XXX
 SG_ CAN_TX_TRACK_MED_RANGE_MODE : 55|2@0+ (1,0) [0|3] "" Vector__XXX
 SG_ CAN_TX_TRACK_ANGLE : 12|10@0- (0.1,0) [-51.2|51.1] "deg" Vector__XXX

BO_ 1334 ESR_Track55: 8 ESR
 SG_ CAN_TX_TRACK_GROUPING_CHANGED : 1|1@0+ (1,0) [0|0] "" Vector__XXX
 SG_ CAN_TX_TRACK_ONCOMING : 0|1@0+ (1,0) [0|0] "" Vector__XXX
 SG_ CAN_TX_TRACK_LAT_RATE : 7|6@0- (0.25,0) [-8|7.75] "" Vector__XXX
 SG_ CAN_TX_TRACK_BRIDGE_OBJECT : 39|1@0+ (1,0) [0|0] "" Vector__XXX
 SG_ CAN_TX_TRACK_WIDTH : 37|4@0+ (0.5,0) [0|7.5] "m" Vector__XXX
 SG_ CAN_TX_TRACK_STATUS : 15|3@0+ (1,0) [0|7] "" Vector__XXX
 SG_ CAN_TX_TRACK_ROLLING_COUNT : 38|1@0+ (1,0) [0|1] "" Vector__XXX
 SG_ CAN_TX_TRACK_RANGE_RATE : 53|14@0- (0.01,0) [-81.92|81.91] "m/s" Vector__XXX
 SG_ CAN_TX_TRACK_RANGE_ACCEL : 33|10@0- (0.05,0) [-25.6|25.55] "m/s/s" Vector__XXX
 SG_ CAN_TX_TRACK_RANGE : 18|11@0+ (0.1,0) [0|204.7] "m" Vector__XXX
 SG_ CAN_TX_TRACK_MED_RANGE_MODE : 55|2@0+ (1,0) [0|3] "" Vector__XXX
 SG_ CAN_TX_TRACK_ANGLE : 12|10@0- (0.1,0) [-51.2|51.1] "deg" Vector__XXX

BO_ 1330 ESR_Track51: 8 ESR
 SG_ CAN_TX_TRACK_GROUPING_CHANGED : 1|1@0+ (1,0) [0|0] "" Vector__XXX
 SG_ CAN_TX_TRACK_ONCOMING : 0|1@0+ (1,0) [0|0] "" Vector__XXX
 SG_ CAN_TX_TRACK_LAT_RATE : 7|6@0- (0.25,0) [-8|7.75] "" Vector__XXX
 SG_ CAN_TX_TRACK_BRIDGE_OBJECT : 39|1@0+ (1,0) [0|0] "" Vector__XXX
 SG_ CAN_TX_TRACK_WIDTH : 37|4@0+ (0.5,0) [0|7.5] "m" Vector__XXX
 SG_ CAN_TX_TRACK_STATUS : 15|3@0+ (1,0) [0|7] "" Vector__XXX
 SG_ CAN_TX_TRACK_ROLLING_COUNT : 38|1@0+ (1,0) [0|1] "" Vector__XXX
 SG_ CAN_TX_TRACK_RANGE_RATE : 53|14@0- (0.01,0) [-81.92|81.91] "m/s" Vector__XXX
 SG_ CAN_TX_TRACK_RANGE_ACCEL : 33|10@0- (0.05,0) [-25.6|25.55] "m/s/s" Vector__XXX
 SG_ CAN_TX_TRACK_RANGE : 18|11@0+ (0.1,0) [0|204.7] "m" Vector__XXX
 SG_ CAN_TX_TRACK_MED_RANGE_MODE : 55|2@0+ (1,0) [0|3] "" Vector__XXX
 SG_ CAN_TX_TRACK_ANGLE : 12|10@0- (0.1,0) [-51.2|51.1] "deg" Vector__XXX

BO_ 1328 ESR_Track49: 8 ESR
 SG_ CAN_TX_TRACK_GROUPING_CHANGED : 1|1@0+ (1,0) [0|0] "" Vector__XXX
 SG_ CAN_TX_TRACK_ONCOMING : 0|1@0+ (1,0) [0|0] "" Vector__XXX
 SG_ CAN_TX_TRACK_LAT_RATE : 7|6@0- (0.25,0) [-8|7.75] "" Vector__XXX
 SG_ CAN_TX_TRACK_BRIDGE_OBJECT : 39|1@0+ (1,0) [0|0] "" Vector__XXX
 SG_ CAN_TX_TRACK_WIDTH : 37|4@0+ (0.5,0) [0|7.5] "m" Vector__XXX
 SG_ CAN_TX_TRACK_STATUS : 15|3@0+ (1,0) [0|7] "" Vector__XXX
 SG_ CAN_TX_TRACK_ROLLING_COUNT : 38|1@0+ (1,0) [0|1] "" Vector__XXX
 SG_ CAN_TX_TRACK_RANGE_RATE : 53|14@0- (0.01,0) [-81.92|81.91] "m/s" Vector__XXX
 SG_ CAN_TX_TRACK_RANGE_ACCEL : 33|10@0- (0.05,0) [-25.6|25.55] "m/s/s" Vector__XXX
 SG_ CAN_TX_TRACK_RANGE : 18|11@0+ (0.1,0) [0|204.7] "m" Vector__XXX
 SG_ CAN_TX_TRACK_MED_RANGE_MODE : 55|2@0+ (1,0) [0|3] "" Vector__XXX
 SG_ CAN_TX_TRACK_ANGLE : 12|10@0- (0.1,0) [-51.2|51.1] "deg" Vector__XXX

BO_ 1282 ESR_Track03: 8 ESR
 SG_ CAN_TX_TRACK_GROUPING_CHANGED : 1|1@0+ (1,0) [0|0] "" Vector__XXX
 SG_ CAN_TX_TRACK_ONCOMING : 0|1@0+ (1,0) [0|0] "" Vector__XXX
 SG_ CAN_TX_TRACK_LAT_RATE : 7|6@0- (0.25,0) [-8|7.75] "" Vector__XXX
 SG_ CAN_TX_TRACK_BRIDGE_OBJECT : 39|1@0+ (1,0) [0|0] "" Vector__XXX
 SG_ CAN_TX_TRACK_WIDTH : 37|4@0+ (0.5,0) [0|7.5] "m" Vector__XXX
 SG_ CAN_TX_TRACK_STATUS : 15|3@0+ (1,0) [0|7] "" Vector__XXX
 SG_ CAN_TX_TRACK_ROLLING_COUNT : 38|1@0+ (1,0) [0|1] "" Vector__XXX
 SG_ CAN_TX_TRACK_RANGE_RATE : 53|14@0- (0.01,0) [-81.92|81.91] "m/s" Vector__XXX
 SG_ CAN_TX_TRACK_RANGE_ACCEL : 33|10@0- (0.05,0) [-25.6|25.55] "m/s/s" Vector__XXX
 SG_ CAN_TX_TRACK_RANGE : 18|11@0+ (0.1,0) [0|204.7] "m" Vector__XXX
 SG_ CAN_TX_TRACK_MED_RANGE_MODE : 55|2@0+ (1,0) [0|3] "" Vector__XXX
 SG_ CAN_TX_TRACK_ANGLE : 12|10@0- (0.1,0) [-51.2|51.1] "deg" Vector__XXX

BO_ 1283 ESR_Track04: 8 ESR
 SG_ CAN_TX_TRACK_GROUPING_CHANGED : 1|1@0+ (1,0) [0|0] "" Vector__XXX
 SG_ CAN_TX_TRACK_ONCOMING : 0|1@0+ (1,0) [0|0] "" Vector__XXX
 SG_ CAN_TX_TRACK_LAT_RATE : 7|6@0- (0.25,0) [-8|7.75] "" Vector__XXX
 SG_ CAN_TX_TRACK_BRIDGE_OBJECT : 39|1@0+ (1,0) [0|0] "" Vector__XXX
 SG_ CAN_TX_TRACK_WIDTH : 37|4@0+ (0.5,0) [0|7.5] "m" Vector__XXX
 SG_ CAN_TX_TRACK_STATUS : 15|3@0+ (1,0) [0|7] "" Vector__XXX
 SG_ CAN_TX_TRACK_ROLLING_COUNT : 38|1@0+ (1,0) [0|1] "" Vector__XXX
 SG_ CAN_TX_TRACK_RANGE_RATE : 53|14@0- (0.01,0) [-81.92|81.91] "m/s" Vector__XXX
 SG_ CAN_TX_TRACK_RANGE_ACCEL : 33|10@0- (0.05,0) [-25.6|25.55] "m/s/s" Vector__XXX
 SG_ CAN_TX_TRACK_RANGE : 18|11@0+ (0.1,0) [0|204.7] "m" Vector__XXX
 SG_ CAN_TX_TRACK_MED_RANGE_MODE : 55|2@0+ (1,0) [0|3] "" Vector__XXX
 SG_ CAN_TX_TRACK_ANGLE : 12|10@0- (0.1,0) [-51.2|51.1] "deg" Vector__XXX

BO_ 1284 ESR_Track05: 8 ESR
 SG_ CAN_TX_TRACK_GROUPING_CHANGED : 1|1@0+ (1,0) [0|0] "" Vector__XXX
 SG_ CAN_TX_TRACK_ONCOMING : 0|1@0+ (1,0) [0|0] "" Vector__XXX
 SG_ CAN_TX_TRACK_LAT_RATE : 7|6@0- (0.25,0) [-8|7.75] "" Vector__XXX
 SG_ CAN_TX_TRACK_BRIDGE_OBJECT : 39|1@0+ (1,0) [0|0] "" Vector__XXX
 SG_ CAN_TX_TRACK_WIDTH : 37|4@0+ (0.5,0) [0|7.5] "m" Vector__XXX
 SG_ CAN_TX_TRACK_STATUS : 15|3@0+ (1,0) [0|7] "" Vector__XXX
 SG_ CAN_TX_TRACK_ROLLING_COUNT : 38|1@0+ (1,0) [0|1] "" Vector__XXX
 SG_ CAN_TX_TRACK_RANGE_RATE : 53|14@0- (0.01,0) [-81.92|81.91] "m/s" Vector__XXX
 SG_ CAN_TX_TRACK_RANGE_ACCEL : 33|10@0- (0.05,0) [-25.6|25.55] "m/s/s" Vector__XXX
 SG_ CAN_TX_TRACK_RANGE : 18|11@0+ (0.1,0) [0|204.7] "m" Vector__XXX
 SG_ CAN_TX_TRACK_MED_RANGE_MODE : 55|2@0+ (1,0) [0|3] "" Vector__XXX
 SG_ CAN_TX_TRACK_ANGLE : 12|10@0- (0.1,0) [-51.2|51.1] "deg" Vector__XXX

BO_ 1311 ESR_Track32: 8 ESR
 SG_ CAN_TX_TRACK_GROUPING_CHANGED : 1|1@0+ (1,0) [0|0] "" Vector__XXX
 SG_ CAN_TX_TRACK_ONCOMING : 0|1@0+ (1,0) [0|0] "" Vector__XXX
 SG_ CAN_TX_TRACK_LAT_RATE : 7|6@0- (0.25,0) [-8|7.75] "" Vector__XXX
 SG_ CAN_TX_TRACK_BRIDGE_OBJECT : 39|1@0+ (1,0) [0|0] "" Vector__XXX
 SG_ CAN_TX_TRACK_WIDTH : 37|4@0+ (0.5,0) [0|7.5] "m" Vector__XXX
 SG_ CAN_TX_TRACK_STATUS : 15|3@0+ (1,0) [0|7] "" Vector__XXX
 SG_ CAN_TX_TRACK_ROLLING_COUNT : 38|1@0+ (1,0) [0|1] "" Vector__XXX
 SG_ CAN_TX_TRACK_RANGE_RATE : 53|14@0- (0.01,0) [-81.92|81.91] "m/s" Vector__XXX
 SG_ CAN_TX_TRACK_RANGE_ACCEL : 33|10@0- (0.05,0) [-25.6|25.55] "m/s/s" Vector__XXX
 SG_ CAN_TX_TRACK_RANGE : 18|11@0+ (0.1,0) [0|204.7] "m" Vector__XXX
 SG_ CAN_TX_TRACK_MED_RANGE_MODE : 55|2@0+ (1,0) [0|3] "" Vector__XXX
 SG_ CAN_TX_TRACK_ANGLE : 12|10@0- (0.1,0) [-51.2|51.1] "deg" Vector__XXX

BO_ 1290 ESR_Track11: 8 ESR
 SG_ CAN_TX_TRACK_GROUPING_CHANGED : 1|1@0+ (1,0) [0|0] "" Vector__XXX
 SG_ CAN_TX_TRACK_ONCOMING : 0|1@0+ (1,0) [0|0] "" Vector__XXX
 SG_ CAN_TX_TRACK_LAT_RATE : 7|6@0- (0.25,0) [-8|7.75] "" Vector__XXX
 SG_ CAN_TX_TRACK_BRIDGE_OBJECT : 39|1@0+ (1,0) [0|0] "" Vector__XXX
 SG_ CAN_TX_TRACK_WIDTH : 37|4@0+ (0.5,0) [0|7.5] "m" Vector__XXX
 SG_ CAN_TX_TRACK_STATUS : 15|3@0+ (1,0) [0|7] "" Vector__XXX
 SG_ CAN_TX_TRACK_ROLLING_COUNT : 38|1@0+ (1,0) [0|1] "" Vector__XXX
 SG_ CAN_TX_TRACK_RANGE_RATE : 53|14@0- (0.01,0) [-81.92|81.91] "m/s" Vector__XXX
 SG_ CAN_TX_TRACK_RANGE_ACCEL : 33|10@0- (0.05,0) [-25.6|25.55] "m/s/s" Vector__XXX
 SG_ CAN_TX_TRACK_RANGE : 18|11@0+ (0.1,0) [0|204.7] "m" Vector__XXX
 SG_ CAN_TX_TRACK_MED_RANGE_MODE : 55|2@0+ (1,0) [0|3] "" Vector__XXX
 SG_ CAN_TX_TRACK_ANGLE : 12|10@0- (0.1,0) [-51.2|51.1] "deg" Vector__XXX

BO_ 1293 ESR_Track14: 8 ESR
 SG_ CAN_TX_TRACK_GROUPING_CHANGED : 1|1@0+ (1,0) [0|0] "" Vector__XXX
 SG_ CAN_TX_TRACK_ONCOMING : 0|1@0+ (1,0) [0|0] "" Vector__XXX
 SG_ CAN_TX_TRACK_LAT_RATE : 7|6@0- (0.25,0) [-8|7.75] "" Vector__XXX
 SG_ CAN_TX_TRACK_BRIDGE_OBJECT : 39|1@0+ (1,0) [0|0] "" Vector__XXX
 SG_ CAN_TX_TRACK_WIDTH : 37|4@0+ (0.5,0) [0|7.5] "m" Vector__XXX
 SG_ CAN_TX_TRACK_STATUS : 15|3@0+ (1,0) [0|7] "" Vector__XXX
 SG_ CAN_TX_TRACK_ROLLING_COUNT : 38|1@0+ (1,0) [0|1] "" Vector__XXX
 SG_ CAN_TX_TRACK_RANGE_RATE : 53|14@0- (0.01,0) [-81.92|81.91] "m/s" Vector__XXX
 SG_ CAN_TX_TRACK_RANGE_ACCEL : 33|10@0- (0.05,0) [-25.6|25.55] "m/s/s" Vector__XXX
 SG_ CAN_TX_TRACK_RANGE : 18|11@0+ (0.1,0) [0|204.7] "m" Vector__XXX
 SG_ CAN_TX_TRACK_MED_RANGE_MODE : 55|2@0+ (1,0) [0|3] "" Vector__XXX
 SG_ CAN_TX_TRACK_ANGLE : 12|10@0- (0.1,0) [-51.2|51.1] "deg" Vector__XXX

BO_ 1325 ESR_Track46: 8 ESR
 SG_ CAN_TX_TRACK_GROUPING_CHANGED : 1|1@0+ (1,0) [0|0] "" Vector__XXX
 SG_ CAN_TX_TRACK_ONCOMING : 0|1@0+ (1,0) [0|0] "" Vector__XXX
 SG_ CAN_TX_TRACK_LAT_RATE : 7|6@0- (0.25,0) [-8|7.75] "" Vector__XXX
 SG_ CAN_TX_TRACK_BRIDGE_OBJECT : 39|1@0+ (1,0) [0|0] "" Vector__XXX
 SG_ CAN_TX_TRACK_WIDTH : 37|4@0+ (0.5,0) [0|7.5] "m" Vector__XXX
 SG_ CAN_TX_TRACK_STATUS : 15|3@0+ (1,0) [0|7] "" Vector__XXX
 SG_ CAN_TX_TRACK_ROLLING_COUNT : 38|1@0+ (1,0) [0|1] "" Vector__XXX
 SG_ CAN_TX_TRACK_RANGE_RATE : 53|14@0- (0.01,0) [-81.92|81.91] "m/s" Vector__XXX
 SG_ CAN_TX_TRACK_RANGE_ACCEL : 33|10@0- (0.05,0) [-25.6|25.55] "m/s/s" Vector__XXX
 SG_ CAN_TX_TRACK_RANGE : 18|11@0+ (0.1,0) [0|204.7] "m" Vector__XXX
 SG_ CAN_TX_TRACK_MED_RANGE_MODE : 55|2@0+ (1,0) [0|3] "" Vector__XXX
 SG_ CAN_TX_TRACK_ANGLE : 12|10@0- (0.1,0) [-51.2|51.1] "deg" Vector__XXX

BO_ 1341 ESR_Track62: 8 ESR
 SG_ CAN_TX_TRACK_GROUPING_CHANGED : 1|1@0+ (1,0) [0|0] "" Vector__XXX
 SG_ CAN_TX_TRACK_ONCOMING : 0|1@0+ (1,0) [0|0] "" Vector__XXX
 SG_ CAN_TX_TRACK_LAT_RATE : 7|6@0- (0.25,0) [-8|7.75] "" Vector__XXX
 SG_ CAN_TX_TRACK_BRIDGE_OBJECT : 39|1@0+ (1,0) [0|0] "" Vector__XXX
 SG_ CAN_TX_TRACK_WIDTH : 37|4@0+ (0.5,0) [0|7.5] "m" Vector__XXX
 SG_ CAN_TX_TRACK_STATUS : 15|3@0+ (1,0) [0|7] "" Vector__XXX
 SG_ CAN_TX_TRACK_ROLLING_COUNT : 38|1@0+ (1,0) [0|1] "" Vector__XXX
 SG_ CAN_TX_TRACK_RANGE_RATE : 53|14@0- (0.01,0) [-81.92|81.91] "m/s" Vector__XXX
 SG_ CAN_TX_TRACK_RANGE_ACCEL : 33|10@0- (0.05,0) [-25.6|25.55] "m/s/s" Vector__XXX
 SG_ CAN_TX_TRACK_RANGE : 18|11@0+ (0.1,0) [0|204.7] "m" Vector__XXX
 SG_ CAN_TX_TRACK_MED_RANGE_MODE : 55|2@0+ (1,0) [0|3] "" Vector__XXX
 SG_ CAN_TX_TRACK_ANGLE : 12|10@0- (0.1,0) [-51.2|51.1] "deg" Vector__XXX

BO_ 1281 ESR_Track02: 8 ESR
 SG_ CAN_TX_TRACK_GROUPING_CHANGED : 1|1@0+ (1,0) [0|0] "" Vector__XXX
 SG_ CAN_TX_TRACK_ONCOMING : 0|1@0+ (1,0) [0|0] "" Vector__XXX
 SG_ CAN_TX_TRACK_LAT_RATE : 7|6@0- (0.25,0) [-8|7.75] "" Vector__XXX
 SG_ CAN_TX_TRACK_BRIDGE_OBJECT : 39|1@0+ (1,0) [0|0] "" Vector__XXX
 SG_ CAN_TX_TRACK_WIDTH : 37|4@0+ (0.5,0) [0|7.5] "m" Vector__XXX
 SG_ CAN_TX_TRACK_STATUS : 15|3@0+ (1,0) [0|7] "" Vector__XXX
 SG_ CAN_TX_TRACK_ROLLING_COUNT : 38|1@0+ (1,0) [0|1] "" Vector__XXX
 SG_ CAN_TX_TRACK_RANGE_RATE : 53|14@0- (0.01,0) [-81.92|81.91] "m/s" Vector__XXX
 SG_ CAN_TX_TRACK_RANGE_ACCEL : 33|10@0- (0.05,0) [-25.6|25.55] "m/s/s" Vector__XXX
 SG_ CAN_TX_TRACK_RANGE : 18|11@0+ (0.1,0) [0|204.7] "m" Vector__XXX
 SG_ CAN_TX_TRACK_MED_RANGE_MODE : 55|2@0+ (1,0) [0|3] "" Vector__XXX
 SG_ CAN_TX_TRACK_ANGLE : 12|10@0- (0.1,0) [-51.2|51.1] "deg" Vector__XXX

BO_ 1935 MMR_XCP_Inst_DAQ16: 8 Vector__XXX

BO_ 1934 MMR_XCP_Inst_DAQ15: 8 Vector__XXX

BO_ 1933 MMR_XCP_Inst_DAQ14: 8 Vector__XXX

BO_ 1932 MMR_XCP_Inst_DAQ13: 8 Vector__XXX

BO_ 1931 MMR_XCP_Inst_DAQ12: 8 Vector__XXX

BO_ 1930 MMR_XCP_Inst_DAQ11: 8 Vector__XXX

BO_ 1929 MMR_XCP_Inst_DAQ10: 8 Vector__XXX

BO_ 1928 MMR_XCP_Inst_DAQ09: 8 Vector__XXX

BO_ 1927 MMR_XCP_Inst_DAQ08: 8 Vector__XXX

BO_ 1926 MMR_XCP_Inst_DAQ07: 8 Vector__XXX

BO_ 1925 MMR_XCP_Inst_DAQ06: 8 Vector__XXX

BO_ 1924 MMR_XCP_Inst_DAQ05: 8 Vector__XXX

BO_ 1923 MMR_XCP_Inst_DAQ04: 8 Vector__XXX

BO_ 1922 MMR_XCP_Inst_DAQ03: 8 Vector__XXX

BO_ 1921 MMR_XCP_Inst_DAQ02: 8 Vector__XXX

BO_ 1920 MMR_XCP_Inst_DAQ01: 8 Vector__XXX

BO_ 1891 MMR_XCP_Inst_Resp: 8 Vector__XXX

BO_ 1890 MMR_XCP_Inst_Req: 8 Vector__XXX

BO_ 1524 Vehicle5: 8 Vehicle
 SG_ CAN_RX_YAW_RATE_BIAS_SHIFT : 15|1@0+ (1,0) [0|0] "" Vector__XXX
 SG_ CAN_RX_STEERING_GEAR_RATIO : 63|8@0+ (0.125,0) [0|31.875] "" Vector__XXX
 SG_ CAN_RX_WHEELBASE : 55|8@0+ (2,200) [200|710] "cm" Vector__XXX
 SG_ CAN_RX_DISTANCE_REAR_AXLE : 47|8@0+ (2,200) [200|710] "cm" Vector__XXX
 SG_ CAN_RX_CW_BLOCKAGE_THRESHOLD : 39|8@0+ (0.0078125,0) [0|1.9921875] "" Vector__XXX
 SG_ CAN_RX_FUNNEL_OFFSET_RIGHT : 31|8@0- (0.1,0) [-2|10] "m" Vector__XXX
 SG_ CAN_RX_FUNNEL_OFFSET_LEFT : 23|8@0- (0.1,0) [-2|10] "m" Vector__XXX
 SG_ CAN_RX_BEAMWIDTH_VERT : 14|7@0+ (0.0625,0) [0|6] "deg" Vector__XXX
 SG_ CAN_RX_OVERSTEER_UNDERSTEER : 7|8@0- (1,0) [-128|127] "%" Vector__XXX

BO_ 1523 Vehicle4: 8 Vehicle
 SG_ CAN_RX_FAC_TGT_RANGE_R2M : 55|8@0+ (0.0625,0) [2|10] "m" Vector__XXX
 SG_ CAN_RX_FAC_TGT_RANGE_M2T : 63|8@0+ (0.0625,0) [1|10] "m" Vector__XXX
 SG_ CAN_RX_FAC_TGT_RANGE_1 : 47|8@0+ (0.0625,0) [2|10] "m" Vector__XXX
 SG_ CAN_RX_FAC_TGT_MTG_SPACE_VER : 39|8@0- (1,0) [-100|100] "cm" Vector__XXX
 SG_ CAN_RX_FAC_TGT_MTG_SPACE_HOR : 31|8@0- (1,0) [-100|100] "cm" Vector__XXX
 SG_ CAN_RX_FAC_TGT_MTG_OFFSET : 23|8@0- (1,0) [-100|100] "cm" Vector__XXX
 SG_ CAN_RX_FAC_ALIGN_SAMP_REQ : 14|7@0+ (1,0) [0|100] "" Vector__XXX
 SG_ CAN_RX_FAC_ALIGN_MAX_NT : 6|7@0+ (1,0) [0|100] "" Vector__XXX
 SG_ CAN_RX_FAC_ALIGN_CMD_2 : 7|1@0+ (1,0) [0|0] "" Vector__XXX
 SG_ CAN_RX_FAC_ALIGN_CMD_1 : 15|1@0+ (1,0) [0|0] "" Vector__XXX

BO_ 1522 Vehicle3: 8 Vehicle
 SG_ CAN_RX_SERV_ALIGN_UPDATES_NEED : 55|8@0+ (1,0) [0|0] "" Vector__XXX
 SG_ CAN_RX_SERV_ALIGN_TYPE : 47|1@0+ (1,0) [0|0] "" Vector__XXX
 SG_ CAN_RX_SERV_ALIGN_ENABLE : 46|1@0+ (1,0) [0|0] "" Vector__XXX
 SG_ CAN_RX_AALIGN_AVG_CTR_TOTAL : 45|3@0+ (250,250) [250|2000] "" Vector__XXX
 SG_ CAN_RX_AUTO_ALIGN_CONVERGED : 42|1@0+ (1,0) [0|0] "" Vector__XXX
 SG_ CAN_RX_AUTO_ALIGN_DISABLE : 39|1@0+ (1,0) [0|0] "" Vector__XXX
 SG_ CAN_RX_ANGLE_MOUNTING_OFFSET : 63|8@0- (0.0625,0) [-8|7.9375] "deg" Vector__XXX
 SG_ CAN_RX_WHEEL_SLIP : 41|2@0+ (1,0) [0|0] "" Vector__XXX
 SG_ CAN_RX_RADAR_HEIGHT : 38|7@0+ (1,0) [0|125] "cm" Vector__XXX
 SG_ CAN_RX_RADAR_FOV_MR : 30|7@0+ (1,0) [0|120] "deg" Vector__XXX
 SG_ CAN_RX_RADAR_FOV_LR : 19|5@0+ (1,0) [0|30] "deg" Vector__XXX
 SG_ CAN_RX_LONG_ACCEL_VALIDITY : 7|1@0+ (1,0) [0|0] "" Vector__XXX
 SG_ CAN_RX_LONG_ACCEL : 12|9@0- (0.03125,0) [-8|7.96875] "m/s/s" Vector__XXX
 SG_ CAN_RX_LAT_ACCEL_VALIDITY : 6|1@0+ (1,0) [0|0] "" Vector__XXX
 SG_ CAN_RX_LAT_ACCEL : 5|9@0- (0.03125,0) [-8|7.96875] "" Vector__XXX

BO_ 1470 CAN_TX_VOLVO_KDP_DIAG_PN: 8 ESR

BO_ 1469 CAN_TX_FORD_WERS_DIAG_PN_2: 8 ESR

BO_ 1468 CAN_TX_FORD_WERS_DIAG_PN_1: 8 ESR

BO_ 1464 CAN_TX_VOLVO_KDP_HOST_SW_PN: 8 ESR

BO_ 1463 CAN_TX_FORD_WERS_HOST_SW_PN_2: 8 ESR

BO_ 1462 CAN_TX_FORD_WERS_HOST_SW_PN_1: 8 ESR

BO_ 1461 CAN_TX_VOLVO_KDP_HW_PN: 8 ESR

BO_ 1460 CAN_TX_FORD_WERS_HW_PN_2: 8 ESR

BO_ 1459 CAN_TX_FORD_WERS_HW_PN_1: 8 ESR

BO_ 1458 CAN_TX_VOLVO_KDP_ASM_PN: 8 ESR

BO_ 1457 CAN_TX_FORD_WERS_ASM_PN_2: 8 ESR

BO_ 1456 CAN_TX_FORD_WERS_ASM_PN_1: 8 ESR

BO_ 1511 ESR_Status8: 8 ESR
 SG_ CAN_TX_HISTORY_FAULT_7 : 63|8@0+ (1,0) [0|0] "" Vector__XXX
 SG_ CAN_TX_HISTORY_FAULT_6 : 55|8@0+ (1,0) [0|0] "" Vector__XXX
 SG_ CAN_TX_HISTORY_FAULT_5 : 47|8@0+ (1,0) [0|0] "" Vector__XXX
 SG_ CAN_TX_HISTORY_FAULT_4 : 39|8@0+ (1,0) [0|0] "" Vector__XXX
 SG_ CAN_TX_HISTORY_FAULT_3 : 31|8@0+ (1,0) [0|0] "" Vector__XXX
 SG_ CAN_TX_HISTORY_FAULT_2 : 23|8@0+ (1,0) [0|0] "" Vector__XXX
 SG_ CAN_TX_HISTORY_FAULT_1 : 15|8@0+ (1,0) [0|0] "" Vector__XXX
 SG_ CAN_TX_HISTORY_FAULT_0 : 7|8@0+ (1,0) [0|0] "" Vector__XXX

BO_ 1510 ESR_Status7: 8 ESR
 SG_ CAN_TX_ACTIVE_FAULT_7 : 63|8@0+ (1,0) [0|0] "" Vector__XXX
 SG_ CAN_TX_ACTIVE_FAULT_6 : 55|8@0+ (1,0) [0|0] "" Vector__XXX
 SG_ CAN_TX_ACTIVE_FAULT_5 : 47|8@0+ (1,0) [0|0] "" Vector__XXX
 SG_ CAN_TX_ACTIVE_FAULT_4 : 39|8@0+ (1,0) [0|0] "" Vector__XXX
 SG_ CAN_TX_ACTIVE_FAULT_3 : 31|8@0+ (1,0) [0|0] "" Vector__XXX
 SG_ CAN_TX_ACTIVE_FAULT_2 : 23|8@0+ (1,0) [0|0] "" Vector__XXX
 SG_ CAN_TX_ACTIVE_FAULT_0 : 7|8@0+ (1,0) [0|0] "" Vector__XXX
 SG_ CAN_TX_ACTIVE_FAULT_1 : 15|8@0+ (1,0) [0|0] "" Vector__XXX

BO_ 1509 ESR_Status6: 8 ESR
 SG_ CAN_TX_SW_VERSION_DSP_3RD_BYTE : 31|4@0+ (1,0) [0|0] "" Vector__XXX
 SG_ CAN_TX_VERTICAL_ALIGN_UPDATED : 27|1@0+ (1,0) [0|0] "" Vector__XXX
 SG_ CAN_TX_VERTICAL_MISALIGNMENT : 63|8@0- (0.0625,0) [-6|6] "" Vector__XXX
 SG_ CAN_TX_SERV_ALIGN_UPDATES_DONE : 55|8@0+ (1,0) [0|255] "" Vector__XXX
 SG_ CAN_TX_FOUND_TARGET : 39|1@0+ (1,0) [0|0] "" Vector__XXX
 SG_ CAN_TX_FACTORY_MISALIGNMENT : 47|8@0- (0.0625,0) [-5|5] "deg" Vector__XXX
 SG_ CAN_TX_FACTORY_ALIGN_STATUS_2 : 34|3@0+ (1,0) [0|5] "" Vector__XXX
 SG_ CAN_TX_FACTORY_ALIGN_STATUS_1 : 37|3@0+ (1,0) [0|5] "" Vector__XXX
 SG_ CAN_TX_RECOMMEND_UNCONVERGE : 38|1@0+ (1,0) [0|0] "" Vector__XXX
 SG_ CAN_TX_WAVE_DIFF_A2D : 23|8@0+ (1,0) [0|0] "" Vector__XXX
 SG_ CAN_TX_SYSTEM_POWER_MODE : 26|3@0+ (1,0) [0|0] "" Vector__XXX
 SG_ CAN_TX_SUPPLY_N5V_A2D : 15|8@0+ (1,0) [0|0] "" Vector__XXX
 SG_ CAN_TX_SUPPLY_1P8V_A2D : 7|8@0+ (1,0) [0|0] "" Vector__XXX

BO_ 1508 ESR_Status5: 8 ESR
 SG_ CAN_TX_SUPPLY_10V_A2D : 63|8@0+ (1,0) [0|0] "" Vector__XXX
 SG_ CAN_TX_TEMP2_A2D : 31|8@0+ (1,0) [0|0] "" Vector__XXX
 SG_ CAN_TX_TEMP1_A2D : 23|8@0+ (1,0) [0|0] "" Vector__XXX
 SG_ CAN_TX_SWBATT_A2D : 7|8@0+ (1,0) [0|0] "" Vector__XXX
 SG_ CAN_TX_SUPPLY_5VDX_A2D : 47|8@0+ (1,0) [0|0] "" Vector__XXX
 SG_ CAN_TX_SUPPLY_5VA_A2D : 39|8@0+ (1,0) [0|0] "" Vector__XXX
 SG_ CAN_TX_SUPPLY_3P3V_A2D : 55|8@0+ (1,0) [0|0] "" Vector__XXX
 SG_ CAN_TX_IGNP_A2D : 15|8@0+ (1,0) [0|0] "" Vector__XXX

BO_ 1344 ESR_TrackMotionPower: 8 ESR
 SG_ CAN_TX_TRACK_MOVABLE_SLOW64 m9 : 14|1@0+ (1,0) [0|1] "" Vector__XXX
 SG_ CAN_TX_TRACK_POWER64 m9 : 12|5@0+ (1,-10) [-10|21] "dB" Vector__XXX
 SG_ CAN_TX_TRACK_MOVING64 m9 : 13|1@0+ (1,0) [0|1] "" Vector__XXX
 SG_ CAN_TX_TRACK_MOVABLE_FAST64 m9 : 15|1@0+ (1,0) [0|1] "" Vector__XXX
 SG_ CAN_TX_TRACK_MOVABLE_SLOW63 m8 : 62|1@0+ (1,0) [0|1] "" Vector__XXX
 SG_ CAN_TX_TRACK_MOVABLE_SLOW62 m8 : 54|1@0+ (1,0) [0|1] "" Vector__XXX
 SG_ CAN_TX_TRACK_MOVABLE_SLOW61 m8 : 46|1@0+ (1,0) [0|1] "" Vector__XXX
 SG_ CAN_TX_TRACK_MOVABLE_SLOW60 m8 : 38|1@0+ (1,0) [0|1] "" Vector__XXX
 SG_ CAN_TX_TRACK_MOVABLE_SLOW59 m8 : 30|1@0+ (1,0) [0|1] "" Vector__XXX
 SG_ CAN_TX_TRACK_MOVABLE_SLOW58 m8 : 22|1@0+ (1,0) [0|1] "" Vector__XXX
 SG_ CAN_TX_TRACK_MOVABLE_SLOW57 m8 : 14|1@0+ (1,0) [0|1] "" Vector__XXX
 SG_ CAN_TX_TRACK_POWER63 m8 : 60|5@0+ (1,-10) [-10|21] "dB" Vector__XXX
 SG_ CAN_TX_TRACK_POWER62 m8 : 52|5@0+ (1,-10) [-10|21] "dB" Vector__XXX
 SG_ CAN_TX_TRACK_POWER61 m8 : 44|5@0+ (1,-10) [-10|21] "dB" Vector__XXX
 SG_ CAN_TX_TRACK_POWER60 m8 : 36|5@0+ (1,-10) [-10|21] "dB" Vector__XXX
 SG_ CAN_TX_TRACK_POWER59 m8 : 28|5@0+ (1,-10) [-10|21] "dB" Vector__XXX
 SG_ CAN_TX_TRACK_POWER58 m8 : 20|5@0+ (1,-10) [-10|21] "dB" Vector__XXX
 SG_ CAN_TX_TRACK_POWER57 m8 : 12|5@0+ (1,-10) [-10|21] "dB" Vector__XXX
 SG_ CAN_TX_TRACK_MOVING63 m8 : 61|1@0+ (1,0) [0|1] "" Vector__XXX
 SG_ CAN_TX_TRACK_MOVING62 m8 : 53|1@0+ (1,0) [0|1] "" Vector__XXX
 SG_ CAN_TX_TRACK_MOVING61 m8 : 45|1@0+ (1,0) [0|1] "" Vector__XXX
 SG_ CAN_TX_TRACK_MOVING60 m8 : 37|1@0+ (1,0) [0|1] "" Vector__XXX
 SG_ CAN_TX_TRACK_MOVING59 m8 : 29|1@0+ (1,0) [0|1] "" Vector__XXX
 SG_ CAN_TX_TRACK_MOVING58 m8 : 21|1@0+ (1,0) [0|1] "" Vector__XXX
 SG_ CAN_TX_TRACK_MOVING57 m8 : 13|1@0+ (1,0) [0|1] "" Vector__XXX
 SG_ CAN_TX_TRACK_MOVABLE_FAST63 m8 : 63|1@0+ (1,0) [0|1] "" Vector__XXX
 SG_ CAN_TX_TRACK_MOVABLE_FAST62 m8 : 55|1@0+ (1,0) [0|1] "" Vector__XXX
 SG_ CAN_TX_TRACK_MOVABLE_FAST61 m8 : 47|1@0+ (1,0) [0|1] "" Vector__XXX
 SG_ CAN_TX_TRACK_MOVABLE_FAST60 m8 : 39|1@0+ (1,0) [0|1] "" Vector__XXX
 SG_ CAN_TX_TRACK_MOVABLE_FAST59 m8 : 31|1@0+ (1,0) [0|1] "" Vector__XXX
 SG_ CAN_TX_TRACK_MOVABLE_FAST58 m8 : 23|1@0+ (1,0) [0|1] "" Vector__XXX
 SG_ CAN_TX_TRACK_MOVABLE_FAST57 m8 : 15|1@0+ (1,0) [0|1] "" Vector__XXX
 SG_ CAN_TX_TRACK_MOVABLE_SLOW56 m7 : 62|1@0+ (1,0) [0|1] "" Vector__XXX
 SG_ CAN_TX_TRACK_MOVABLE_SLOW55 m7 : 54|1@0+ (1,0) [0|1] "" Vector__XXX
 SG_ CAN_TX_TRACK_MOVABLE_SLOW54 m7 : 46|1@0+ (1,0) [0|1] "" Vector__XXX
 SG_ CAN_TX_TRACK_MOVABLE_SLOW53 m7 : 38|1@0+ (1,0) [0|1] "" Vector__XXX
 SG_ CAN_TX_TRACK_MOVABLE_SLOW52 m7 : 30|1@0+ (1,0) [0|1] "" Vector__XXX
 SG_ CAN_TX_TRACK_MOVABLE_SLOW51 m7 : 22|1@0+ (1,0) [0|1] "" Vector__XXX
 SG_ CAN_TX_TRACK_MOVABLE_SLOW50 m7 : 14|1@0+ (1,0) [0|1] "" Vector__XXX
 SG_ CAN_TX_TRACK_POWER56 m7 : 60|5@0+ (1,-10) [-10|21] "dB" Vector__XXX
 SG_ CAN_TX_TRACK_POWER55 m7 : 52|5@0+ (1,-10) [-10|21] "dB" Vector__XXX
 SG_ CAN_TX_TRACK_POWER54 m7 : 44|5@0+ (1,-10) [-10|21] "dB" Vector__XXX
 SG_ CAN_TX_TRACK_POWER53 m7 : 36|5@0+ (1,-10) [-10|21] "dB" Vector__XXX
 SG_ CAN_TX_TRACK_POWER52 m7 : 28|5@0+ (1,-10) [-10|21] "dB" Vector__XXX
 SG_ CAN_TX_TRACK_POWER51 m7 : 20|5@0+ (1,-10) [-10|21] "dB" Vector__XXX
 SG_ CAN_TX_TRACK_POWER50 m7 : 12|5@0+ (1,-10) [-10|21] "dB" Vector__XXX
 SG_ CAN_TX_TRACK_MOVING56 m7 : 61|1@0+ (1,0) [0|1] "" Vector__XXX
 SG_ CAN_TX_TRACK_MOVING55 m7 : 53|1@0+ (1,0) [0|1] "" Vector__XXX
 SG_ CAN_TX_TRACK_MOVING54 m7 : 45|1@0+ (1,0) [0|1] "" Vector__XXX
 SG_ CAN_TX_TRACK_MOVING53 m7 : 37|1@0+ (1,0) [0|1] "" Vector__XXX
 SG_ CAN_TX_TRACK_MOVING52 m7 : 29|1@0+ (1,0) [0|1] "" Vector__XXX
 SG_ CAN_TX_TRACK_MOVING51 m7 : 21|1@0+ (1,0) [0|1] "" Vector__XXX
 SG_ CAN_TX_TRACK_MOVING50 m7 : 13|1@0+ (1,0) [0|1] "" Vector__XXX
 SG_ CAN_TX_TRACK_MOVABLE_FAST56 m7 : 63|1@0+ (1,0) [0|1] "" Vector__XXX
 SG_ CAN_TX_TRACK_MOVABLE_FAST55 m7 : 55|1@0+ (1,0) [0|1] "" Vector__XXX
 SG_ CAN_TX_TRACK_MOVABLE_FAST54 m7 : 47|1@0+ (1,0) [0|1] "" Vector__XXX
 SG_ CAN_TX_TRACK_MOVABLE_FAST53 m7 : 39|1@0+ (1,0) [0|1] "" Vector__XXX
 SG_ CAN_TX_TRACK_MOVABLE_FAST52 m7 : 31|1@0+ (1,0) [0|1] "" Vector__XXX
 SG_ CAN_TX_TRACK_MOVABLE_FAST51 m7 : 23|1@0+ (1,0) [0|1] "" Vector__XXX
 SG_ CAN_TX_TRACK_MOVABLE_FAST50 m7 : 15|1@0+ (1,0) [0|1] "" Vector__XXX
 SG_ CAN_TX_TRACK_MOVABLE_SLOW49 m6 : 62|1@0+ (1,0) [0|1] "" Vector__XXX
 SG_ CAN_TX_TRACK_MOVABLE_SLOW48 m6 : 54|1@0+ (1,0) [0|1] "" Vector__XXX
 SG_ CAN_TX_TRACK_MOVABLE_SLOW47 m6 : 46|1@0+ (1,0) [0|1] "" Vector__XXX
 SG_ CAN_TX_TRACK_MOVABLE_SLOW46 m6 : 38|1@0+ (1,0) [0|1] "" Vector__XXX
 SG_ CAN_TX_TRACK_MOVABLE_SLOW45 m6 : 30|1@0+ (1,0) [0|1] "" Vector__XXX
 SG_ CAN_TX_TRACK_MOVABLE_SLOW44 m6 : 22|1@0+ (1,0) [0|1] "" Vector__XXX
 SG_ CAN_TX_TRACK_MOVABLE_SLOW43 m6 : 14|1@0+ (1,0) [0|1] "" Vector__XXX
 SG_ CAN_TX_TRACK_POWER49 m6 : 60|5@0+ (1,-10) [-10|21] "dB" Vector__XXX
 SG_ CAN_TX_TRACK_POWER48 m6 : 52|5@0+ (1,-10) [-10|21] "dB" Vector__XXX
 SG_ CAN_TX_TRACK_POWER47 m6 : 44|5@0+ (1,-10) [-10|21] "dB" Vector__XXX
 SG_ CAN_TX_TRACK_POWER46 m6 : 36|5@0+ (1,-10) [-10|21] "dB" Vector__XXX
 SG_ CAN_TX_TRACK_POWER45 m6 : 28|5@0+ (1,-10) [-10|21] "dB" Vector__XXX
 SG_ CAN_TX_TRACK_POWER44 m6 : 20|5@0+ (1,-10) [-10|21] "dB" Vector__XXX
 SG_ CAN_TX_TRACK_POWER43 m6 : 12|5@0+ (1,-10) [-10|21] "dB" Vector__XXX
 SG_ CAN_TX_TRACK_MOVING49 m6 : 61|1@0+ (1,0) [0|1] "" Vector__XXX
 SG_ CAN_TX_TRACK_MOVING48 m6 : 53|1@0+ (1,0) [0|1] "" Vector__XXX
 SG_ CAN_TX_TRACK_MOVING47 m6 : 45|1@0+ (1,0) [0|1] "" Vector__XXX
 SG_ CAN_TX_TRACK_MOVING46 m6 : 37|1@0+ (1,0) [0|1] "" Vector__XXX
 SG_ CAN_TX_TRACK_MOVING45 m6 : 29|1@0+ (1,0) [0|1] "" Vector__XXX
 SG_ CAN_TX_TRACK_MOVING44 m6 : 21|1@0+ (1,0) [0|1] "" Vector__XXX
 SG_ CAN_TX_TRACK_MOVING43 m6 : 13|1@0+ (1,0) [0|1] "" Vector__XXX
 SG_ CAN_TX_TRACK_MOVABLE_FAST49 m6 : 63|1@0+ (1,0) [0|1] "" Vector__XXX
 SG_ CAN_TX_TRACK_MOVABLE_FAST48 m6 : 55|1@0+ (1,0) [0|1] "" Vector__XXX
 SG_ CAN_TX_TRACK_MOVABLE_FAST47 m6 : 47|1@0+ (1,0) [0|1] "" Vector__XXX
 SG_ CAN_TX_TRACK_MOVABLE_FAST46 m6 : 39|1@0+ (1,0) [0|1] "" Vector__XXX
 SG_ CAN_TX_TRACK_MOVABLE_FAST45 m6 : 31|1@0+ (1,0) [0|1] "" Vector__XXX
 SG_ CAN_TX_TRACK_MOVABLE_FAST44 m6 : 23|1@0+ (1,0) [0|1] "" Vector__XXX
 SG_ CAN_TX_TRACK_MOVABLE_FAST43 m6 : 15|1@0+ (1,0) [0|1] "" Vector__XXX
 SG_ CAN_TX_TRACK_MOVABLE_SLOW42 m5 : 62|1@0+ (1,0) [0|1] "" Vector__XXX
 SG_ CAN_TX_TRACK_MOVABLE_SLOW41 m5 : 54|1@0+ (1,0) [0|1] "" Vector__XXX
 SG_ CAN_TX_TRACK_MOVABLE_SLOW40 m5 : 46|1@0+ (1,0) [0|1] "" Vector__XXX
 SG_ CAN_TX_TRACK_MOVABLE_SLOW39 m5 : 38|1@0+ (1,0) [0|1] "" Vector__XXX
 SG_ CAN_TX_TRACK_MOVABLE_SLOW38 m5 : 30|1@0+ (1,0) [0|1] "" Vector__XXX
 SG_ CAN_TX_TRACK_MOVABLE_SLOW37 m5 : 22|1@0+ (1,0) [0|1] "" Vector__XXX
 SG_ CAN_TX_TRACK_MOVABLE_SLOW36 m5 : 14|1@0+ (1,0) [0|1] "" Vector__XXX
 SG_ CAN_TX_TRACK_POWER42 m5 : 60|5@0+ (1,-10) [-10|21] "dB" Vector__XXX
 SG_ CAN_TX_TRACK_POWER41 m5 : 52|5@0+ (1,-10) [-10|21] "dB" Vector__XXX
 SG_ CAN_TX_TRACK_POWER40 m5 : 44|5@0+ (1,-10) [-10|21] "dB" Vector__XXX
 SG_ CAN_TX_TRACK_POWER39 m5 : 36|5@0+ (1,-10) [-10|21] "dB" Vector__XXX
 SG_ CAN_TX_TRACK_POWER38 m5 : 28|5@0+ (1,-10) [-10|21] "dB" Vector__XXX
 SG_ CAN_TX_TRACK_POWER37 m5 : 20|5@0+ (1,-10) [-10|21] "dB" Vector__XXX
 SG_ CAN_TX_TRACK_POWER36 m5 : 12|5@0+ (1,-10) [-10|21] "dB" Vector__XXX
 SG_ CAN_TX_TRACK_MOVING42 m5 : 61|1@0+ (1,0) [0|1] "" Vector__XXX
 SG_ CAN_TX_TRACK_MOVING41 m5 : 53|1@0+ (1,0) [0|1] "" Vector__XXX
 SG_ CAN_TX_TRACK_MOVING40 m5 : 45|1@0+ (1,0) [0|1] "" Vector__XXX
 SG_ CAN_TX_TRACK_MOVING39 m5 : 37|1@0+ (1,0) [0|1] "" Vector__XXX
 SG_ CAN_TX_TRACK_MOVING38 m5 : 29|1@0+ (1,0) [0|1] "" Vector__XXX
 SG_ CAN_TX_TRACK_MOVING37 m5 : 21|1@0+ (1,0) [0|1] "" Vector__XXX
 SG_ CAN_TX_TRACK_MOVING36 m5 : 13|1@0+ (1,0) [0|1] "" Vector__XXX
 SG_ CAN_TX_TRACK_MOVABLE_FAST42 m5 : 63|1@0+ (1,0) [0|1] "" Vector__XXX
 SG_ CAN_TX_TRACK_MOVABLE_FAST41 m5 : 55|1@0+ (1,0) [0|1] "" Vector__XXX
 SG_ CAN_TX_TRACK_MOVABLE_FAST40 m5 : 47|1@0+ (1,0) [0|1] "" Vector__XXX
 SG_ CAN_TX_TRACK_MOVABLE_FAST39 m5 : 39|1@0+ (1,0) [0|1] "" Vector__XXX
 SG_ CAN_TX_TRACK_MOVABLE_FAST38 m5 : 31|1@0+ (1,0) [0|1] "" Vector__XXX
 SG_ CAN_TX_TRACK_MOVABLE_FAST37 m5 : 23|1@0+ (1,0) [0|1] "" Vector__XXX
 SG_ CAN_TX_TRACK_MOVABLE_FAST36 m5 : 15|1@0+ (1,0) [0|1] "" Vector__XXX
 SG_ CAN_TX_TRACK_MOVABLE_SLOW35 m4 : 62|1@0+ (1,0) [0|1] "" Vector__XXX
 SG_ CAN_TX_TRACK_MOVABLE_SLOW34 m4 : 54|1@0+ (1,0) [0|1] "" Vector__XXX
 SG_ CAN_TX_TRACK_MOVABLE_SLOW33 m4 : 46|1@0+ (1,0) [0|1] "" Vector__XXX
 SG_ CAN_TX_TRACK_MOVABLE_SLOW32 m4 : 38|1@0+ (1,0) [0|1] "" Vector__XXX
 SG_ CAN_TX_TRACK_MOVABLE_SLOW31 m4 : 30|1@0+ (1,0) [0|1] "" Vector__XXX
 SG_ CAN_TX_TRACK_MOVABLE_SLOW30 m4 : 22|1@0+ (1,0) [0|1] "" Vector__XXX
 SG_ CAN_TX_TRACK_MOVABLE_SLOW29 m4 : 14|1@0+ (1,0) [0|1] "" Vector__XXX
 SG_ CAN_TX_TRACK_POWER35 m4 : 60|5@0+ (1,-10) [-10|21] "dB" Vector__XXX
 SG_ CAN_TX_TRACK_POWER34 m4 : 52|5@0+ (1,-10) [-10|21] "dB" Vector__XXX
 SG_ CAN_TX_TRACK_POWER33 m4 : 44|5@0+ (1,-10) [-10|21] "dB" Vector__XXX
 SG_ CAN_TX_TRACK_POWER32 m4 : 36|5@0+ (1,-10) [-10|21] "dB" Vector__XXX
 SG_ CAN_TX_TRACK_POWER31 m4 : 28|5@0+ (1,-10) [-10|21] "dB" Vector__XXX
 SG_ CAN_TX_TRACK_POWER30 m4 : 20|5@0+ (1,-10) [-10|21] "dB" Vector__XXX
 SG_ CAN_TX_TRACK_POWER29 m4 : 12|5@0+ (1,-10) [-10|21] "dB" Vector__XXX
 SG_ CAN_TX_TRACK_MOVING35 m4 : 61|1@0+ (1,0) [0|1] "" Vector__XXX
 SG_ CAN_TX_TRACK_MOVING34 m4 : 53|1@0+ (1,0) [0|1] "" Vector__XXX
 SG_ CAN_TX_TRACK_MOVING33 m4 : 45|1@0+ (1,0) [0|1] "" Vector__XXX
 SG_ CAN_TX_TRACK_MOVING32 m4 : 37|1@0+ (1,0) [0|1] "" Vector__XXX
 SG_ CAN_TX_TRACK_MOVING31 m4 : 29|1@0+ (1,0) [0|1] "" Vector__XXX
 SG_ CAN_TX_TRACK_MOVING30 m4 : 21|1@0+ (1,0) [0|1] "" Vector__XXX
 SG_ CAN_TX_TRACK_MOVING29 m4 : 13|1@0+ (1,0) [0|1] "" Vector__XXX
 SG_ CAN_TX_TRACK_MOVABLE_FAST35 m4 : 63|1@0+ (1,0) [0|1] "" Vector__XXX
 SG_ CAN_TX_TRACK_MOVABLE_FAST34 m4 : 55|1@0+ (1,0) [0|1] "" Vector__XXX
 SG_ CAN_TX_TRACK_MOVABLE_FAST33 m4 : 47|1@0+ (1,0) [0|1] "" Vector__XXX
 SG_ CAN_TX_TRACK_MOVABLE_FAST32 m4 : 39|1@0+ (1,0) [0|1] "" Vector__XXX
 SG_ CAN_TX_TRACK_MOVABLE_FAST31 m4 : 31|1@0+ (1,0) [0|1] "" Vector__XXX
 SG_ CAN_TX_TRACK_MOVABLE_FAST30 m4 : 23|1@0+ (1,0) [0|1] "" Vector__XXX
 SG_ CAN_TX_TRACK_MOVABLE_FAST29 m4 : 15|1@0+ (1,0) [0|1] "" Vector__XXX
 SG_ CAN_TX_TRACK_MOVABLE_SLOW28 m3 : 62|1@0+ (1,0) [0|1] "" Vector__XXX
 SG_ CAN_TX_TRACK_MOVABLE_SLOW27 m3 : 54|1@0+ (1,0) [0|1] "" Vector__XXX
 SG_ CAN_TX_TRACK_MOVABLE_SLOW26 m3 : 46|1@0+ (1,0) [0|1] "" Vector__XXX
 SG_ CAN_TX_TRACK_MOVABLE_SLOW25 m3 : 38|1@0+ (1,0) [0|1] "" Vector__XXX
 SG_ CAN_TX_TRACK_MOVABLE_SLOW24 m3 : 30|1@0+ (1,0) [0|1] "" Vector__XXX
 SG_ CAN_TX_TRACK_MOVABLE_SLOW23 m3 : 22|1@0+ (1,0) [0|1] "" Vector__XXX
 SG_ CAN_TX_TRACK_MOVABLE_SLOW22 m3 : 14|1@0+ (1,0) [0|1] "" Vector__XXX
 SG_ CAN_TX_TRACK_POWER28 m3 : 60|5@0+ (1,-10) [-10|21] "dB" Vector__XXX
 SG_ CAN_TX_TRACK_POWER27 m3 : 52|5@0+ (1,-10) [-10|21] "dB" Vector__XXX
 SG_ CAN_TX_TRACK_POWER26 m3 : 44|5@0+ (1,-10) [-10|21] "dB" Vector__XXX
 SG_ CAN_TX_TRACK_POWER25 m3 : 36|5@0+ (1,-10) [-10|21] "dB" Vector__XXX
 SG_ CAN_TX_TRACK_POWER24 m3 : 28|5@0+ (1,-10) [-10|21] "dB" Vector__XXX
 SG_ CAN_TX_TRACK_POWER23 m3 : 20|5@0+ (1,-10) [-10|21] "dB" Vector__XXX
 SG_ CAN_TX_TRACK_POWER22 m3 : 12|5@0+ (1,-10) [-10|21] "dB" Vector__XXX
 SG_ CAN_TX_TRACK_MOVING28 m3 : 61|1@0+ (1,0) [0|1] "" Vector__XXX
 SG_ CAN_TX_TRACK_MOVING27 m3 : 53|1@0+ (1,0) [0|1] "" Vector__XXX
 SG_ CAN_TX_TRACK_MOVING26 m3 : 45|1@0+ (1,0) [0|1] "" Vector__XXX
 SG_ CAN_TX_TRACK_MOVING25 m3 : 37|1@0+ (1,0) [0|1] "" Vector__XXX
 SG_ CAN_TX_TRACK_MOVING24 m3 : 29|1@0+ (1,0) [0|1] "" Vector__XXX
 SG_ CAN_TX_TRACK_MOVING23 m3 : 21|1@0+ (1,0) [0|1] "" Vector__XXX
 SG_ CAN_TX_TRACK_MOVING22 m3 : 13|1@0+ (1,0) [0|1] "" Vector__XXX
 SG_ CAN_TX_TRACK_MOVABLE_FAST28 m3 : 63|1@0+ (1,0) [0|1] "" Vector__XXX
 SG_ CAN_TX_TRACK_MOVABLE_FAST27 m3 : 55|1@0+ (1,0) [0|1] "" Vector__XXX
 SG_ CAN_TX_TRACK_MOVABLE_FAST26 m3 : 47|1@0+ (1,0) [0|1] "" Vector__XXX
 SG_ CAN_TX_TRACK_MOVABLE_FAST25 m3 : 39|1@0+ (1,0) [0|1] "" Vector__XXX
 SG_ CAN_TX_TRACK_MOVABLE_FAST24 m3 : 31|1@0+ (1,0) [0|1] "" Vector__XXX
 SG_ CAN_TX_TRACK_MOVABLE_FAST23 m3 : 23|1@0+ (1,0) [0|1] "" Vector__XXX
 SG_ CAN_TX_TRACK_MOVABLE_FAST22 m3 : 15|1@0+ (1,0) [0|1] "" Vector__XXX
 SG_ CAN_TX_TRACK_MOVABLE_SLOW21 m2 : 62|1@0+ (1,0) [0|1] "" Vector__XXX
 SG_ CAN_TX_TRACK_MOVABLE_SLOW20 m2 : 54|1@0+ (1,0) [0|1] "" Vector__XXX
 SG_ CAN_TX_TRACK_MOVABLE_SLOW19 m2 : 46|1@0+ (1,0) [0|1] "" Vector__XXX
 SG_ CAN_TX_TRACK_MOVABLE_SLOW18 m2 : 38|1@0+ (1,0) [0|1] "" Vector__XXX
 SG_ CAN_TX_TRACK_MOVABLE_SLOW17 m2 : 30|1@0+ (1,0) [0|1] "" Vector__XXX
 SG_ CAN_TX_TRACK_MOVABLE_SLOW16 m2 : 22|1@0+ (1,0) [0|1] "" Vector__XXX
 SG_ CAN_TX_TRACK_MOVABLE_SLOW15 m2 : 14|1@0+ (1,0) [0|1] "" Vector__XXX
 SG_ CAN_TX_TRACK_POWER21 m2 : 60|5@0+ (1,-10) [-10|21] "dB" Vector__XXX
 SG_ CAN_TX_TRACK_POWER20 m2 : 52|5@0+ (1,-10) [-10|21] "dB" Vector__XXX
 SG_ CAN_TX_TRACK_POWER19 m2 : 44|5@0+ (1,-10) [-10|21] "dB" Vector__XXX
 SG_ CAN_TX_TRACK_POWER18 m2 : 36|5@0+ (1,-10) [-10|21] "dB" Vector__XXX
 SG_ CAN_TX_TRACK_POWER17 m2 : 28|5@0+ (1,-10) [-10|21] "dB" Vector__XXX
 SG_ CAN_TX_TRACK_POWER16 m2 : 20|5@0+ (1,-10) [-10|21] "dB" Vector__XXX
 SG_ CAN_TX_TRACK_POWER15 m2 : 12|5@0+ (1,-10) [-10|21] "dB" Vector__XXX
 SG_ CAN_TX_TRACK_MOVING21 m2 : 61|1@0+ (1,0) [0|1] "" Vector__XXX
 SG_ CAN_TX_TRACK_MOVING20 m2 : 53|1@0+ (1,0) [0|1] "" Vector__XXX
 SG_ CAN_TX_TRACK_MOVING19 m2 : 45|1@0+ (1,0) [0|1] "" Vector__XXX
 SG_ CAN_TX_TRACK_MOVING18 m2 : 37|1@0+ (1,0) [0|1] "" Vector__XXX
 SG_ CAN_TX_TRACK_MOVING17 m2 : 29|1@0+ (1,0) [0|1] "" Vector__XXX
 SG_ CAN_TX_TRACK_MOVING16 m2 : 21|1@0+ (1,0) [0|1] "" Vector__XXX
 SG_ CAN_TX_TRACK_MOVING15 m2 : 13|1@0+ (1,0) [0|1] "" Vector__XXX
 SG_ CAN_TX_TRACK_MOVABLE_FAST21 m2 : 63|1@0+ (1,0) [0|1] "" Vector__XXX
 SG_ CAN_TX_TRACK_MOVABLE_FAST20 m2 : 55|1@0+ (1,0) [0|1] "" Vector__XXX
 SG_ CAN_TX_TRACK_MOVABLE_FAST19 m2 : 47|1@0+ (1,0) [0|1] "" Vector__XXX
 SG_ CAN_TX_TRACK_MOVABLE_FAST18 m2 : 39|1@0+ (1,0) [0|1] "" Vector__XXX
 SG_ CAN_TX_TRACK_MOVABLE_FAST17 m2 : 31|1@0+ (1,0) [0|1] "" Vector__XXX
 SG_ CAN_TX_TRACK_MOVABLE_FAST16 m2 : 23|1@0+ (1,0) [0|1] "" Vector__XXX
 SG_ CAN_TX_TRACK_MOVABLE_FAST15 m2 : 15|1@0+ (1,0) [0|1] "" Vector__XXX
 SG_ CAN_TX_TRACK_MOVABLE_SLOW14 m1 : 62|1@0+ (1,0) [0|1] "" Vector__XXX
 SG_ CAN_TX_TRACK_MOVABLE_SLOW13 m1 : 54|1@0+ (1,0) [0|1] "" Vector__XXX
 SG_ CAN_TX_TRACK_MOVABLE_SLOW12 m1 : 46|1@0+ (1,0) [0|1] "" Vector__XXX
 SG_ CAN_TX_TRACK_MOVABLE_SLOW11 m1 : 38|1@0+ (1,0) [0|1] "" Vector__XXX
 SG_ CAN_TX_TRACK_MOVABLE_SLOW10 m1 : 30|1@0+ (1,0) [0|1] "" Vector__XXX
 SG_ CAN_TX_TRACK_MOVABLE_SLOW09 m1 : 22|1@0+ (1,0) [0|1] "" Vector__XXX
 SG_ CAN_TX_TRACK_MOVABLE_SLOW08 m1 : 14|1@0+ (1,0) [0|1] "" Vector__XXX
 SG_ CAN_TX_TRACK_POWER14 m1 : 60|5@0+ (1,-10) [-10|21] "dB" Vector__XXX
 SG_ CAN_TX_TRACK_POWER13 m1 : 52|5@0+ (1,-10) [-10|21] "dB" Vector__XXX
 SG_ CAN_TX_TRACK_POWER12 m1 : 44|5@0+ (1,-10) [-10|21] "dB" Vector__XXX
 SG_ CAN_TX_TRACK_POWER11 m1 : 36|5@0+ (1,-10) [-10|21] "dB" Vector__XXX
 SG_ CAN_TX_TRACK_POWER10 m1 : 28|5@0+ (1,-10) [-10|21] "dB" Vector__XXX
 SG_ CAN_TX_TRACK_POWER09 m1 : 20|5@0+ (1,-10) [-10|21] "dB" Vector__XXX
 SG_ CAN_TX_TRACK_POWER08 m1 : 12|5@0+ (1,-10) [-10|21] "dB" Vector__XXX
 SG_ CAN_TX_TRACK_MOVING14 m1 : 61|1@0+ (1,0) [0|1] "" Vector__XXX
 SG_ CAN_TX_TRACK_MOVING13 m1 : 53|1@0+ (1,0) [0|1] "" Vector__XXX
 SG_ CAN_TX_TRACK_MOVING12 m1 : 45|1@0+ (1,0) [0|1] "" Vector__XXX
 SG_ CAN_TX_TRACK_MOVING11 m1 : 37|1@0+ (1,0) [0|1] "" Vector__XXX
 SG_ CAN_TX_TRACK_MOVING10 m1 : 29|1@0+ (1,0) [0|1] "" Vector__XXX
 SG_ CAN_TX_TRACK_MOVING09 m1 : 21|1@0+ (1,0) [0|1] "" Vector__XXX
 SG_ CAN_TX_TRACK_MOVING08 m1 : 13|1@0+ (1,0) [0|1] "" Vector__XXX
 SG_ CAN_TX_TRACK_MOVABLE_FAST14 m1 : 63|1@0+ (1,0) [0|1] "" Vector__XXX
 SG_ CAN_TX_TRACK_MOVABLE_FAST13 m1 : 55|1@0+ (1,0) [0|1] "" Vector__XXX
 SG_ CAN_TX_TRACK_MOVABLE_FAST12 m1 : 47|1@0+ (1,0) [0|1] "" Vector__XXX
 SG_ CAN_TX_TRACK_MOVABLE_FAST11 m1 : 39|1@0+ (1,0) [0|1] "" Vector__XXX
 SG_ CAN_TX_TRACK_MOVABLE_FAST10 m1 : 31|1@0+ (1,0) [0|1] "" Vector__XXX
 SG_ CAN_TX_TRACK_MOVABLE_FAST09 m1 : 23|1@0+ (1,0) [0|1] "" Vector__XXX
 SG_ CAN_TX_TRACK_MOVABLE_FAST08 m1 : 15|1@0+ (1,0) [0|1] "" Vector__XXX
 SG_ CAN_TX_TRACK_ROLLING_COUNT_2 : 4|1@0+ (1,0) [0|1] "" Vector__XXX
 SG_ CAN_TX_TRACK_POWER07 m0 : 60|5@0+ (1,-10) [-10|21] "dB" Vector__XXX
 SG_ CAN_TX_TRACK_POWER06 m0 : 52|5@0+ (1,-10) [-10|21] "dB" Vector__XXX
 SG_ CAN_TX_TRACK_POWER05 m0 : 44|5@0+ (1,-10) [-10|21] "dB" Vector__XXX
 SG_ CAN_TX_TRACK_POWER04 m0 : 36|5@0+ (1,-10) [-10|21] "dB" Vector__XXX
 SG_ CAN_TX_TRACK_POWER03 m0 : 28|5@0+ (1,-10) [-10|21] "dB" Vector__XXX
 SG_ CAN_TX_TRACK_POWER02 m0 : 20|5@0+ (1,-10) [-10|21] "dB" Vector__XXX
 SG_ CAN_TX_TRACK_POWER01 m0 : 12|5@0+ (1,-10) [-10|21] "dB" Vector__XXX
 SG_ CAN_TX_TRACK_MOVING07 m0 : 61|1@0+ (1,0) [0|1] "" Vector__XXX
 SG_ CAN_TX_TRACK_MOVING06 m0 : 53|1@0+ (1,0) [0|1] "" Vector__XXX
 SG_ CAN_TX_TRACK_MOVING05 m0 : 45|1@0+ (1,0) [0|1] "" Vector__XXX
 SG_ CAN_TX_TRACK_MOVING04 m0 : 37|1@0+ (1,0) [0|1] "" Vector__XXX
 SG_ CAN_TX_TRACK_MOVING03 m0 : 29|1@0+ (1,0) [0|1] "" Vector__XXX
 SG_ CAN_TX_TRACK_MOVING02 m0 : 21|1@0+ (1,0) [0|1] "" Vector__XXX
 SG_ CAN_TX_TRACK_MOVING01 m0 : 13|1@0+ (1,0) [0|1] "" Vector__XXX
 SG_ CAN_TX_TRACK_MOVABLE_SLOW07 m0 : 62|1@0+ (1,0) [0|1] "" Vector__XXX
 SG_ CAN_TX_TRACK_MOVABLE_SLOW06 m0 : 54|1@0+ (1,0) [0|1] "" Vector__XXX
 SG_ CAN_TX_TRACK_MOVABLE_SLOW05 m0 : 46|1@0+ (1,0) [0|1] "" Vector__XXX
 SG_ CAN_TX_TRACK_MOVABLE_SLOW04 m0 : 38|1@0+ (1,0) [0|1] "" Vector__XXX
 SG_ CAN_TX_TRACK_MOVABLE_SLOW03 m0 : 30|1@0+ (1,0) [0|1] "" Vector__XXX
 SG_ CAN_TX_TRACK_MOVABLE_SLOW02 m0 : 22|1@0+ (1,0) [0|1] "" Vector__XXX
 SG_ CAN_TX_TRACK_MOVABLE_SLOW01 m0 : 14|1@0+ (1,0) [0|1] "" Vector__XXX
 SG_ CAN_TX_TRACK_MOVABLE_FAST07 m0 : 63|1@0+ (1,0) [0|1] "" Vector__XXX
 SG_ CAN_TX_TRACK_MOVABLE_FAST06 m0 : 55|1@0+ (1,0) [0|1] "" Vector__XXX
 SG_ CAN_TX_TRACK_MOVABLE_FAST05 m0 : 47|1@0+ (1,0) [0|1] "" Vector__XXX
 SG_ CAN_TX_TRACK_MOVABLE_FAST04 m0 : 39|1@0+ (1,0) [0|1] "" Vector__XXX
 SG_ CAN_TX_TRACK_MOVABLE_FAST03 m0 : 31|1@0+ (1,0) [0|1] "" Vector__XXX
 SG_ CAN_TX_TRACK_MOVABLE_FAST02 m0 : 23|1@0+ (1,0) [0|1] "" Vector__XXX
 SG_ CAN_TX_TRACK_MOVABLE_FAST01 m0 : 15|1@0+ (1,0) [0|1] "" Vector__XXX
 SG_ CAN_TX_TRACK_CAN_ID_GROUP M : 3|4@0+ (1,0) [0|9] "" Vector__XXX

BO_ 1251 ESR_Status4: 8 ESR
 SG_ CAN_TX_TRUCK_TARGET_DET : 7|1@0+ (1,0) [0|0] "" Vector__XXX
 SG_ CAN_TX_LR_ONLY_GRATING_LOBE_DET : 6|1@0+ (1,0) [0|0] "" Vector__XXX
 SG_ CAN_TX_SIDELOBE_BLOCKAGE : 5|1@0+ (1,0) [0|0] "" Vector__XXX
 SG_ CAN_TX_PARTIAL_BLOCKAGE : 4|1@0+ (1,0) [0|0] "" Vector__XXX
 SG_ CAN_TX_PATH_ID_ACC_STAT : 63|8@0+ (1,0) [0|0] "" Vector__XXX
 SG_ CAN_TX_MR_LR_MODE : 3|2@0+ (1,0) [0|3] "" Vector__XXX
 SG_ CAN_TX_AUTO_ALIGN_ANGLE : 55|8@0- (0.0625,0) [-8|7.9375] "" Vector__XXX
 SG_ CAN_TX_ROLLING_COUNT_3 : 1|2@0+ (1,0) [0|0] "" Vector__XXX
 SG_ CAN_TX_PATH_ID_FCW_STAT : 47|8@0+ (1,0) [0|0] "" Vector__XXX
 SG_ CAN_TX_PATH_ID_FCW_MOVE : 39|8@0+ (1,0) [0|0] "" Vector__XXX
 SG_ CAN_TX_PATH_ID_CMBB_STAT : 31|8@0+ (1,0) [0|0] "" Vector__XXX
 SG_ CAN_TX_PATH_ID_CMBB_MOVE : 23|8@0+ (1,0) [0|0] "" Vector__XXX
 SG_ CAN_TX_PATH_ID_ACC : 15|8@0+ (1,0) [0|0] "" Vector__XXX

BO_ 1489 ESR_Valid2: 8 ESR
 SG_ CAN_TX_VALID_MR_SN : 7|8@0+ (1,0) [0|0] "" Vector__XXX
 SG_ CAN_TX_VALID_MR_RANGE_RATE : 31|16@0- (0.0078125,0) [-128|127] "m/s" Vector__XXX
 SG_ CAN_TX_VALID_MR_RANGE : 15|16@0+ (0.0078125,0) [0|200] "m" Vector__XXX
 SG_ CAN_TX_VALID_MR_POWER : 63|8@0- (1,0) [-10|40] "dB" Vector__XXX
 SG_ CAN_TX_VALID_MR_ANGLE : 47|16@0- (0.0625,0) [-64|63.9375] "deg" Vector__XXX

BO_ 1488 ESR_Valid1: 8 ESR
 SG_ CAN_TX_VALID_LR_SN : 7|8@0+ (1,0) [0|0] "" Vector__XXX
 SG_ CAN_TX_VALID_LR_RANGE_RATE : 31|16@0- (0.0078125,0) [-128|127] "m/s" Vector__XXX
 SG_ CAN_TX_VALID_LR_RANGE : 15|16@0+ (0.0078125,0) [0|200] "m" Vector__XXX
 SG_ CAN_TX_VALID_LR_POWER : 63|8@0- (1,0) [-10|40] "dB" Vector__XXX
 SG_ CAN_TX_VALID_LR_ANGLE : 47|16@0- (0.0625,0) [-64|63.9375] "deg" Vector__XXX

BO_ 2030 MMR_Inst_Resp_FLASH: 8 Vector__XXX

BO_ 2029 MMR_Inst_Req_FLASH: 8 Vector__XXX

BO_ 2028 MMR_Inst_DAQ4: 8 Vector__XXX

BO_ 2027 MMR_Inst_DAQ3: 8 Vector__XXX

BO_ 2026 MMR_Inst_DAQ2: 8 Vector__XXX

BO_ 2025 MMR_Inst_DAQ1: 8 Vector__XXX

BO_ 2024 ACM_Inst_DAQ2: 8 Vector__XXX

BO_ 2019 MMR_Host_Inst_Resp: 8 Vector__XXX

BO_ 2017 MMR_Host_Inst_Req: 8 Vector__XXX

BO_ 2022 MMR_DSP_Inst_Resp: 8 Vector__XXX

BO_ 2021 MMR_DSP_Inst_Req: 8 Vector__XXX

BO_ 2020 ACM_Inst_Resp: 8 Vector__XXX
 SG_ Data_7 : 63|8@0+ (1,0) [0|0] "" Vector__XXX
 SG_ Data_6 : 55|8@0+ (1,0) [0|0] "" Vector__XXX
 SG_ Data_5 : 47|8@0+ (1,0) [0|0] "" Vector__XXX
 SG_ Data_4 : 39|8@0+ (1,0) [0|0] "" Vector__XXX
 SG_ Data_3 : 31|8@0+ (1,0) [0|0] "" Vector__XXX
 SG_ rtn_cmd_counter : 23|8@0+ (1,0) [0|0] "" Vector__XXX
 SG_ command_return_code : 15|8@0+ (1,0) [0|0] "" Vector__XXX
 SG_ PID : 7|8@0+ (1,0) [0|0] "" Vector__XXX

BO_ 2016 ACM_Inst_Req: 8 Vector__XXX
 SG_ command_ctr : 15|8@0+ (1,0) [0|0] "" Vector__XXX
 SG_ command_code : 7|8@0+ (1,0) [0|0] "" Vector__XXX
 SG_ cc_word_2 : 55|16@0+ (1,0) [0|0] "" Vector__XXX
 SG_ cc_word_1 : 39|16@0+ (1,0) [0|0] "" Vector__XXX
 SG_ cc_byte_2 : 31|8@0+ (1,0) [0|0] "" Vector__XXX
 SG_ cc_byte_1 : 23|8@0+ (1,0) [0|0] "" Vector__XXX

BO_ 2023 ACM_Inst_DAQ1: 8 Vector__XXX

BO_ 1472 ESR_Sim1: 8 Instrumentation
 SG_ CAN_RX_SIM_TRACK_ID : 6|2@0+ (1,0) [0|0] "" Vector__XXX
 SG_ CAN_RX_SIM_STATUS : 4|2@0+ (1,0) [0|0] "" Vector__XXX
 SG_ CAN_RX_SIM_RANGE_RATE : 55|8@0- (0.25,0) [-32|31.75] "m/s" Vector__XXX
 SG_ CAN_RX_SIM_RANGE_ACCEL : 47|8@0- (0.25,0) [-32|31.75] "m/s/s" Vector__XXX
 SG_ CAN_RX_SIM_RANGE : 39|8@0+ (1,0) [0|0] "m" Vector__XXX
 SG_ CAN_RX_SIM_LAT_RATE : 31|8@0- (0.25,0) [-32|31.75] "m/s" Vector__XXX
 SG_ CAN_RX_SIM_LAT_POS : 23|8@0- (0.25,0) [-32|31.75] "m" Vector__XXX
 SG_ CAN_RX_SIM_FUNCTION : 2|3@0+ (1,0) [0|0] "" Vector__XXX
 SG_ CAN_RX_SIM_ANGLE : 15|8@0- (0.5,0) [-64|63.5] "deg" Vector__XXX

BO_ 1250 ESR_Status3: 8 ESR
 SG_ CAN_TX_SW_VERSION_PLD : 63|8@0+ (1,0) [0|0] "" Vector__XXX
 SG_ CAN_TX_SW_VERSION_HOST : 15|24@0+ (1,0) [0|0] "" Vector__XXX
 SG_ CAN_TX_HW_VERSION : 3|4@0+ (1,0) [0|0] "" Vector__XXX
 SG_ CAN_TX_INTERFACE_VERSION : 7|4@0+ (1,0) [0|0] "" Vector__XXX
 SG_ CAN_TX_SERIAL_NUM : 39|24@0+ (1,0) [0|0] "" Vector__XXX

BO_ 1280 ESR_Track01: 8 ESR
 SG_ CAN_TX_TRACK_GROUPING_CHANGED : 1|1@0+ (1,0) [0|0] "" Vector__XXX
 SG_ CAN_TX_TRACK_ONCOMING : 0|1@0+ (1,0) [0|0] "" Vector__XXX
 SG_ CAN_TX_TRACK_LAT_RATE : 7|6@0- (0.25,0) [-8|7.75] "" Vector__XXX
 SG_ CAN_TX_TRACK_BRIDGE_OBJECT : 39|1@0+ (1,0) [0|0] "" Vector__XXX
 SG_ CAN_TX_TRACK_WIDTH : 37|4@0+ (0.5,0) [0|7.5] "m" Vector__XXX
 SG_ CAN_TX_TRACK_STATUS : 15|3@0+ (1,0) [0|7] "" Vector__XXX
 SG_ CAN_TX_TRACK_ROLLING_COUNT : 38|1@0+ (1,0) [0|1] "" Vector__XXX
 SG_ CAN_TX_TRACK_RANGE_RATE : 53|14@0- (0.01,0) [-81.92|81.91] "m/s" Vector__XXX
 SG_ CAN_TX_TRACK_RANGE_ACCEL : 33|10@0- (0.05,0) [-25.6|25.55] "m/s/s" Vector__XXX
 SG_ CAN_TX_TRACK_RANGE : 18|11@0+ (0.1,0) [0|204.7] "m" Vector__XXX
 SG_ CAN_TX_TRACK_MED_RANGE_MODE : 55|2@0+ (1,0) [0|3] "" Vector__XXX
 SG_ CAN_TX_TRACK_ANGLE : 12|10@0- (0.1,0) [-51.2|51.1] "deg" Vector__XXX

BO_ 1249 ESR_Status2: 8 ESR
 SG_ CAN_TX_YAW_RATE_BIAS : 47|8@0- (0.125,0) [-16|15.875] "" Vector__XXX
 SG_ CAN_TX_VEH_SPD_COMP_FACTOR : 39|6@0- (0.001953125,1) [0.9375|1.060546875] "" Vector__XXX
 SG_ CAN_TX_SW_VERSION_DSP : 55|16@0+ (1,0) [0|0] "" Vector__XXX
 SG_ CAN_TX_TEMPERATURE : 31|8@0- (1,0) [-128|127] "degC" Vector__XXX
 SG_ CAN_TX_RAW_DATA_MODE : 11|1@0+ (1,0) [0|0] "" Vector__XXX
 SG_ CAN_TX_RANGE_PERF_ERROR : 14|1@0+ (1,0) [0|0] "" Vector__XXX
 SG_ CAN_TX_OVERHEAT_ERROR : 15|1@0+ (1,0) [0|0] "" Vector__XXX
 SG_ CAN_TX_MAXIMUM_TRACKS_ACK : 7|6@0+ (1,1) [1|64] "" Vector__XXX
 SG_ CAN_TX_INTERNAL_ERROR : 13|1@0+ (1,0) [0|0] "" Vector__XXX
 SG_ CAN_TX_GROUPING_MODE : 33|2@0+ (1,0) [0|0] "" Vector__XXX
 SG_ CAN_TX_XCVR_OPERATIONAL : 12|1@0+ (1,0) [0|0] "" Vector__XXX
 SG_ CAN_TX_STEERING_ANGLE_ACK : 10|11@0+ (1,0) [0|2047] "deg" Vector__XXX
 SG_ CAN_TX_ROLLING_COUNT_2 : 1|2@0+ (1,0) [0|0] "" Vector__XXX

BO_ 1248 ESR_Status1: 8 ESR
 SG_ CAN_TX_DSP_TIMESTAMP : 5|7@0+ (2,0) [0|254] "ms" Vector__XXX
 SG_ CAN_TX_COMM_ERROR : 14|1@0+ (1,0) [0|0] "" Vector__XXX
 SG_ CAN_TX_YAW_RATE_CALC : 47|12@0- (0.0625,0) [-128|127.9375] "deg/s" Vector__XXX
 SG_ CAN_TX_VEHICLE_SPEED_CALC : 50|11@0+ (0.0625,0) [0|127.9375] "m/s" Vector__XXX
 SG_ CAN_TX_SCAN_INDEX : 31|16@0+ (1,0) [0|65535] "" Vector__XXX
 SG_ CAN_TX_ROLLING_COUNT_1 : 7|2@0+ (1,0) [0|0] "" Vector__XXX
 SG_ CAN_TX_RADIUS_CURVATURE_CALC : 13|14@0- (1,0) [-8192|8191] "m" Vector__XXX

BO_ 1265 Vehicle2: 8 Vehicle
 SG_ CAN_RX_VOLVO_SHORT_TRACK_ROC : 31|4@0- (500,0) [-4000|3500] "m" Vector__XXX
 SG_ CAN_RX_MR_ONLY_TRANSMIT : 25|1@0+ (1,0) [0|0] "" Vector__XXX
 SG_ CAN_RX_LR_ONLY_TRANSMIT : 24|1@0+ (1,0) [0|0] "" Vector__XXX
 SG_ CAN_RX_HIGH_YAW_ANGLE : 21|6@0- (1,0) [-32|31] "deg" Vector__XXX
 SG_ CAN_RX_CLEAR_FAULTS : 22|1@0+ (1,0) [0|0] "" Vector__XXX
 SG_ CAN_RX_USE_ANGLE_MISALIGNMENT : 23|1@0+ (1,0) [0|0] "" Vector__XXX
 SG_ CAN_RX_TURN_SIGNAL_STATUS : 63|2@0+ (1,0) [0|0] "" Vector__XXX
 SG_ CAN_RX_BLOCKAGE_DISABLE : 54|1@0+ (1,0) [0|0] "" Vector__XXX
 SG_ CAN_RX_VEHICLE_SPEED_VALIDITY : 61|1@0+ (1,0) [0|0] "" Vector__XXX
 SG_ CAN_RX_MMR_UPSIDE_DOWN : 60|1@0+ (1,0) [0|1] "" Vector__XXX
 SG_ CAN_RX_WIPER_STATUS : 57|1@0+ (1,0) [0|0] "" Vector__XXX
 SG_ CAN_RX_RAW_DATA_ENABLE : 56|1@0+ (1,0) [0|0] "" Vector__XXX
 SG_ CAN_RX_RADAR_CMD_RADIATE : 55|1@0+ (1,0) [0|0] "" Vector__XXX
 SG_ CAN_RX_GROUPING_MODE : 59|2@0+ (1,0) [0|3] "" Vector__XXX
 SG_ CAN_RX_MAXIMUM_TRACKS : 53|6@0+ (1,1) [1|64] "" Vector__XXX
 SG_ CAN_RX_LATERAL_MOUNTING_OFFSET : 47|8@0- (0.015625,0) [-2|1.984375] "m" Vector__XXX
 SG_ CAN_RX_ANGLE_MISALIGNMENT : 39|8@0- (0.0625,0) [-8|7.9375] "deg" Vector__XXX
 SG_ CAN_RX_SCAN_INDEX_ACK : 7|16@0+ (1,0) [0|65535] "" Vector__XXX

BO_ 1264 Vehicle1: 8 Vehicle
 SG_ CAN_RX_STEERING_ANGLE_VALIDITY : 47|1@0+ (1,0) [0|0] "" Vector__XXX
 SG_ CAN_RX_STEERING_ANGLE_RATE : 50|11@0+ (1,0) [0|2047] "deg/s" Vector__XXX
 SG_ CAN_RX_STEERING_ANGLE_SIGN : 46|1@0+ (1,0) [0|0] "" Vector__XXX
 SG_ CAN_RX_STEERING_ANGLE_RATE_SIGN : 30|1@0+ (1,0) [0|0] "" Vector__XXX
 SG_ CAN_RX_STEERING_ANGLE : 45|11@0+ (1,0) [0|2047] "deg" Vector__XXX
 SG_ CAN_RX_RADIUS_CURVATURE : 29|14@0- (1,0) [-8192|8191] "m" Vector__XXX
 SG_ CAN_RX_YAW_RATE_VALIDITY : 31|1@0+ (1,0) [0|0] "" Vector__XXX
 SG_ CAN_RX_YAW_RATE : 11|12@0- (0.0625,0) [-128|127.9375] "deg/s" Vector__XXX
 SG_ CAN_RX_VEHICLE_SPEED_DIRECTION : 12|1@0+ (1,0) [0|0] "" Vector__XXX
 SG_ CAN_RX_VEHICLE_SPEED : 7|11@0+ (0.0625,0) [0|127.9375] "m/s"  ESR

CM_ BO_ 3221225472 "This is a message for not used signals, created by Vector CANdb++ DBC OLE DB Provider.";
CM_ SG_ 1522 CAN_RX_ANGLE_MOUNTING_OFFSET "(+) = clockwise";
CM_ SG_ 1265 CAN_RX_LATERAL_MOUNTING_OFFSET "(+) = to the right from driver's perspective";
CM_ SG_ 1265 CAN_RX_ANGLE_MISALIGNMENT "(+) = clockwise";
VAL_ 3221225472 CAN_RX_MR_LR_MODE 3 "Output all medium-range and long" 2 "Output only long-range tracks" 1 "Output only medium-range tracks" 0 "Output 32 medium-range and 32-lo" ;
VAL_ 3221225472 CAN_TX_TRACK_BRIDGE_OBJECT 1 "Bridge" 0 "Not_Bridge" ;
VAL_ 3221225472 CAN_TX_TRACK_STATUS 7 "New_Coasted_Target" 6 "Invalid_Coasted_Target" 5 "Merged_Target" 4 "Coasted_Target" 3 "Updated_Target" 2 "New_Updated_Target" 1 "New_Target" 0 "No_Target" ;
VAL_ 3221225472 CAN_TX_TRACK_MED_RANGE_MODE 3 "Both_MR_LR_Update" 2 "LR_Update_Only" 1 "MR_Update_Only" 0 "No_MR_LR_Update" ;
VAL_ 1285 CAN_TX_TRACK_GROUPING_CHANGED 1 "GroupingChanged" 0 "GroupingUnchanged" ;
VAL_ 1285 CAN_TX_TRACK_ONCOMING 1 "Oncoming" 0 "NotOncoming" ;
VAL_ 1285 CAN_TX_TRACK_BRIDGE_OBJECT 1 "Bridge" 0 "Not_Bridge" ;
VAL_ 1285 CAN_TX_TRACK_STATUS 7 "New_Coasted_Target" 6 "Invalid_Coasted_Target" 5 "Merged_Target" 4 "Coasted_Target" 3 "Updated_Target" 2 "New_Updated_Target" 1 "New_Target" 0 "No_Target" ;
VAL_ 1285 CAN_TX_TRACK_MED_RANGE_MODE 3 "Both_MR_LR_Update" 2 "LR_Update_Only" 1 "MR_Update_Only" 0 "No_MR_LR_Update" ;
VAL_ 1286 CAN_TX_TRACK_GROUPING_CHANGED 1 "GroupingChanged" 0 "GroupingUnchanged" ;
VAL_ 1286 CAN_TX_TRACK_ONCOMING 1 "Oncoming" 0 "NotOncoming" ;
VAL_ 1286 CAN_TX_TRACK_BRIDGE_OBJECT 1 "Bridge" 0 "Not_Bridge" ;
VAL_ 1286 CAN_TX_TRACK_STATUS 7 "New_Coasted_Target" 6 "Invalid_Coasted_Target" 5 "Merged_Target" 4 "Coasted_Target" 3 "Updated_Target" 2 "New_Updated_Target" 1 "New_Target" 0 "No_Target" ;
VAL_ 1286 CAN_TX_TRACK_MED_RANGE_MODE 3 "Both_MR_LR_Update" 2 "LR_Update_Only" 1 "MR_Update_Only" 0 "No_MR_LR_Update" ;
VAL_ 1312 CAN_TX_TRACK_GROUPING_CHANGED 1 "GroupingChanged" 0 "GroupingUnchanged" ;
VAL_ 1312 CAN_TX_TRACK_ONCOMING 1 "Oncoming" 0 "NotOncoming" ;
VAL_ 1312 CAN_TX_TRACK_BRIDGE_OBJECT 1 "Bridge" 0 "Not_Bridge" ;
VAL_ 1312 CAN_TX_TRACK_STATUS 7 "New_Coasted_Target" 6 "Invalid_Coasted_Target" 5 "Merged_Target" 4 "Coasted_Target" 3 "Updated_Target" 2 "New_Updated_Target" 1 "New_Target" 0 "No_Target" ;
VAL_ 1312 CAN_TX_TRACK_MED_RANGE_MODE 3 "Both_MR_LR_Update" 2 "LR_Update_Only" 1 "MR_Update_Only" 0 "No_MR_LR_Update" ;
VAL_ 1307 CAN_TX_TRACK_GROUPING_CHANGED 1 "GroupingChanged" 0 "GroupingUnchanged" ;
VAL_ 1307 CAN_TX_TRACK_ONCOMING 1 "Oncoming" 0 "NotOncoming" ;
VAL_ 1307 CAN_TX_TRACK_BRIDGE_OBJECT 1 "Bridge" 0 "Not_Bridge" ;
VAL_ 1307 CAN_TX_TRACK_STATUS 7 "New_Coasted_Target" 6 "Invalid_Coasted_Target" 5 "Merged_Target" 4 "Coasted_Target" 3 "Updated_Target" 2 "New_Updated_Target" 1 "New_Target" 0 "No_Target" ;
VAL_ 1307 CAN_TX_TRACK_MED_RANGE_MODE 3 "Both_MR_LR_Update" 2 "LR_Update_Only" 1 "MR_Update_Only" 0 "No_MR_LR_Update" ;
VAL_ 1308 CAN_TX_TRACK_GROUPING_CHANGED 1 "GroupingChanged" 0 "GroupingUnchanged" ;
VAL_ 1308 CAN_TX_TRACK_ONCOMING 1 "Oncoming" 0 "NotOncoming" ;
VAL_ 1308 CAN_TX_TRACK_BRIDGE_OBJECT 1 "Bridge" 0 "Not_Bridge" ;
VAL_ 1308 CAN_TX_TRACK_STATUS 7 "New_Coasted_Target" 6 "Invalid_Coasted_Target" 5 "Merged_Target" 4 "Coasted_Target" 3 "Updated_Target" 2 "New_Updated_Target" 1 "New_Target" 0 "No_Target" ;
VAL_ 1308 CAN_TX_TRACK_MED_RANGE_MODE 3 "Both_MR_LR_Update" 2 "LR_Update_Only" 1 "MR_Update_Only" 0 "No_MR_LR_Update" ;
VAL_ 1303 CAN_TX_TRACK_GROUPING_CHANGED 1 "GroupingChanged" 0 "GroupingUnchanged" ;
VAL_ 1303 CAN_TX_TRACK_ONCOMING 1 "Oncoming" 0 "NotOncoming" ;
VAL_ 1303 CAN_TX_TRACK_BRIDGE_OBJECT 1 "Bridge" 0 "Not_Bridge" ;
VAL_ 1303 CAN_TX_TRACK_STATUS 7 "New_Coasted_Target" 6 "Invalid_Coasted_Target" 5 "Merged_Target" 4 "Coasted_Target" 3 "Updated_Target" 2 "New_Updated_Target" 1 "New_Target" 0 "No_Target" ;
VAL_ 1303 CAN_TX_TRACK_MED_RANGE_MODE 3 "Both_MR_LR_Update" 2 "LR_Update_Only" 1 "MR_Update_Only" 0 "No_MR_LR_Update" ;
VAL_ 1298 CAN_TX_TRACK_GROUPING_CHANGED 1 "GroupingChanged" 0 "GroupingUnchanged" ;
VAL_ 1298 CAN_TX_TRACK_ONCOMING 1 "Oncoming" 0 "NotOncoming" ;
VAL_ 1298 CAN_TX_TRACK_BRIDGE_OBJECT 1 "Bridge" 0 "Not_Bridge" ;
VAL_ 1298 CAN_TX_TRACK_STATUS 7 "New_Coasted_Target" 6 "Invalid_Coasted_Target" 5 "Merged_Target" 4 "Coasted_Target" 3 "Updated_Target" 2 "New_Updated_Target" 1 "New_Target" 0 "No_Target" ;
VAL_ 1298 CAN_TX_TRACK_MED_RANGE_MODE 3 "Both_MR_LR_Update" 2 "LR_Update_Only" 1 "MR_Update_Only" 0 "No_MR_LR_Update" ;
VAL_ 1306 CAN_TX_TRACK_GROUPING_CHANGED 1 "GroupingChanged" 0 "GroupingUnchanged" ;
VAL_ 1306 CAN_TX_TRACK_ONCOMING 1 "Oncoming" 0 "NotOncoming" ;
VAL_ 1306 CAN_TX_TRACK_BRIDGE_OBJECT 1 "Bridge" 0 "Not_Bridge" ;
VAL_ 1306 CAN_TX_TRACK_STATUS 7 "New_Coasted_Target" 6 "Invalid_Coasted_Target" 5 "Merged_Target" 4 "Coasted_Target" 3 "Updated_Target" 2 "New_Updated_Target" 1 "New_Target" 0 "No_Target" ;
VAL_ 1306 CAN_TX_TRACK_MED_RANGE_MODE 3 "Both_MR_LR_Update" 2 "LR_Update_Only" 1 "MR_Update_Only" 0 "No_MR_LR_Update" ;
VAL_ 1309 CAN_TX_TRACK_GROUPING_CHANGED 1 "GroupingChanged" 0 "GroupingUnchanged" ;
VAL_ 1309 CAN_TX_TRACK_ONCOMING 1 "Oncoming" 0 "NotOncoming" ;
VAL_ 1309 CAN_TX_TRACK_BRIDGE_OBJECT 1 "Bridge" 0 "Not_Bridge" ;
VAL_ 1309 CAN_TX_TRACK_STATUS 7 "New_Coasted_Target" 6 "Invalid_Coasted_Target" 5 "Merged_Target" 4 "Coasted_Target" 3 "Updated_Target" 2 "New_Updated_Target" 1 "New_Target" 0 "No_Target" ;
VAL_ 1309 CAN_TX_TRACK_MED_RANGE_MODE 3 "Both_MR_LR_Update" 2 "LR_Update_Only" 1 "MR_Update_Only" 0 "No_MR_LR_Update" ;
VAL_ 1292 CAN_TX_TRACK_GROUPING_CHANGED 1 "GroupingChanged" 0 "GroupingUnchanged" ;
VAL_ 1292 CAN_TX_TRACK_ONCOMING 1 "Oncoming" 0 "NotOncoming" ;
VAL_ 1292 CAN_TX_TRACK_BRIDGE_OBJECT 1 "Bridge" 0 "Not_Bridge" ;
VAL_ 1292 CAN_TX_TRACK_STATUS 7 "New_Coasted_Target" 6 "Invalid_Coasted_Target" 5 "Merged_Target" 4 "Coasted_Target" 3 "Updated_Target" 2 "New_Updated_Target" 1 "New_Target" 0 "No_Target" ;
VAL_ 1292 CAN_TX_TRACK_MED_RANGE_MODE 3 "Both_MR_LR_Update" 2 "LR_Update_Only" 1 "MR_Update_Only" 0 "No_MR_LR_Update" ;
VAL_ 1297 CAN_TX_TRACK_GROUPING_CHANGED 1 "GroupingChanged" 0 "GroupingUnchanged" ;
VAL_ 1297 CAN_TX_TRACK_ONCOMING 1 "Oncoming" 0 "NotOncoming" ;
VAL_ 1297 CAN_TX_TRACK_BRIDGE_OBJECT 1 "Bridge" 0 "Not_Bridge" ;
VAL_ 1297 CAN_TX_TRACK_STATUS 7 "New_Coasted_Target" 6 "Invalid_Coasted_Target" 5 "Merged_Target" 4 "Coasted_Target" 3 "Updated_Target" 2 "New_Updated_Target" 1 "New_Target" 0 "No_Target" ;
VAL_ 1297 CAN_TX_TRACK_MED_RANGE_MODE 3 "Both_MR_LR_Update" 2 "LR_Update_Only" 1 "MR_Update_Only" 0 "No_MR_LR_Update" ;
VAL_ 1305 CAN_TX_TRACK_GROUPING_CHANGED 1 "GroupingChanged" 0 "GroupingUnchanged" ;
VAL_ 1305 CAN_TX_TRACK_ONCOMING 1 "Oncoming" 0 "NotOncoming" ;
VAL_ 1305 CAN_TX_TRACK_BRIDGE_OBJECT 1 "Bridge" 0 "Not_Bridge" ;
VAL_ 1305 CAN_TX_TRACK_STATUS 7 "New_Coasted_Target" 6 "Invalid_Coasted_Target" 5 "Merged_Target" 4 "Coasted_Target" 3 "Updated_Target" 2 "New_Updated_Target" 1 "New_Target" 0 "No_Target" ;
VAL_ 1305 CAN_TX_TRACK_MED_RANGE_MODE 3 "Both_MR_LR_Update" 2 "LR_Update_Only" 1 "MR_Update_Only" 0 "No_MR_LR_Update" ;
VAL_ 1310 CAN_TX_TRACK_GROUPING_CHANGED 1 "GroupingChanged" 0 "GroupingUnchanged" ;
VAL_ 1310 CAN_TX_TRACK_ONCOMING 1 "Oncoming" 0 "NotOncoming" ;
VAL_ 1310 CAN_TX_TRACK_BRIDGE_OBJECT 1 "Bridge" 0 "Not_Bridge" ;
VAL_ 1310 CAN_TX_TRACK_STATUS 7 "New_Coasted_Target" 6 "Invalid_Coasted_Target" 5 "Merged_Target" 4 "Coasted_Target" 3 "Updated_Target" 2 "New_Updated_Target" 1 "New_Target" 0 "No_Target" ;
VAL_ 1310 CAN_TX_TRACK_MED_RANGE_MODE 3 "Both_MR_LR_Update" 2 "LR_Update_Only" 1 "MR_Update_Only" 0 "No_MR_LR_Update" ;
VAL_ 1296 CAN_TX_TRACK_GROUPING_CHANGED 1 "GroupingChanged" 0 "GroupingUnchanged" ;
VAL_ 1296 CAN_TX_TRACK_ONCOMING 1 "Oncoming" 0 "NotOncoming" ;
VAL_ 1296 CAN_TX_TRACK_BRIDGE_OBJECT 1 "Bridge" 0 "Not_Bridge" ;
VAL_ 1296 CAN_TX_TRACK_STATUS 7 "New_Coasted_Target" 6 "Invalid_Coasted_Target" 5 "Merged_Target" 4 "Coasted_Target" 3 "Updated_Target" 2 "New_Updated_Target" 1 "New_Target" 0 "No_Target" ;
VAL_ 1296 CAN_TX_TRACK_MED_RANGE_MODE 3 "Both_MR_LR_Update" 2 "LR_Update_Only" 1 "MR_Update_Only" 0 "No_MR_LR_Update" ;
VAL_ 1299 CAN_TX_TRACK_GROUPING_CHANGED 1 "GroupingChanged" 0 "GroupingUnchanged" ;
VAL_ 1299 CAN_TX_TRACK_ONCOMING 1 "Oncoming" 0 "NotOncoming" ;
VAL_ 1299 CAN_TX_TRACK_BRIDGE_OBJECT 1 "Bridge" 0 "Not_Bridge" ;
VAL_ 1299 CAN_TX_TRACK_STATUS 7 "New_Coasted_Target" 6 "Invalid_Coasted_Target" 5 "Merged_Target" 4 "Coasted_Target" 3 "Updated_Target" 2 "New_Updated_Target" 1 "New_Target" 0 "No_Target" ;
VAL_ 1299 CAN_TX_TRACK_MED_RANGE_MODE 3 "Both_MR_LR_Update" 2 "LR_Update_Only" 1 "MR_Update_Only" 0 "No_MR_LR_Update" ;
VAL_ 1291 CAN_TX_TRACK_GROUPING_CHANGED 1 "GroupingChanged" 0 "GroupingUnchanged" ;
VAL_ 1291 CAN_TX_TRACK_ONCOMING 1 "Oncoming" 0 "NotOncoming" ;
VAL_ 1291 CAN_TX_TRACK_BRIDGE_OBJECT 1 "Bridge" 0 "Not_Bridge" ;
VAL_ 1291 CAN_TX_TRACK_STATUS 7 "New_Coasted_Target" 6 "Invalid_Coasted_Target" 5 "Merged_Target" 4 "Coasted_Target" 3 "Updated_Target" 2 "New_Updated_Target" 1 "New_Target" 0 "No_Target" ;
VAL_ 1291 CAN_TX_TRACK_MED_RANGE_MODE 3 "Both_MR_LR_Update" 2 "LR_Update_Only" 1 "MR_Update_Only" 0 "No_MR_LR_Update" ;
VAL_ 1288 CAN_TX_TRACK_GROUPING_CHANGED 1 "GroupingChanged" 0 "GroupingUnchanged" ;
VAL_ 1288 CAN_TX_TRACK_ONCOMING 1 "Oncoming" 0 "NotOncoming" ;
VAL_ 1288 CAN_TX_TRACK_BRIDGE_OBJECT 1 "Bridge" 0 "Not_Bridge" ;
VAL_ 1288 CAN_TX_TRACK_STATUS 7 "New_Coasted_Target" 6 "Invalid_Coasted_Target" 5 "Merged_Target" 4 "Coasted_Target" 3 "Updated_Target" 2 "New_Updated_Target" 1 "New_Target" 0 "No_Target" ;
VAL_ 1288 CAN_TX_TRACK_MED_RANGE_MODE 3 "Both_MR_LR_Update" 2 "LR_Update_Only" 1 "MR_Update_Only" 0 "No_MR_LR_Update" ;
VAL_ 1289 CAN_TX_TRACK_GROUPING_CHANGED 1 "GroupingChanged" 0 "GroupingUnchanged" ;
VAL_ 1289 CAN_TX_TRACK_ONCOMING 1 "Oncoming" 0 "NotOncoming" ;
VAL_ 1289 CAN_TX_TRACK_BRIDGE_OBJECT 1 "Bridge" 0 "Not_Bridge" ;
VAL_ 1289 CAN_TX_TRACK_STATUS 7 "New_Coasted_Target" 6 "Invalid_Coasted_Target" 5 "Merged_Target" 4 "Coasted_Target" 3 "Updated_Target" 2 "New_Updated_Target" 1 "New_Target" 0 "No_Target" ;
VAL_ 1289 CAN_TX_TRACK_MED_RANGE_MODE 3 "Both_MR_LR_Update" 2 "LR_Update_Only" 1 "MR_Update_Only" 0 "No_MR_LR_Update" ;
VAL_ 1301 CAN_TX_TRACK_GROUPING_CHANGED 1 "GroupingChanged" 0 "GroupingUnchanged" ;
VAL_ 1301 CAN_TX_TRACK_ONCOMING 1 "Oncoming" 0 "NotOncoming" ;
VAL_ 1301 CAN_TX_TRACK_BRIDGE_OBJECT 1 "Bridge" 0 "Not_Bridge" ;
VAL_ 1301 CAN_TX_TRACK_STATUS 7 "New_Coasted_Target" 6 "Invalid_Coasted_Target" 5 "Merged_Target" 4 "Coasted_Target" 3 "Updated_Target" 2 "New_Updated_Target" 1 "New_Target" 0 "No_Target" ;
VAL_ 1301 CAN_TX_TRACK_MED_RANGE_MODE 3 "Both_MR_LR_Update" 2 "LR_Update_Only" 1 "MR_Update_Only" 0 "No_MR_LR_Update" ;
VAL_ 1295 CAN_TX_TRACK_GROUPING_CHANGED 1 "GroupingChanged" 0 "GroupingUnchanged" ;
VAL_ 1295 CAN_TX_TRACK_ONCOMING 1 "Oncoming" 0 "NotOncoming" ;
VAL_ 1295 CAN_TX_TRACK_BRIDGE_OBJECT 1 "Bridge" 0 "Not_Bridge" ;
VAL_ 1295 CAN_TX_TRACK_STATUS 7 "New_Coasted_Target" 6 "Invalid_Coasted_Target" 5 "Merged_Target" 4 "Coasted_Target" 3 "Updated_Target" 2 "New_Updated_Target" 1 "New_Target" 0 "No_Target" ;
VAL_ 1295 CAN_TX_TRACK_MED_RANGE_MODE 3 "Both_MR_LR_Update" 2 "LR_Update_Only" 1 "MR_Update_Only" 0 "No_MR_LR_Update" ;
VAL_ 1300 CAN_TX_TRACK_GROUPING_CHANGED 1 "GroupingChanged" 0 "GroupingUnchanged" ;
VAL_ 1300 CAN_TX_TRACK_ONCOMING 1 "Oncoming" 0 "NotOncoming" ;
VAL_ 1300 CAN_TX_TRACK_BRIDGE_OBJECT 1 "Bridge" 0 "Not_Bridge" ;
VAL_ 1300 CAN_TX_TRACK_STATUS 7 "New_Coasted_Target" 6 "Invalid_Coasted_Target" 5 "Merged_Target" 4 "Coasted_Target" 3 "Updated_Target" 2 "New_Updated_Target" 1 "New_Target" 0 "No_Target" ;
VAL_ 1300 CAN_TX_TRACK_MED_RANGE_MODE 3 "Both_MR_LR_Update" 2 "LR_Update_Only" 1 "MR_Update_Only" 0 "No_MR_LR_Update" ;
VAL_ 1294 CAN_TX_TRACK_GROUPING_CHANGED 1 "GroupingChanged" 0 "GroupingUnchanged" ;
VAL_ 1294 CAN_TX_TRACK_ONCOMING 1 "Oncoming" 0 "NotOncoming" ;
VAL_ 1294 CAN_TX_TRACK_BRIDGE_OBJECT 1 "Bridge" 0 "Not_Bridge" ;
VAL_ 1294 CAN_TX_TRACK_STATUS 7 "New_Coasted_Target" 6 "Invalid_Coasted_Target" 5 "Merged_Target" 4 "Coasted_Target" 3 "Updated_Target" 2 "New_Updated_Target" 1 "New_Target" 0 "No_Target" ;
VAL_ 1294 CAN_TX_TRACK_MED_RANGE_MODE 3 "Both_MR_LR_Update" 2 "LR_Update_Only" 1 "MR_Update_Only" 0 "No_MR_LR_Update" ;
VAL_ 1302 CAN_TX_TRACK_GROUPING_CHANGED 1 "GroupingChanged" 0 "GroupingUnchanged" ;
VAL_ 1302 CAN_TX_TRACK_ONCOMING 1 "Oncoming" 0 "NotOncoming" ;
VAL_ 1302 CAN_TX_TRACK_BRIDGE_OBJECT 1 "Bridge" 0 "Not_Bridge" ;
VAL_ 1302 CAN_TX_TRACK_STATUS 7 "New_Coasted_Target" 6 "Invalid_Coasted_Target" 5 "Merged_Target" 4 "Coasted_Target" 3 "Updated_Target" 2 "New_Updated_Target" 1 "New_Target" 0 "No_Target" ;
VAL_ 1302 CAN_TX_TRACK_MED_RANGE_MODE 3 "Both_MR_LR_Update" 2 "LR_Update_Only" 1 "MR_Update_Only" 0 "No_MR_LR_Update" ;
VAL_ 1287 CAN_TX_TRACK_GROUPING_CHANGED 1 "GroupingChanged" 0 "GroupingUnchanged" ;
VAL_ 1287 CAN_TX_TRACK_ONCOMING 1 "Oncoming" 0 "NotOncoming" ;
VAL_ 1287 CAN_TX_TRACK_BRIDGE_OBJECT 1 "Bridge" 0 "Not_Bridge" ;
VAL_ 1287 CAN_TX_TRACK_STATUS 7 "New_Coasted_Target" 6 "Invalid_Coasted_Target" 5 "Merged_Target" 4 "Coasted_Target" 3 "Updated_Target" 2 "New_Updated_Target" 1 "New_Target" 0 "No_Target" ;
VAL_ 1287 CAN_TX_TRACK_MED_RANGE_MODE 3 "Both_MR_LR_Update" 2 "LR_Update_Only" 1 "MR_Update_Only" 0 "No_MR_LR_Update" ;
VAL_ 1304 CAN_TX_TRACK_GROUPING_CHANGED 1 "GroupingChanged" 0 "GroupingUnchanged" ;
VAL_ 1304 CAN_TX_TRACK_ONCOMING 1 "Oncoming" 0 "NotOncoming" ;
VAL_ 1304 CAN_TX_TRACK_BRIDGE_OBJECT 1 "Bridge" 0 "Not_Bridge" ;
VAL_ 1304 CAN_TX_TRACK_STATUS 7 "New_Coasted_Target" 6 "Invalid_Coasted_Target" 5 "Merged_Target" 4 "Coasted_Target" 3 "Updated_Target" 2 "New_Updated_Target" 1 "New_Target" 0 "No_Target" ;
VAL_ 1304 CAN_TX_TRACK_MED_RANGE_MODE 3 "Both_MR_LR_Update" 2 "LR_Update_Only" 1 "MR_Update_Only" 0 "No_MR_LR_Update" ;
VAL_ 1313 CAN_TX_TRACK_GROUPING_CHANGED 1 "GroupingChanged" 0 "GroupingUnchanged" ;
VAL_ 1313 CAN_TX_TRACK_ONCOMING 1 "Oncoming" 0 "NotOncoming" ;
VAL_ 1313 CAN_TX_TRACK_BRIDGE_OBJECT 1 "Bridge" 0 "Not_Bridge" ;
VAL_ 1313 CAN_TX_TRACK_STATUS 7 "New_Coasted_Target" 6 "Invalid_Coasted_Target" 5 "Merged_Target" 4 "Coasted_Target" 3 "Updated_Target" 2 "New_Updated_Target" 1 "New_Target" 0 "No_Target" ;
VAL_ 1313 CAN_TX_TRACK_MED_RANGE_MODE 3 "Both_MR_LR_Update" 2 "LR_Update_Only" 1 "MR_Update_Only" 0 "No_MR_LR_Update" ;
VAL_ 1315 CAN_TX_TRACK_GROUPING_CHANGED 1 "GroupingChanged" 0 "GroupingUnchanged" ;
VAL_ 1315 CAN_TX_TRACK_ONCOMING 1 "Oncoming" 0 "NotOncoming" ;
VAL_ 1315 CAN_TX_TRACK_BRIDGE_OBJECT 1 "Bridge" 0 "Not_Bridge" ;
VAL_ 1315 CAN_TX_TRACK_STATUS 7 "New_Coasted_Target" 6 "Invalid_Coasted_Target" 5 "Merged_Target" 4 "Coasted_Target" 3 "Updated_Target" 2 "New_Updated_Target" 1 "New_Target" 0 "No_Target" ;
VAL_ 1315 CAN_TX_TRACK_MED_RANGE_MODE 3 "Both_MR_LR_Update" 2 "LR_Update_Only" 1 "MR_Update_Only" 0 "No_MR_LR_Update" ;
VAL_ 1343 CAN_TX_TRACK_GROUPING_CHANGED 1 "GroupingChanged" 0 "GroupingUnchanged" ;
VAL_ 1343 CAN_TX_TRACK_ONCOMING 1 "Oncoming" 0 "NotOncoming" ;
VAL_ 1343 CAN_TX_TRACK_BRIDGE_OBJECT 1 "Bridge" 0 "Not_Bridge" ;
VAL_ 1343 CAN_TX_TRACK_STATUS 7 "New_Coasted_Target" 6 "Invalid_Coasted_Target" 5 "Merged_Target" 4 "Coasted_Target" 3 "Updated_Target" 2 "New_Updated_Target" 1 "New_Target" 0 "No_Target" ;
VAL_ 1343 CAN_TX_TRACK_MED_RANGE_MODE 3 "Both_MR_LR_Update" 2 "LR_Update_Only" 1 "MR_Update_Only" 0 "No_MR_LR_Update" ;
VAL_ 1314 CAN_TX_TRACK_GROUPING_CHANGED 1 "GroupingChanged" 0 "GroupingUnchanged" ;
VAL_ 1314 CAN_TX_TRACK_ONCOMING 1 "Oncoming" 0 "NotOncoming" ;
VAL_ 1314 CAN_TX_TRACK_BRIDGE_OBJECT 1 "Bridge" 0 "Not_Bridge" ;
VAL_ 1314 CAN_TX_TRACK_STATUS 7 "New_Coasted_Target" 6 "Invalid_Coasted_Target" 5 "Merged_Target" 4 "Coasted_Target" 3 "Updated_Target" 2 "New_Updated_Target" 1 "New_Target" 0 "No_Target" ;
VAL_ 1314 CAN_TX_TRACK_MED_RANGE_MODE 3 "Both_MR_LR_Update" 2 "LR_Update_Only" 1 "MR_Update_Only" 0 "No_MR_LR_Update" ;
VAL_ 1332 CAN_TX_TRACK_GROUPING_CHANGED 1 "GroupingChanged" 0 "GroupingUnchanged" ;
VAL_ 1332 CAN_TX_TRACK_ONCOMING 1 "Oncoming" 0 "NotOncoming" ;
VAL_ 1332 CAN_TX_TRACK_BRIDGE_OBJECT 1 "Bridge" 0 "Not_Bridge" ;
VAL_ 1332 CAN_TX_TRACK_STATUS 7 "New_Coasted_Target" 6 "Invalid_Coasted_Target" 5 "Merged_Target" 4 "Coasted_Target" 3 "Updated_Target" 2 "New_Updated_Target" 1 "New_Target" 0 "No_Target" ;
VAL_ 1332 CAN_TX_TRACK_MED_RANGE_MODE 3 "Both_MR_LR_Update" 2 "LR_Update_Only" 1 "MR_Update_Only" 0 "No_MR_LR_Update" ;
VAL_ 1316 CAN_TX_TRACK_GROUPING_CHANGED 1 "GroupingChanged" 0 "GroupingUnchanged" ;
VAL_ 1316 CAN_TX_TRACK_ONCOMING 1 "Oncoming" 0 "NotOncoming" ;
VAL_ 1316 CAN_TX_TRACK_BRIDGE_OBJECT 1 "Bridge" 0 "Not_Bridge" ;
VAL_ 1316 CAN_TX_TRACK_STATUS 7 "New_Coasted_Target" 6 "Invalid_Coasted_Target" 5 "Merged_Target" 4 "Coasted_Target" 3 "Updated_Target" 2 "New_Updated_Target" 1 "New_Target" 0 "No_Target" ;
VAL_ 1316 CAN_TX_TRACK_MED_RANGE_MODE 3 "Both_MR_LR_Update" 2 "LR_Update_Only" 1 "MR_Update_Only" 0 "No_MR_LR_Update" ;
VAL_ 1317 CAN_TX_TRACK_GROUPING_CHANGED 1 "GroupingChanged" 0 "GroupingUnchanged" ;
VAL_ 1317 CAN_TX_TRACK_ONCOMING 1 "Oncoming" 0 "NotOncoming" ;
VAL_ 1317 CAN_TX_TRACK_BRIDGE_OBJECT 1 "Bridge" 0 "Not_Bridge" ;
VAL_ 1317 CAN_TX_TRACK_STATUS 7 "New_Coasted_Target" 6 "Invalid_Coasted_Target" 5 "Merged_Target" 4 "Coasted_Target" 3 "Updated_Target" 2 "New_Updated_Target" 1 "New_Target" 0 "No_Target" ;
VAL_ 1317 CAN_TX_TRACK_MED_RANGE_MODE 3 "Both_MR_LR_Update" 2 "LR_Update_Only" 1 "MR_Update_Only" 0 "No_MR_LR_Update" ;
VAL_ 1327 CAN_TX_TRACK_GROUPING_CHANGED 1 "GroupingChanged" 0 "GroupingUnchanged" ;
VAL_ 1327 CAN_TX_TRACK_ONCOMING 1 "Oncoming" 0 "NotOncoming" ;
VAL_ 1327 CAN_TX_TRACK_BRIDGE_OBJECT 1 "Bridge" 0 "Not_Bridge" ;
VAL_ 1327 CAN_TX_TRACK_STATUS 7 "New_Coasted_Target" 6 "Invalid_Coasted_Target" 5 "Merged_Target" 4 "Coasted_Target" 3 "Updated_Target" 2 "New_Updated_Target" 1 "New_Target" 0 "No_Target" ;
VAL_ 1327 CAN_TX_TRACK_MED_RANGE_MODE 3 "Both_MR_LR_Update" 2 "LR_Update_Only" 1 "MR_Update_Only" 0 "No_MR_LR_Update" ;
VAL_ 1324 CAN_TX_TRACK_GROUPING_CHANGED 1 "GroupingChanged" 0 "GroupingUnchanged" ;
VAL_ 1324 CAN_TX_TRACK_ONCOMING 1 "Oncoming" 0 "NotOncoming" ;
VAL_ 1324 CAN_TX_TRACK_BRIDGE_OBJECT 1 "Bridge" 0 "Not_Bridge" ;
VAL_ 1324 CAN_TX_TRACK_STATUS 7 "New_Coasted_Target" 6 "Invalid_Coasted_Target" 5 "Merged_Target" 4 "Coasted_Target" 3 "Updated_Target" 2 "New_Updated_Target" 1 "New_Target" 0 "No_Target" ;
VAL_ 1324 CAN_TX_TRACK_MED_RANGE_MODE 3 "Both_MR_LR_Update" 2 "LR_Update_Only" 1 "MR_Update_Only" 0 "No_MR_LR_Update" ;
VAL_ 1339 CAN_TX_TRACK_GROUPING_CHANGED 1 "GroupingChanged" 0 "GroupingUnchanged" ;
VAL_ 1339 CAN_TX_TRACK_ONCOMING 1 "Oncoming" 0 "NotOncoming" ;
VAL_ 1339 CAN_TX_TRACK_BRIDGE_OBJECT 1 "Bridge" 0 "Not_Bridge" ;
VAL_ 1339 CAN_TX_TRACK_STATUS 7 "New_Coasted_Target" 6 "Invalid_Coasted_Target" 5 "Merged_Target" 4 "Coasted_Target" 3 "Updated_Target" 2 "New_Updated_Target" 1 "New_Target" 0 "No_Target" ;
VAL_ 1339 CAN_TX_TRACK_MED_RANGE_MODE 3 "Both_MR_LR_Update" 2 "LR_Update_Only" 1 "MR_Update_Only" 0 "No_MR_LR_Update" ;
VAL_ 1322 CAN_TX_TRACK_GROUPING_CHANGED 1 "GroupingChanged" 0 "GroupingUnchanged" ;
VAL_ 1322 CAN_TX_TRACK_ONCOMING 1 "Oncoming" 0 "NotOncoming" ;
VAL_ 1322 CAN_TX_TRACK_BRIDGE_OBJECT 1 "Bridge" 0 "Not_Bridge" ;
VAL_ 1322 CAN_TX_TRACK_STATUS 7 "New_Coasted_Target" 6 "Invalid_Coasted_Target" 5 "Merged_Target" 4 "Coasted_Target" 3 "Updated_Target" 2 "New_Updated_Target" 1 "New_Target" 0 "No_Target" ;
VAL_ 1322 CAN_TX_TRACK_MED_RANGE_MODE 3 "Both_MR_LR_Update" 2 "LR_Update_Only" 1 "MR_Update_Only" 0 "No_MR_LR_Update" ;
VAL_ 1318 CAN_TX_TRACK_GROUPING_CHANGED 1 "GroupingChanged" 0 "GroupingUnchanged" ;
VAL_ 1318 CAN_TX_TRACK_ONCOMING 1 "Oncoming" 0 "NotOncoming" ;
VAL_ 1318 CAN_TX_TRACK_BRIDGE_OBJECT 1 "Bridge" 0 "Not_Bridge" ;
VAL_ 1318 CAN_TX_TRACK_STATUS 7 "New_Coasted_Target" 6 "Invalid_Coasted_Target" 5 "Merged_Target" 4 "Coasted_Target" 3 "Updated_Target" 2 "New_Updated_Target" 1 "New_Target" 0 "No_Target" ;
VAL_ 1318 CAN_TX_TRACK_MED_RANGE_MODE 3 "Both_MR_LR_Update" 2 "LR_Update_Only" 1 "MR_Update_Only" 0 "No_MR_LR_Update" ;
VAL_ 1321 CAN_TX_TRACK_GROUPING_CHANGED 1 "GroupingChanged" 0 "GroupingUnchanged" ;
VAL_ 1321 CAN_TX_TRACK_ONCOMING 1 "Oncoming" 0 "NotOncoming" ;
VAL_ 1321 CAN_TX_TRACK_BRIDGE_OBJECT 1 "Bridge" 0 "Not_Bridge" ;
VAL_ 1321 CAN_TX_TRACK_STATUS 7 "New_Coasted_Target" 6 "Invalid_Coasted_Target" 5 "Merged_Target" 4 "Coasted_Target" 3 "Updated_Target" 2 "New_Updated_Target" 1 "New_Target" 0 "No_Target" ;
VAL_ 1321 CAN_TX_TRACK_MED_RANGE_MODE 3 "Both_MR_LR_Update" 2 "LR_Update_Only" 1 "MR_Update_Only" 0 "No_MR_LR_Update" ;
VAL_ 1320 CAN_TX_TRACK_GROUPING_CHANGED 1 "GroupingChanged" 0 "GroupingUnchanged" ;
VAL_ 1320 CAN_TX_TRACK_ONCOMING 1 "Oncoming" 0 "NotOncoming" ;
VAL_ 1320 CAN_TX_TRACK_BRIDGE_OBJECT 1 "Bridge" 0 "Not_Bridge" ;
VAL_ 1320 CAN_TX_TRACK_STATUS 7 "New_Coasted_Target" 6 "Invalid_Coasted_Target" 5 "Merged_Target" 4 "Coasted_Target" 3 "Updated_Target" 2 "New_Updated_Target" 1 "New_Target" 0 "No_Target" ;
VAL_ 1320 CAN_TX_TRACK_MED_RANGE_MODE 3 "Both_MR_LR_Update" 2 "LR_Update_Only" 1 "MR_Update_Only" 0 "No_MR_LR_Update" ;
VAL_ 1319 CAN_TX_TRACK_GROUPING_CHANGED 1 "GroupingChanged" 0 "GroupingUnchanged" ;
VAL_ 1319 CAN_TX_TRACK_ONCOMING 1 "Oncoming" 0 "NotOncoming" ;
VAL_ 1319 CAN_TX_TRACK_BRIDGE_OBJECT 1 "Bridge" 0 "Not_Bridge" ;
VAL_ 1319 CAN_TX_TRACK_STATUS 7 "New_Coasted_Target" 6 "Invalid_Coasted_Target" 5 "Merged_Target" 4 "Coasted_Target" 3 "Updated_Target" 2 "New_Updated_Target" 1 "New_Target" 0 "No_Target" ;
VAL_ 1319 CAN_TX_TRACK_MED_RANGE_MODE 3 "Both_MR_LR_Update" 2 "LR_Update_Only" 1 "MR_Update_Only" 0 "No_MR_LR_Update" ;
VAL_ 1323 CAN_TX_TRACK_GROUPING_CHANGED 1 "GroupingChanged" 0 "GroupingUnchanged" ;
VAL_ 1323 CAN_TX_TRACK_ONCOMING 1 "Oncoming" 0 "NotOncoming" ;
VAL_ 1323 CAN_TX_TRACK_BRIDGE_OBJECT 1 "Bridge" 0 "Not_Bridge" ;
VAL_ 1323 CAN_TX_TRACK_STATUS 7 "New_Coasted_Target" 6 "Invalid_Coasted_Target" 5 "Merged_Target" 4 "Coasted_Target" 3 "Updated_Target" 2 "New_Updated_Target" 1 "New_Target" 0 "No_Target" ;
VAL_ 1323 CAN_TX_TRACK_MED_RANGE_MODE 3 "Both_MR_LR_Update" 2 "LR_Update_Only" 1 "MR_Update_Only" 0 "No_MR_LR_Update" ;
VAL_ 1329 CAN_TX_TRACK_GROUPING_CHANGED 1 "GroupingChanged" 0 "GroupingUnchanged" ;
VAL_ 1329 CAN_TX_TRACK_ONCOMING 1 "Oncoming" 0 "NotOncoming" ;
VAL_ 1329 CAN_TX_TRACK_BRIDGE_OBJECT 1 "Bridge" 0 "Not_Bridge" ;
VAL_ 1329 CAN_TX_TRACK_STATUS 7 "New_Coasted_Target" 6 "Invalid_Coasted_Target" 5 "Merged_Target" 4 "Coasted_Target" 3 "Updated_Target" 2 "New_Updated_Target" 1 "New_Target" 0 "No_Target" ;
VAL_ 1329 CAN_TX_TRACK_MED_RANGE_MODE 3 "Both_MR_LR_Update" 2 "LR_Update_Only" 1 "MR_Update_Only" 0 "No_MR_LR_Update" ;
VAL_ 1326 CAN_TX_TRACK_GROUPING_CHANGED 1 "GroupingChanged" 0 "GroupingUnchanged" ;
VAL_ 1326 CAN_TX_TRACK_ONCOMING 1 "Oncoming" 0 "NotOncoming" ;
VAL_ 1326 CAN_TX_TRACK_BRIDGE_OBJECT 1 "Bridge" 0 "Not_Bridge" ;
VAL_ 1326 CAN_TX_TRACK_STATUS 7 "New_Coasted_Target" 6 "Invalid_Coasted_Target" 5 "Merged_Target" 4 "Coasted_Target" 3 "Updated_Target" 2 "New_Updated_Target" 1 "New_Target" 0 "No_Target" ;
VAL_ 1326 CAN_TX_TRACK_MED_RANGE_MODE 3 "Both_MR_LR_Update" 2 "LR_Update_Only" 1 "MR_Update_Only" 0 "No_MR_LR_Update" ;
VAL_ 1342 CAN_TX_TRACK_GROUPING_CHANGED 1 "GroupingChanged" 0 "GroupingUnchanged" ;
VAL_ 1342 CAN_TX_TRACK_ONCOMING 1 "Oncoming" 0 "NotOncoming" ;
VAL_ 1342 CAN_TX_TRACK_BRIDGE_OBJECT 1 "Bridge" 0 "Not_Bridge" ;
VAL_ 1342 CAN_TX_TRACK_STATUS 7 "New_Coasted_Target" 6 "Invalid_Coasted_Target" 5 "Merged_Target" 4 "Coasted_Target" 3 "Updated_Target" 2 "New_Updated_Target" 1 "New_Target" 0 "No_Target" ;
VAL_ 1342 CAN_TX_TRACK_MED_RANGE_MODE 3 "Both_MR_LR_Update" 2 "LR_Update_Only" 1 "MR_Update_Only" 0 "No_MR_LR_Update" ;
VAL_ 1340 CAN_TX_TRACK_GROUPING_CHANGED 1 "GroupingChanged" 0 "GroupingUnchanged" ;
VAL_ 1340 CAN_TX_TRACK_ONCOMING 1 "Oncoming" 0 "NotOncoming" ;
VAL_ 1340 CAN_TX_TRACK_BRIDGE_OBJECT 1 "Bridge" 0 "Not_Bridge" ;
VAL_ 1340 CAN_TX_TRACK_STATUS 7 "New_Coasted_Target" 6 "Invalid_Coasted_Target" 5 "Merged_Target" 4 "Coasted_Target" 3 "Updated_Target" 2 "New_Updated_Target" 1 "New_Target" 0 "No_Target" ;
VAL_ 1340 CAN_TX_TRACK_MED_RANGE_MODE 3 "Both_MR_LR_Update" 2 "LR_Update_Only" 1 "MR_Update_Only" 0 "No_MR_LR_Update" ;
VAL_ 1333 CAN_TX_TRACK_GROUPING_CHANGED 1 "GroupingChanged" 0 "GroupingUnchanged" ;
VAL_ 1333 CAN_TX_TRACK_ONCOMING 1 "Oncoming" 0 "NotOncoming" ;
VAL_ 1333 CAN_TX_TRACK_BRIDGE_OBJECT 1 "Bridge" 0 "Not_Bridge" ;
VAL_ 1333 CAN_TX_TRACK_STATUS 7 "New_Coasted_Target" 6 "Invalid_Coasted_Target" 5 "Merged_Target" 4 "Coasted_Target" 3 "Updated_Target" 2 "New_Updated_Target" 1 "New_Target" 0 "No_Target" ;
VAL_ 1333 CAN_TX_TRACK_MED_RANGE_MODE 3 "Both_MR_LR_Update" 2 "LR_Update_Only" 1 "MR_Update_Only" 0 "No_MR_LR_Update" ;
VAL_ 1335 CAN_TX_TRACK_GROUPING_CHANGED 1 "GroupingChanged" 0 "GroupingUnchanged" ;
VAL_ 1335 CAN_TX_TRACK_ONCOMING 1 "Oncoming" 0 "NotOncoming" ;
VAL_ 1335 CAN_TX_TRACK_BRIDGE_OBJECT 1 "Bridge" 0 "Not_Bridge" ;
VAL_ 1335 CAN_TX_TRACK_STATUS 7 "New_Coasted_Target" 6 "Invalid_Coasted_Target" 5 "Merged_Target" 4 "Coasted_Target" 3 "Updated_Target" 2 "New_Updated_Target" 1 "New_Target" 0 "No_Target" ;
VAL_ 1335 CAN_TX_TRACK_MED_RANGE_MODE 3 "Both_MR_LR_Update" 2 "LR_Update_Only" 1 "MR_Update_Only" 0 "No_MR_LR_Update" ;
VAL_ 1337 CAN_TX_TRACK_GROUPING_CHANGED 1 "GroupingChanged" 0 "GroupingUnchanged" ;
VAL_ 1337 CAN_TX_TRACK_ONCOMING 1 "Oncoming" 0 "NotOncoming" ;
VAL_ 1337 CAN_TX_TRACK_BRIDGE_OBJECT 1 "Bridge" 0 "Not_Bridge" ;
VAL_ 1337 CAN_TX_TRACK_STATUS 7 "New_Coasted_Target" 6 "Invalid_Coasted_Target" 5 "Merged_Target" 4 "Coasted_Target" 3 "Updated_Target" 2 "New_Updated_Target" 1 "New_Target" 0 "No_Target" ;
VAL_ 1337 CAN_TX_TRACK_MED_RANGE_MODE 3 "Both_MR_LR_Update" 2 "LR_Update_Only" 1 "MR_Update_Only" 0 "No_MR_LR_Update" ;
VAL_ 1331 CAN_TX_TRACK_GROUPING_CHANGED 1 "GroupingChanged" 0 "GroupingUnchanged" ;
VAL_ 1331 CAN_TX_TRACK_ONCOMING 1 "Oncoming" 0 "NotOncoming" ;
VAL_ 1331 CAN_TX_TRACK_BRIDGE_OBJECT 1 "Bridge" 0 "Not_Bridge" ;
VAL_ 1331 CAN_TX_TRACK_STATUS 7 "New_Coasted_Target" 6 "Invalid_Coasted_Target" 5 "Merged_Target" 4 "Coasted_Target" 3 "Updated_Target" 2 "New_Updated_Target" 1 "New_Target" 0 "No_Target" ;
VAL_ 1331 CAN_TX_TRACK_MED_RANGE_MODE 3 "Both_MR_LR_Update" 2 "LR_Update_Only" 1 "MR_Update_Only" 0 "No_MR_LR_Update" ;
VAL_ 1338 CAN_TX_TRACK_GROUPING_CHANGED 1 "GroupingChanged" 0 "GroupingUnchanged" ;
VAL_ 1338 CAN_TX_TRACK_ONCOMING 1 "Oncoming" 0 "NotOncoming" ;
VAL_ 1338 CAN_TX_TRACK_BRIDGE_OBJECT 1 "Bridge" 0 "Not_Bridge" ;
VAL_ 1338 CAN_TX_TRACK_STATUS 7 "New_Coasted_Target" 6 "Invalid_Coasted_Target" 5 "Merged_Target" 4 "Coasted_Target" 3 "Updated_Target" 2 "New_Updated_Target" 1 "New_Target" 0 "No_Target" ;
VAL_ 1338 CAN_TX_TRACK_MED_RANGE_MODE 3 "Both_MR_LR_Update" 2 "LR_Update_Only" 1 "MR_Update_Only" 0 "No_MR_LR_Update" ;
VAL_ 1336 CAN_TX_TRACK_GROUPING_CHANGED 1 "GroupingChanged" 0 "GroupingUnchanged" ;
VAL_ 1336 CAN_TX_TRACK_ONCOMING 1 "Oncoming" 0 "NotOncoming" ;
VAL_ 1336 CAN_TX_TRACK_BRIDGE_OBJECT 1 "Bridge" 0 "Not_Bridge" ;
VAL_ 1336 CAN_TX_TRACK_STATUS 7 "New_Coasted_Target" 6 "Invalid_Coasted_Target" 5 "Merged_Target" 4 "Coasted_Target" 3 "Updated_Target" 2 "New_Updated_Target" 1 "New_Target" 0 "No_Target" ;
VAL_ 1336 CAN_TX_TRACK_MED_RANGE_MODE 3 "Both_MR_LR_Update" 2 "LR_Update_Only" 1 "MR_Update_Only" 0 "No_MR_LR_Update" ;
VAL_ 1334 CAN_TX_TRACK_GROUPING_CHANGED 1 "GroupingChanged" 0 "GroupingUnchanged" ;
VAL_ 1334 CAN_TX_TRACK_ONCOMING 1 "Oncoming" 0 "NotOncoming" ;
VAL_ 1334 CAN_TX_TRACK_BRIDGE_OBJECT 1 "Bridge" 0 "Not_Bridge" ;
VAL_ 1334 CAN_TX_TRACK_STATUS 7 "New_Coasted_Target" 6 "Invalid_Coasted_Target" 5 "Merged_Target" 4 "Coasted_Target" 3 "Updated_Target" 2 "New_Updated_Target" 1 "New_Target" 0 "No_Target" ;
VAL_ 1334 CAN_TX_TRACK_MED_RANGE_MODE 3 "Both_MR_LR_Update" 2 "LR_Update_Only" 1 "MR_Update_Only" 0 "No_MR_LR_Update" ;
VAL_ 1330 CAN_TX_TRACK_GROUPING_CHANGED 1 "GroupingChanged" 0 "GroupingUnchanged" ;
VAL_ 1330 CAN_TX_TRACK_ONCOMING 1 "Oncoming" 0 "NotOncoming" ;
VAL_ 1330 CAN_TX_TRACK_BRIDGE_OBJECT 1 "Bridge" 0 "Not_Bridge" ;
VAL_ 1330 CAN_TX_TRACK_STATUS 7 "New_Coasted_Target" 6 "Invalid_Coasted_Target" 5 "Merged_Target" 4 "Coasted_Target" 3 "Updated_Target" 2 "New_Updated_Target" 1 "New_Target" 0 "No_Target" ;
VAL_ 1330 CAN_TX_TRACK_MED_RANGE_MODE 3 "Both_MR_LR_Update" 2 "LR_Update_Only" 1 "MR_Update_Only" 0 "No_MR_LR_Update" ;
VAL_ 1328 CAN_TX_TRACK_GROUPING_CHANGED 1 "GroupingChanged" 0 "GroupingUnchanged" ;
VAL_ 1328 CAN_TX_TRACK_ONCOMING 1 "Oncoming" 0 "NotOncoming" ;
VAL_ 1328 CAN_TX_TRACK_BRIDGE_OBJECT 1 "Bridge" 0 "Not_Bridge" ;
VAL_ 1328 CAN_TX_TRACK_STATUS 7 "New_Coasted_Target" 6 "Invalid_Coasted_Target" 5 "Merged_Target" 4 "Coasted_Target" 3 "Updated_Target" 2 "New_Updated_Target" 1 "New_Target" 0 "No_Target" ;
VAL_ 1328 CAN_TX_TRACK_MED_RANGE_MODE 3 "Both_MR_LR_Update" 2 "LR_Update_Only" 1 "MR_Update_Only" 0 "No_MR_LR_Update" ;
VAL_ 1282 CAN_TX_TRACK_GROUPING_CHANGED 1 "GroupingChanged" 0 "GroupingUnchanged" ;
VAL_ 1282 CAN_TX_TRACK_ONCOMING 1 "Oncoming" 0 "NotOncoming" ;
VAL_ 1282 CAN_TX_TRACK_BRIDGE_OBJECT 1 "Bridge" 0 "Not_Bridge" ;
VAL_ 1282 CAN_TX_TRACK_STATUS 7 "New_Coasted_Target" 6 "Invalid_Coasted_Target" 5 "Merged_Target" 4 "Coasted_Target" 3 "Updated_Target" 2 "New_Updated_Target" 1 "New_Target" 0 "No_Target" ;
VAL_ 1282 CAN_TX_TRACK_MED_RANGE_MODE 3 "Both_MR_LR_Update" 2 "LR_Update_Only" 1 "MR_Update_Only" 0 "No_MR_LR_Update" ;
VAL_ 1283 CAN_TX_TRACK_GROUPING_CHANGED 1 "GroupingChanged" 0 "GroupingUnchanged" ;
VAL_ 1283 CAN_TX_TRACK_ONCOMING 1 "Oncoming" 0 "NotOncoming" ;
VAL_ 1283 CAN_TX_TRACK_BRIDGE_OBJECT 1 "Bridge" 0 "Not_Bridge" ;
VAL_ 1283 CAN_TX_TRACK_STATUS 7 "New_Coasted_Target" 6 "Invalid_Coasted_Target" 5 "Merged_Target" 4 "Coasted_Target" 3 "Updated_Target" 2 "New_Updated_Target" 1 "New_Target" 0 "No_Target" ;
VAL_ 1283 CAN_TX_TRACK_MED_RANGE_MODE 3 "Both_MR_LR_Update" 2 "LR_Update_Only" 1 "MR_Update_Only" 0 "No_MR_LR_Update" ;
VAL_ 1284 CAN_TX_TRACK_GROUPING_CHANGED 1 "GroupingChanged" 0 "GroupingUnchanged" ;
VAL_ 1284 CAN_TX_TRACK_ONCOMING 1 "Oncoming" 0 "NotOncoming" ;
VAL_ 1284 CAN_TX_TRACK_BRIDGE_OBJECT 1 "Bridge" 0 "Not_Bridge" ;
VAL_ 1284 CAN_TX_TRACK_STATUS 7 "New_Coasted_Target" 6 "Invalid_Coasted_Target" 5 "Merged_Target" 4 "Coasted_Target" 3 "Updated_Target" 2 "New_Updated_Target" 1 "New_Target" 0 "No_Target" ;
VAL_ 1284 CAN_TX_TRACK_MED_RANGE_MODE 3 "Both_MR_LR_Update" 2 "LR_Update_Only" 1 "MR_Update_Only" 0 "No_MR_LR_Update" ;
VAL_ 1311 CAN_TX_TRACK_GROUPING_CHANGED 1 "GroupingChanged" 0 "GroupingUnchanged" ;
VAL_ 1311 CAN_TX_TRACK_ONCOMING 1 "Oncoming" 0 "NotOncoming" ;
VAL_ 1311 CAN_TX_TRACK_BRIDGE_OBJECT 1 "Bridge" 0 "Not_Bridge" ;
VAL_ 1311 CAN_TX_TRACK_STATUS 7 "New_Coasted_Target" 6 "Invalid_Coasted_Target" 5 "Merged_Target" 4 "Coasted_Target" 3 "Updated_Target" 2 "New_Updated_Target" 1 "New_Target" 0 "No_Target" ;
VAL_ 1311 CAN_TX_TRACK_MED_RANGE_MODE 3 "Both_MR_LR_Update" 2 "LR_Update_Only" 1 "MR_Update_Only" 0 "No_MR_LR_Update" ;
VAL_ 1290 CAN_TX_TRACK_GROUPING_CHANGED 1 "GroupingChanged" 0 "GroupingUnchanged" ;
VAL_ 1290 CAN_TX_TRACK_ONCOMING 1 "Oncoming" 0 "NotOncoming" ;
VAL_ 1290 CAN_TX_TRACK_BRIDGE_OBJECT 1 "Bridge" 0 "Not_Bridge" ;
VAL_ 1290 CAN_TX_TRACK_STATUS 7 "New_Coasted_Target" 6 "Invalid_Coasted_Target" 5 "Merged_Target" 4 "Coasted_Target" 3 "Updated_Target" 2 "New_Updated_Target" 1 "New_Target" 0 "No_Target" ;
VAL_ 1290 CAN_TX_TRACK_MED_RANGE_MODE 3 "Both_MR_LR_Update" 2 "LR_Update_Only" 1 "MR_Update_Only" 0 "No_MR_LR_Update" ;
VAL_ 1293 CAN_TX_TRACK_GROUPING_CHANGED 1 "GroupingChanged" 0 "GroupingUnchanged" ;
VAL_ 1293 CAN_TX_TRACK_ONCOMING 1 "Oncoming" 0 "NotOncoming" ;
VAL_ 1293 CAN_TX_TRACK_BRIDGE_OBJECT 1 "Bridge" 0 "Not_Bridge" ;
VAL_ 1293 CAN_TX_TRACK_STATUS 7 "New_Coasted_Target" 6 "Invalid_Coasted_Target" 5 "Merged_Target" 4 "Coasted_Target" 3 "Updated_Target" 2 "New_Updated_Target" 1 "New_Target" 0 "No_Target" ;
VAL_ 1293 CAN_TX_TRACK_MED_RANGE_MODE 3 "Both_MR_LR_Update" 2 "LR_Update_Only" 1 "MR_Update_Only" 0 "No_MR_LR_Update" ;
VAL_ 1325 CAN_TX_TRACK_GROUPING_CHANGED 1 "GroupingChanged" 0 "GroupingUnchanged" ;
VAL_ 1325 CAN_TX_TRACK_ONCOMING 1 "Oncoming" 0 "NotOncoming" ;
VAL_ 1325 CAN_TX_TRACK_BRIDGE_OBJECT 1 "Bridge" 0 "Not_Bridge" ;
VAL_ 1325 CAN_TX_TRACK_STATUS 7 "New_Coasted_Target" 6 "Invalid_Coasted_Target" 5 "Merged_Target" 4 "Coasted_Target" 3 "Updated_Target" 2 "New_Updated_Target" 1 "New_Target" 0 "No_Target" ;
VAL_ 1325 CAN_TX_TRACK_MED_RANGE_MODE 3 "Both_MR_LR_Update" 2 "LR_Update_Only" 1 "MR_Update_Only" 0 "No_MR_LR_Update" ;
VAL_ 1341 CAN_TX_TRACK_GROUPING_CHANGED 1 "GroupingChanged" 0 "GroupingUnchanged" ;
VAL_ 1341 CAN_TX_TRACK_ONCOMING 1 "Oncoming" 0 "NotOncoming" ;
VAL_ 1341 CAN_TX_TRACK_BRIDGE_OBJECT 1 "Bridge" 0 "Not_Bridge" ;
VAL_ 1341 CAN_TX_TRACK_STATUS 7 "New_Coasted_Target" 6 "Invalid_Coasted_Target" 5 "Merged_Target" 4 "Coasted_Target" 3 "Updated_Target" 2 "New_Updated_Target" 1 "New_Target" 0 "No_Target" ;
VAL_ 1341 CAN_TX_TRACK_MED_RANGE_MODE 3 "Both_MR_LR_Update" 2 "LR_Update_Only" 1 "MR_Update_Only" 0 "No_MR_LR_Update" ;
VAL_ 1281 CAN_TX_TRACK_GROUPING_CHANGED 1 "GroupingChanged" 0 "GroupingUnchanged" ;
VAL_ 1281 CAN_TX_TRACK_ONCOMING 1 "Oncoming" 0 "NotOncoming" ;
VAL_ 1281 CAN_TX_TRACK_BRIDGE_OBJECT 1 "Bridge" 0 "Not_Bridge" ;
VAL_ 1281 CAN_TX_TRACK_STATUS 7 "New_Coasted_Target" 6 "Invalid_Coasted_Target" 5 "Merged_Target" 4 "Coasted_Target" 3 "Updated_Target" 2 "New_Updated_Target" 1 "New_Target" 0 "No_Target" ;
VAL_ 1281 CAN_TX_TRACK_MED_RANGE_MODE 3 "Both_MR_LR_Update" 2 "LR_Update_Only" 1 "MR_Update_Only" 0 "No_MR_LR_Update" ;
VAL_ 1524 CAN_RX_YAW_RATE_BIAS_SHIFT 1 "Detect" 0 "No_Detect" ;
VAL_ 1523 CAN_RX_FAC_ALIGN_CMD_2 1 "On" 0 "Off" ;
VAL_ 1523 CAN_RX_FAC_ALIGN_CMD_1 1 "On" 0 "Off" ;
VAL_ 1522 CAN_RX_SERV_ALIGN_TYPE 1 "VOLVO_SHORT_TRACK" 0 "AUTO_OR_DEALER" ;
VAL_ 1522 CAN_RX_SERV_ALIGN_ENABLE 1 "Enabled" 0 "Disabled" ;
VAL_ 1522 CAN_RX_AUTO_ALIGN_CONVERGED 1 "Converged" 0 "Not_Converged" ;
VAL_ 1522 CAN_RX_AUTO_ALIGN_DISABLE 1 "Disabled" 0 "Enabled" ;
VAL_ 1522 CAN_RX_WHEEL_SLIP 3 "Invalid_3" 2 "Traction_Slip_Control" 1 "Brake_Slip_Control" 0 "No_Control" ;
VAL_ 1522 CAN_RX_LONG_ACCEL_VALIDITY 1 "Valid" 0 "Invalid" ;
VAL_ 1522 CAN_RX_LAT_ACCEL_VALIDITY 1 "Valid" 0 "Invalid" ;
VAL_ 1509 CAN_TX_VERTICAL_ALIGN_UPDATED 1 "Updated" 0 "Not_Updated" ;
VAL_ 1509 CAN_TX_FOUND_TARGET 1 "Found" 0 "Not_Found" ;
VAL_ 1509 CAN_TX_FACTORY_ALIGN_STATUS_2 5 "FAIL_VAR_TOO_LARGE" 4 "FAIL_DEV_TOO_LARGE" 3 "FAIL_NO_TARGET" 2 "SUCCESS" 1 "BUSY" 0 "OFF" ;
VAL_ 1509 CAN_TX_FACTORY_ALIGN_STATUS_1 5 "FAIL_VAR_TOO_LARGE" 4 "FAIL_DEV_TOO_LARGE" 3 "FAIL_NO_TARGET" 2 "SUCCESS" 1 "BUSY" 0 "OFF" ;
VAL_ 1509 CAN_TX_RECOMMEND_UNCONVERGE 1 "Recommend" 0 "Not_Recommend" ;
VAL_ 1509 CAN_TX_SYSTEM_POWER_MODE 7 "7invalid" 6 "TEST" 5 "HOST_SHUTDOWN" 4 "DSP_OFF" 3 "DSP_SHUTDOWN" 2 "RADIATE_ON" 1 "RADIATE_OFF" 0 "DSP_INIT" ;
VAL_ 1344 CAN_TX_TRACK_MOVABLE_SLOW64 1 "Movable" 0 "Not_Movable" ;
VAL_ 1344 CAN_TX_TRACK_MOVING64 1 "Moving" 0 "Stationary" ;
VAL_ 1344 CAN_TX_TRACK_MOVABLE_FAST64 1 "Movable" 0 "Not_Movable" ;
VAL_ 1344 CAN_TX_TRACK_MOVABLE_SLOW63 1 "Movable" 0 "Not_Movable" ;
VAL_ 1344 CAN_TX_TRACK_MOVABLE_SLOW62 1 "Movable" 0 "Not_Movable" ;
VAL_ 1344 CAN_TX_TRACK_MOVABLE_SLOW61 1 "Movable" 0 "Not_Movable" ;
VAL_ 1344 CAN_TX_TRACK_MOVABLE_SLOW60 1 "Movable" 0 "Not_Movable" ;
VAL_ 1344 CAN_TX_TRACK_MOVING63 1 "Moving" 0 "Stationary" ;
VAL_ 1344 CAN_TX_TRACK_MOVING62 1 "Moving" 0 "Stationary" ;
VAL_ 1344 CAN_TX_TRACK_MOVING61 1 "Moving" 0 "Stationary" ;
VAL_ 1344 CAN_TX_TRACK_MOVING60 1 "Moving" 0 "Stationary" ;
VAL_ 1344 CAN_TX_TRACK_MOVABLE_FAST63 1 "Movable" 0 "Not_Movable" ;
VAL_ 1344 CAN_TX_TRACK_MOVABLE_FAST62 1 "Movable" 0 "Not_Movable" ;
VAL_ 1344 CAN_TX_TRACK_MOVABLE_FAST61 1 "Movable" 0 "Not_Movable" ;
VAL_ 1344 CAN_TX_TRACK_MOVABLE_FAST60 1 "Movable" 0 "Not_Movable" ;
VAL_ 1344 CAN_TX_TRACK_MOVABLE_SLOW49 1 "Movable" 0 "Not_Movable" ;
VAL_ 1344 CAN_TX_TRACK_MOVABLE_SLOW48 1 "Movable" 0 "Not_Movable" ;
VAL_ 1344 CAN_TX_TRACK_MOVABLE_SLOW47 1 "Movable" 0 "Not_Movable" ;
VAL_ 1344 CAN_TX_TRACK_MOVABLE_SLOW46 1 "Movable" 0 "Not_Movable" ;
VAL_ 1344 CAN_TX_TRACK_MOVABLE_SLOW45 1 "Movable" 0 "Not_Movable" ;
VAL_ 1344 CAN_TX_TRACK_MOVABLE_SLOW44 1 "Movable" 0 "Not_Movable" ;
VAL_ 1344 CAN_TX_TRACK_MOVABLE_SLOW43 1 "Movable" 0 "Not_Movable" ;
VAL_ 1344 CAN_TX_TRACK_MOVING49 1 "Moving" 0 "Stationary" ;
VAL_ 1344 CAN_TX_TRACK_MOVING48 1 "Moving" 0 "Stationary" ;
VAL_ 1344 CAN_TX_TRACK_MOVING47 1 "Moving" 0 "Stationary" ;
VAL_ 1344 CAN_TX_TRACK_MOVING46 1 "Moving" 0 "Stationary" ;
VAL_ 1344 CAN_TX_TRACK_MOVING45 1 "Moving" 0 "Stationary" ;
VAL_ 1344 CAN_TX_TRACK_MOVING44 1 "Moving" 0 "Stationary" ;
VAL_ 1344 CAN_TX_TRACK_MOVING43 1 "Moving" 0 "Stationary" ;
VAL_ 1344 CAN_TX_TRACK_MOVABLE_FAST49 1 "Movable" 0 "Not_Movable" ;
VAL_ 1344 CAN_TX_TRACK_MOVABLE_FAST48 1 "Movable" 0 "Not_Movable" ;
VAL_ 1344 CAN_TX_TRACK_MOVABLE_FAST47 1 "Movable" 0 "Not_Movable" ;
VAL_ 1344 CAN_TX_TRACK_MOVABLE_FAST46 1 "Movable" 0 "Not_Movable" ;
VAL_ 1344 CAN_TX_TRACK_MOVABLE_FAST45 1 "Movable" 0 "Not_Movable" ;
VAL_ 1344 CAN_TX_TRACK_MOVABLE_FAST44 1 "Movable" 0 "Not_Movable" ;
VAL_ 1344 CAN_TX_TRACK_MOVABLE_FAST43 1 "Movable" 0 "Not_Movable" ;
VAL_ 1344 CAN_TX_TRACK_MOVABLE_SLOW42 1 "Movable" 0 "Not_Movable" ;
VAL_ 1344 CAN_TX_TRACK_MOVABLE_SLOW41 1 "Movable" 0 "Not_Movable" ;
VAL_ 1344 CAN_TX_TRACK_MOVABLE_SLOW40 1 "Movable" 0 "Not_Movable" ;
VAL_ 1344 CAN_TX_TRACK_MOVABLE_SLOW39 1 "Movable" 0 "Not_Movable" ;
VAL_ 1344 CAN_TX_TRACK_MOVABLE_SLOW38 1 "Movable" 0 "Not_Movable" ;
VAL_ 1344 CAN_TX_TRACK_MOVABLE_SLOW37 1 "Movable" 0 "Not_Movable" ;
VAL_ 1344 CAN_TX_TRACK_MOVABLE_SLOW36 1 "Movable" 0 "Not_Movable" ;
VAL_ 1344 CAN_TX_TRACK_MOVING42 1 "Moving" 0 "Stationary" ;
VAL_ 1344 CAN_TX_TRACK_MOVING41 1 "Moving" 0 "Stationary" ;
VAL_ 1344 CAN_TX_TRACK_MOVING40 1 "Moving" 0 "Stationary" ;
VAL_ 1344 CAN_TX_TRACK_MOVING39 1 "Moving" 0 "Stationary" ;
VAL_ 1344 CAN_TX_TRACK_MOVING38 1 "Moving" 0 "Stationary" ;
VAL_ 1344 CAN_TX_TRACK_MOVING37 1 "Moving" 0 "Stationary" ;
VAL_ 1344 CAN_TX_TRACK_MOVING36 1 "Moving" 0 "Stationary" ;
VAL_ 1344 CAN_TX_TRACK_MOVABLE_FAST42 1 "Movable" 0 "Not_Movable" ;
VAL_ 1344 CAN_TX_TRACK_MOVABLE_FAST41 1 "Movable" 0 "Not_Movable" ;
VAL_ 1344 CAN_TX_TRACK_MOVABLE_FAST40 1 "Movable" 0 "Not_Movable" ;
VAL_ 1344 CAN_TX_TRACK_MOVABLE_FAST39 1 "Movable" 0 "Not_Movable" ;
VAL_ 1344 CAN_TX_TRACK_MOVABLE_FAST38 1 "Movable" 0 "Not_Movable" ;
VAL_ 1344 CAN_TX_TRACK_MOVABLE_FAST37 1 "Movable" 0 "Not_Movable" ;
VAL_ 1344 CAN_TX_TRACK_MOVABLE_FAST36 1 "Movable" 0 "Not_Movable" ;
VAL_ 1344 CAN_TX_TRACK_MOVABLE_SLOW35 1 "Movable" 0 "Not_Movable" ;
VAL_ 1344 CAN_TX_TRACK_MOVABLE_SLOW34 1 "Movable" 0 "Not_Movable" ;
VAL_ 1344 CAN_TX_TRACK_MOVABLE_SLOW33 1 "Movable" 0 "Not_Movable" ;
VAL_ 1344 CAN_TX_TRACK_MOVABLE_SLOW32 1 "Movable" 0 "Not_Movable" ;
VAL_ 1344 CAN_TX_TRACK_MOVABLE_SLOW31 1 "Movable" 0 "Not_Movable" ;
VAL_ 1344 CAN_TX_TRACK_MOVABLE_SLOW30 1 "Movable" 0 "Not_Movable" ;
VAL_ 1344 CAN_TX_TRACK_MOVABLE_SLOW29 1 "Movable" 0 "Not_Movable" ;
VAL_ 1344 CAN_TX_TRACK_MOVING35 1 "Moving" 0 "Stationary" ;
VAL_ 1344 CAN_TX_TRACK_MOVING34 1 "Moving" 0 "Stationary" ;
VAL_ 1344 CAN_TX_TRACK_MOVING33 1 "Moving" 0 "Stationary" ;
VAL_ 1344 CAN_TX_TRACK_MOVING32 1 "Moving" 0 "Stationary" ;
VAL_ 1344 CAN_TX_TRACK_MOVING31 1 "Moving" 0 "Stationary" ;
VAL_ 1344 CAN_TX_TRACK_MOVING30 1 "Moving" 0 "Stationary" ;
VAL_ 1344 CAN_TX_TRACK_MOVING29 1 "Moving" 0 "Stationary" ;
VAL_ 1344 CAN_TX_TRACK_MOVABLE_FAST35 1 "Movable" 0 "Not_Movable" ;
VAL_ 1344 CAN_TX_TRACK_MOVABLE_FAST34 1 "Movable" 0 "Not_Movable" ;
VAL_ 1344 CAN_TX_TRACK_MOVABLE_FAST33 1 "Movable" 0 "Not_Movable" ;
VAL_ 1344 CAN_TX_TRACK_MOVABLE_FAST32 1 "Movable" 0 "Not_Movable" ;
VAL_ 1344 CAN_TX_TRACK_MOVABLE_FAST31 1 "Movable" 0 "Not_Movable" ;
VAL_ 1344 CAN_TX_TRACK_MOVABLE_FAST30 1 "Movable" 0 "Not_Movable" ;
VAL_ 1344 CAN_TX_TRACK_MOVABLE_FAST29 1 "Movable" 0 "Not_Movable" ;
VAL_ 1344 CAN_TX_TRACK_MOVABLE_SLOW28 1 "Movable" 0 "Not_Movable" ;
VAL_ 1344 CAN_TX_TRACK_MOVABLE_SLOW27 1 "Movable" 0 "Not_Movable" ;
VAL_ 1344 CAN_TX_TRACK_MOVABLE_SLOW26 1 "Movable" 0 "Not_Movable" ;
VAL_ 1344 CAN_TX_TRACK_MOVABLE_SLOW25 1 "Movable" 0 "Not_Movable" ;
VAL_ 1344 CAN_TX_TRACK_MOVABLE_SLOW24 1 "Movable" 0 "Not_Movable" ;
VAL_ 1344 CAN_TX_TRACK_MOVABLE_SLOW23 1 "Movable" 0 "Not_Movable" ;
VAL_ 1344 CAN_TX_TRACK_MOVABLE_SLOW22 1 "Movable" 0 "Not_Movable" ;
VAL_ 1344 CAN_TX_TRACK_MOVING28 1 "Moving" 0 "Stationary" ;
VAL_ 1344 CAN_TX_TRACK_MOVING27 1 "Moving" 0 "Stationary" ;
VAL_ 1344 CAN_TX_TRACK_MOVING26 1 "Moving" 0 "Stationary" ;
VAL_ 1344 CAN_TX_TRACK_MOVING25 1 "Moving" 0 "Stationary" ;
VAL_ 1344 CAN_TX_TRACK_MOVING24 1 "Moving" 0 "Stationary" ;
VAL_ 1344 CAN_TX_TRACK_MOVING23 1 "Moving" 0 "Stationary" ;
VAL_ 1344 CAN_TX_TRACK_MOVING22 1 "Moving" 0 "Stationary" ;
VAL_ 1344 CAN_TX_TRACK_MOVABLE_FAST28 1 "Movable" 0 "Not_Movable" ;
VAL_ 1344 CAN_TX_TRACK_MOVABLE_FAST27 1 "Movable" 0 "Not_Movable" ;
VAL_ 1344 CAN_TX_TRACK_MOVABLE_FAST26 1 "Movable" 0 "Not_Movable" ;
VAL_ 1344 CAN_TX_TRACK_MOVABLE_FAST25 1 "Movable" 0 "Not_Movable" ;
VAL_ 1344 CAN_TX_TRACK_MOVABLE_FAST24 1 "Movable" 0 "Not_Movable" ;
VAL_ 1344 CAN_TX_TRACK_MOVABLE_FAST23 1 "Movable" 0 "Not_Movable" ;
VAL_ 1344 CAN_TX_TRACK_MOVABLE_FAST22 1 "Movable" 0 "Not_Movable" ;
VAL_ 1344 CAN_TX_TRACK_MOVABLE_SLOW21 1 "Movable" 0 "Not_Movable" ;
VAL_ 1344 CAN_TX_TRACK_MOVABLE_SLOW20 1 "Movable" 0 "Not_Movable" ;
VAL_ 1344 CAN_TX_TRACK_MOVABLE_SLOW19 1 "Movable" 0 "Not_Movable" ;
VAL_ 1344 CAN_TX_TRACK_MOVABLE_SLOW18 1 "Movable" 0 "Not_Movable" ;
VAL_ 1344 CAN_TX_TRACK_MOVABLE_SLOW17 1 "Movable" 0 "Not_Movable" ;
VAL_ 1344 CAN_TX_TRACK_MOVABLE_SLOW16 1 "Movable" 0 "Not_Movable" ;
VAL_ 1344 CAN_TX_TRACK_MOVABLE_SLOW15 1 "Movable" 0 "Not_Movable" ;
VAL_ 1344 CAN_TX_TRACK_MOVING21 1 "Moving" 0 "Stationary" ;
VAL_ 1344 CAN_TX_TRACK_MOVING20 1 "Moving" 0 "Stationary" ;
VAL_ 1344 CAN_TX_TRACK_MOVING19 1 "Moving" 0 "Stationary" ;
VAL_ 1344 CAN_TX_TRACK_MOVING18 1 "Moving" 0 "Stationary" ;
VAL_ 1344 CAN_TX_TRACK_MOVING17 1 "Moving" 0 "Stationary" ;
VAL_ 1344 CAN_TX_TRACK_MOVING16 1 "Moving" 0 "Stationary" ;
VAL_ 1344 CAN_TX_TRACK_MOVING15 1 "Moving" 0 "Stationary" ;
VAL_ 1344 CAN_TX_TRACK_MOVABLE_FAST21 1 "Movable" 0 "Not_Movable" ;
VAL_ 1344 CAN_TX_TRACK_MOVABLE_FAST20 1 "Movable" 0 "Not_Movable" ;
VAL_ 1344 CAN_TX_TRACK_MOVABLE_FAST19 1 "Movable" 0 "Not_Movable" ;
VAL_ 1344 CAN_TX_TRACK_MOVABLE_FAST18 1 "Movable" 0 "Not_Movable" ;
VAL_ 1344 CAN_TX_TRACK_MOVABLE_FAST17 1 "Movable" 0 "Not_Movable" ;
VAL_ 1344 CAN_TX_TRACK_MOVABLE_FAST16 1 "Movable" 0 "Not_Movable" ;
VAL_ 1344 CAN_TX_TRACK_MOVABLE_FAST15 1 "Movable" 0 "Not_Movable" ;
VAL_ 1344 CAN_TX_TRACK_MOVABLE_SLOW14 1 "Movable" 0 "Not_Movable" ;
VAL_ 1344 CAN_TX_TRACK_MOVABLE_SLOW13 1 "Movable" 0 "Not_Movable" ;
VAL_ 1344 CAN_TX_TRACK_MOVABLE_SLOW12 1 "Movable" 0 "Not_Movable" ;
VAL_ 1344 CAN_TX_TRACK_MOVABLE_SLOW11 1 "Movable" 0 "Not_Movable" ;
VAL_ 1344 CAN_TX_TRACK_MOVABLE_SLOW10 1 "Movable" 0 "Not_Movable" ;
VAL_ 1344 CAN_TX_TRACK_MOVABLE_SLOW09 1 "Movable" 0 "Not_Movable" ;
VAL_ 1344 CAN_TX_TRACK_MOVABLE_SLOW08 1 "Movable" 0 "Not_Movable" ;
VAL_ 1344 CAN_TX_TRACK_MOVING14 1 "Moving" 0 "Stationary" ;
VAL_ 1344 CAN_TX_TRACK_MOVING13 1 "Moving" 0 "Stationary" ;
VAL_ 1344 CAN_TX_TRACK_MOVING12 1 "Moving" 0 "Stationary" ;
VAL_ 1344 CAN_TX_TRACK_MOVING11 1 "Moving" 0 "Stationary" ;
VAL_ 1344 CAN_TX_TRACK_MOVING10 1 "Moving" 0 "Stationary" ;
VAL_ 1344 CAN_TX_TRACK_MOVING09 1 "Moving" 0 "Stationary" ;
VAL_ 1344 CAN_TX_TRACK_MOVING08 1 "Moving" 0 "Stationary" ;
VAL_ 1344 CAN_TX_TRACK_MOVABLE_FAST14 1 "Movable" 0 "Not_Movable" ;
VAL_ 1344 CAN_TX_TRACK_MOVABLE_FAST13 1 "Movable" 0 "Not_Movable" ;
VAL_ 1344 CAN_TX_TRACK_MOVABLE_FAST12 1 "Movable" 0 "Not_Movable" ;
VAL_ 1344 CAN_TX_TRACK_MOVABLE_FAST11 1 "Movable" 0 "Not_Movable" ;
VAL_ 1344 CAN_TX_TRACK_MOVABLE_FAST10 1 "Movable" 0 "Not_Movable" ;
VAL_ 1344 CAN_TX_TRACK_MOVABLE_FAST09 1 "Movable" 0 "Not_Movable" ;
VAL_ 1344 CAN_TX_TRACK_MOVABLE_FAST08 1 "Movable" 0 "Not_Movable" ;
VAL_ 1344 CAN_TX_TRACK_MOVING07 1 "Moving" 0 "Stationary" ;
VAL_ 1344 CAN_TX_TRACK_MOVING06 1 "Moving" 0 "Stationary" ;
VAL_ 1344 CAN_TX_TRACK_MOVING05 1 "Moving" 0 "Stationary" ;
VAL_ 1344 CAN_TX_TRACK_MOVING04 1 "Moving" 0 "Stationary" ;
VAL_ 1344 CAN_TX_TRACK_MOVING03 1 "Moving" 0 "Stationary" ;
VAL_ 1344 CAN_TX_TRACK_MOVING02 1 "Moving" 0 "Stationary" ;
VAL_ 1344 CAN_TX_TRACK_MOVING01 1 "Moving" 0 "Stationary" ;
VAL_ 1344 CAN_TX_TRACK_MOVABLE_SLOW07 1 "Movable" 0 "Not_Movable" ;
VAL_ 1344 CAN_TX_TRACK_MOVABLE_SLOW06 1 "Movable" 0 "Not_Movable" ;
VAL_ 1344 CAN_TX_TRACK_MOVABLE_SLOW05 1 "Movable" 0 "Not_Movable" ;
VAL_ 1344 CAN_TX_TRACK_MOVABLE_SLOW04 1 "Movable" 0 "Not_Movable" ;
VAL_ 1344 CAN_TX_TRACK_MOVABLE_SLOW03 1 "Movable" 0 "Not_Movable" ;
VAL_ 1344 CAN_TX_TRACK_MOVABLE_SLOW02 1 "Movable" 0 "Not_Movable" ;
VAL_ 1344 CAN_TX_TRACK_MOVABLE_SLOW01 1 "Movable" 0 "Not_Movable" ;
VAL_ 1344 CAN_TX_TRACK_MOVABLE_FAST07 1 "Movable" 0 "Not_Movable" ;
VAL_ 1344 CAN_TX_TRACK_MOVABLE_FAST06 1 "Movable" 0 "Not_Movable" ;
VAL_ 1344 CAN_TX_TRACK_MOVABLE_FAST05 1 "Movable" 0 "Not_Movable" ;
VAL_ 1344 CAN_TX_TRACK_MOVABLE_FAST04 1 "Movable" 0 "Not_Movable" ;
VAL_ 1344 CAN_TX_TRACK_MOVABLE_FAST03 1 "Movable" 0 "Not_Movable" ;
VAL_ 1344 CAN_TX_TRACK_MOVABLE_FAST02 1 "Movable" 0 "Not_Movable" ;
VAL_ 1344 CAN_TX_TRACK_MOVABLE_FAST01 1 "Movable" 0 "Not_Movable" ;
VAL_ 1251 CAN_TX_TRUCK_TARGET_DET 1 "Detected" 0 "Not_Detected" ;
VAL_ 1251 CAN_TX_LR_ONLY_GRATING_LOBE_DET 1 "Detected" 0 "Not_Detected" ;
VAL_ 1251 CAN_TX_SIDELOBE_BLOCKAGE 1 "On" 0 "Off" ;
VAL_ 1251 CAN_TX_PARTIAL_BLOCKAGE 1 "Blocked" 0 "Not Blocked" ;
VAL_ 1251 CAN_TX_MR_LR_MODE 3 "Output all medium-range and long" 2 "Output only long-range tracks" 1 "Output only medium-range tracks" 0 "Reserved" ;
VAL_ 1472 CAN_RX_SIM_TRACK_ID 2 "Target_2" 1 "Target_1" 0 "No_Target" ;
VAL_ 1472 CAN_RX_SIM_STATUS 3 "Coasted" 2 "Updated" 1 "New" 0 "Invalid" ;
VAL_ 1472 CAN_RX_SIM_FUNCTION 7 "All_Stat_RI_FCW_CMbB" 6 "All_Moving_ACC_FCW_CMbB" 5 "CMbB_Stat" 4 "CMbB_Move" 3 "FCW_Stat" 2 "FCW_Move" 1 "RI" 0 "ACC" ;
VAL_ 1280 CAN_TX_TRACK_GROUPING_CHANGED 1 "GroupingChanged" 0 "GroupingUnchanged" ;
VAL_ 1280 CAN_TX_TRACK_ONCOMING 1 "Oncoming" 0 "NotOncoming" ;
VAL_ 1280 CAN_TX_TRACK_BRIDGE_OBJECT 1 "Bridge" 0 "Not_Bridge" ;
VAL_ 1280 CAN_TX_TRACK_STATUS 7 "New_Coasted_Target" 6 "Invalid_Coasted_Target" 5 "Merged_Target" 4 "Coasted_Target" 3 "Updated_Target" 2 "New_Updated_Target" 1 "New_Target" 0 "No_Target" ;
VAL_ 1280 CAN_TX_TRACK_MED_RANGE_MODE 3 "Both_MR_LR_Update" 2 "LR_Update_Only" 1 "MR_Update_Only" 0 "No_MR_LR_Update" ;
VAL_ 1249 CAN_TX_RAW_DATA_MODE 1 "Raw" 0 "Filtered" ;
VAL_ 1249 CAN_TX_RANGE_PERF_ERROR 1 "Blocked" 0 "Not Blocked" ;
VAL_ 1249 CAN_TX_OVERHEAT_ERROR 1 "OverTemp" 0 "Not OverTemp" ;
VAL_ 1249 CAN_TX_INTERNAL_ERROR 1 "Failed" 0 "Not Failed" ;
VAL_ 1249 CAN_TX_GROUPING_MODE 3 "Group_Moving_Stationary" 2 "Group_Stationary_Only" 1 "Group_Moving_Only" 0 "No_Grouping" ;
VAL_ 1249 CAN_TX_XCVR_OPERATIONAL 1 "On" 0 "Off" ;
VAL_ 1265 CAN_RX_MR_ONLY_TRANSMIT 1 "On" 0 "Off" ;
VAL_ 1265 CAN_RX_LR_ONLY_TRANSMIT 1 "On" 0 "Off" ;
VAL_ 1265 CAN_RX_CLEAR_FAULTS 1 "On" 0 "Off" ;
VAL_ 1265 CAN_RX_USE_ANGLE_MISALIGNMENT 1 "On" 0 "Off" ;
VAL_ 1265 CAN_RX_TURN_SIGNAL_STATUS 3 "Invalid_3" 2 "Right" 1 "Left" 0 "Off" ;
VAL_ 1265 CAN_RX_BLOCKAGE_DISABLE 1 "Disabled" 0 "Enabled" ;
VAL_ 1265 CAN_RX_VEHICLE_SPEED_VALIDITY 1 "Valid" 0 "Invalid" ;
VAL_ 1265 CAN_RX_MMR_UPSIDE_DOWN 1 "Upside_Down" 0 "Right_Side_Up" ;
VAL_ 1265 CAN_RX_WIPER_STATUS 1 "On" 0 "Off" ;
VAL_ 1265 CAN_RX_RAW_DATA_ENABLE 1 "Raw" 0 "Filtered" ;
VAL_ 1265 CAN_RX_RADAR_CMD_RADIATE 1 "On" 0 "Off" ;
VAL_ 1265 CAN_RX_GROUPING_MODE 3 "Group_Moving_Stationary" 2 "Group_Stationary_Only" 1 "Group_Moving_Only" 0 "No_Grouping" ;
VAL_ 1264 CAN_RX_STEERING_ANGLE_VALIDITY 1 "Valid" 0 "Invalid" ;
VAL_ 1264 CAN_RX_STEERING_ANGLE_SIGN 1 "Clockwise" 0 "Counterclockwise" ;
VAL_ 1264 CAN_RX_STEERING_ANGLE_RATE_SIGN 1 "Clockwise" 0 "Counterclockwise" ;
VAL_ 1264 CAN_RX_YAW_RATE_VALIDITY 1 "Valid" 0 "Invalid" ;
VAL_ 1264 CAN_RX_VEHICLE_SPEED_DIRECTION 1 "Reverse" 0 "Forward" ;
